[part 8 of 12: packages /Cluster to /E2E]
AUTOSAR XML (schema 4-3-0)
package /Cluster  (continued)
  can cluster BMC_CAN01: baudrate=500000, protocol-name=CAN, protocol-version=2.0, bus-off-recovery={bor-counter-l-1-to-l-2=1, bor-time-l-1=0.05, bor-time-l-2=0.2}  (continued)
    can physical channel CHNL: comm-connectors=CN_BMC_CAN01  (continued)
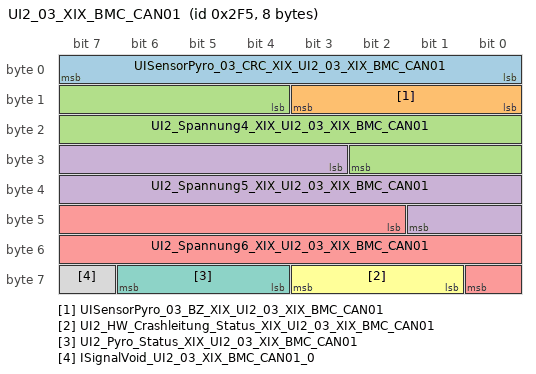
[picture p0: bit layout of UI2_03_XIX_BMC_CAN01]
      frame UI2_03_XIX_BMC_CAN01: id 0x2F5, to BMC_HV, frame-length=8, can-addressing-mode=STANDARD, can-frame-rx-behavior=CAN-20, can-frame-tx-behavior=CAN-20
        pdu UI2_03_XIX_BMC_CAN01_E2E: length=8, transmission-mode-true-timing=event-controlled-timing={number-of-repetitions=0, repetition-period=0}, unused-bit-pattern=0  # Fuer die Botschaft ist das Cyclic-Timing 0.01 zu verwenden.
          signal UISensorPyro_03_CRC_XIX_UI2_03_XIX_BMC_CAN01: start 0, 8 bit, little-endian, data-type-policy=OVERRIDE, i-signal-type=PRIMITIVE, init-value=0, base-type=BT_UISensorPyro_03_CRC, compu {phys=raw for raw 0..255}, range phys 0..255, raw 0..255, to BMC_HV(timeout 0.5 s)
          signal UISensorPyro_03_BZ_XIX_UI2_03_XIX_BMC_CAN01: start 8, 4 bit, little-endian, data-type-policy=OVERRIDE, i-signal-type=PRIMITIVE, init-value=0, base-type=BT_UISensorPyro_03_BZ, compu {phys=raw for raw 0..15}, range phys 0..15, raw 0..15, to BMC_HV(timeout 0.5 s)
          signal UI2_Spannung4_XIX_UI2_03_XIX_BMC_CAN01: start 12, 15 bit, little-endian, data-type-policy=OVERRIDE, i-signal-type=PRIMITIVE, init-value=32766, base-type=BT_UI2_Spannung4, invalid-value=Invalid_UI2_Spannung4_XIX_UI2_03_XIX_BMC_CAN01:32767, compu {phys=raw*0.0625-1023 for raw 0..32763, 32764=Cx7ffc_nicht_messbar (CM_UI2_Spannung4_Cx7ffc_nicht_messbar), 32765=Cx7ffd_nicht_verfuegbar (CM_UI2_Spannung4_Cx7ffd_nicht_verfuegbar), 32766=Cx7ffe_Init (CM_UI2_Spannung4_Cx7ffe_Init), 32767=Cx7fff_Fehler (CM_UI2_Spannung4_Cx7fff_Fehler); unit Unit_Volt}, range phys -1023..1024.6875 Unit_Volt, raw 0..32767, unit=Unit_Volt, to BMC_HV(timeout 0.5 s)  # Spannungsmesskanal 4
          signal UI2_Spannung5_XIX_UI2_03_XIX_BMC_CAN01: start 27, 15 bit, little-endian, data-type-policy=OVERRIDE, i-signal-type=PRIMITIVE, init-value=32766, base-type=BT_UI2_Spannung5, invalid-value=Invalid_UI2_Spannung5_XIX_UI2_03_XIX_BMC_CAN01:32767, compu {phys=raw*0.0625-1023 for raw 0..32763, 32764=Cx7ffc_nicht_messbar (CM_UI2_Spannung5_Cx7ffc_nicht_messbar), 32765=Cx7ffd_nicht_verfuegbar (CM_UI2_Spannung5_Cx7ffd_nicht_verfuegbar), 32766=Cx7ffe_Init (CM_UI2_Spannung5_Cx7ffe_Init), 32767=Cx7fff_Fehler (CM_UI2_Spannung5_Cx7fff_Fehler); unit Unit_Volt}, range phys -1023..1024.6875 Unit_Volt, raw 0..32767, unit=Unit_Volt, to BMC_HV(timeout 0.5 s)  # Spannungsmesskanal 5
          signal UI2_Spannung6_XIX_UI2_03_XIX_BMC_CAN01: start 42, 15 bit, little-endian, data-type-policy=OVERRIDE, i-signal-type=PRIMITIVE, init-value=32766, base-type=BT_UI2_Spannung6, invalid-value=Invalid_UI2_Spannung6_XIX_UI2_03_XIX_BMC_CAN01:32767, compu {phys=raw*0.0625-1023 for raw 0..32763, 32764=Cx7ffc_nicht_messbar (CM_UI2_Spannung6_Cx7ffc_nicht_messbar), 32765=Cx7ffd_nicht_verfuegbar (CM_UI2_Spannung6_Cx7ffd_nicht_verfuegbar), 32766=Cx7ffe_Init (CM_UI2_Spannung6_Cx7ffe_Init), 32767=Cx7fff_Fehler (CM_UI2_Spannung6_Cx7fff_Fehler); unit Unit_Volt}, range phys -1023..1024.6875 Unit_Volt, raw 0..32767, unit=Unit_Volt, to BMC_HV(timeout 0.5 s)  # Spannungsmesskanal 6
          signal UI2_HW_Crashleitung_Status_XIX_UI2_03_XIX_BMC_CAN01: start 57, 3 bit, little-endian, data-type-policy=OVERRIDE, i-signal-type=PRIMITIVE, init-value=0, base-type=BT_UI2_HW_Crashleitung_Status, invalid-value=Invalid_UI2_HW_Crashleitung_Status_XIX_UI2_03_XIX_BMC_CAN01:1, compu {0=Cx0_Init (CM_UI2_HW_Crashleitung_Status_Cx0_Init), 1=Cx1_Fehler (CM_UI2_HW_Crashleitung_Status_Cx1_Fehler), 2=Cx2_iO (CM_UI2_HW_Crashleitung_Status_Cx2_iO), 3=Cx3_Funktion_ausgeloest (CM_UI2_HW_Crashleitung_Status_Cx3_Funktion_ausgeloest)}, range raw 0..3, to BMC_HV(timeout 0.5 s)  # Status der HW-Crashleitung
          signal UI2_Pyro_Status_XIX_UI2_03_XIX_BMC_CAN01: start 60, 3 bit, little-endian, data-type-policy=OVERRIDE, i-signal-type=PRIMITIVE, init-value=0, base-type=BT_UI2_Pyro_Status, invalid-value=Invalid_UI2_Pyro_Status_XIX_UI2_03_XIX_BMC_CAN01:1, compu {0=Cx0_Init (CM_UI2_Pyro_Status_Cx0_Init), 1=Cx1_Fehler (CM_UI2_Pyro_Status_Cx1_Fehler), 2=Cx2_Funktion_verfuegbar (CM_UI2_Pyro_Status_Cx2_Funktion_verfuegbar), 3=Cx3_Funktion_ausgeloest (CM_UI2_Pyro_Status_Cx3_Funktion_ausgeloest), 4=Cx4_Funktion_zuendfaehig (CM_UI2_Pyro_Status_Cx4_Funktion_zuendfaehig)}, range raw 0..4, to BMC_HV(timeout 0.5 s)  # Status für Pyrotrenner
          signal ISignalVoid_UI2_03_XIX_BMC_CAN01_0: start 63, 1 bit, little-endian, system signal SignalVoid_UI2_03_0, data-type-policy=OVERRIDE, i-signal-type=PRIMITIVE, base-type=BT_SignalVoid
          mapping SG_UI2_03_XIX_BMC_CAN01: i-signal-group=SG_UI2_03_XIX_BMC_CAN01, transfer-property=TRIGGERED-WITHOUT-REPETITION
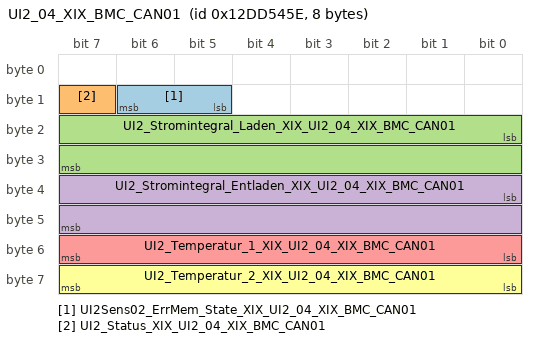
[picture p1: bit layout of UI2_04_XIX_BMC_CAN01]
      frame UI2_04_XIX_BMC_CAN01: id 0x12DD545E, to BMC_HV, frame-length=8, can-addressing-mode=EXTENDED, can-frame-rx-behavior=CAN-20, can-frame-tx-behavior=CAN-20
        pdu UI2_04_XIX_BMC_CAN01: length=8, transmission-mode-true-timing=cyclic-timing={time-offset=0, time-period=0.1}, unused-bit-pattern=0
          signal UI2Sens02_ErrMem_State_XIX_UI2_04_XIX_BMC_CAN01: start 13, 2 bit, little-endian, data-type-policy=OVERRIDE, i-signal-type=PRIMITIVE, init-value=2, base-type=BT_UI2Sens02_ErrMem_State, compu {1=Cx1_ErrMem_Active (CM_UI2Sens02_ErrMem_State_Cx1_ErrMem_Active), 2=Cx2_ErrMem_Init_Progress (CM_UI2Sens02_ErrMem_State_Cx2_ErrMem_Init_Progress), 3=Cx3_ErrMem_Init_Done (CM_UI2Sens02_ErrMem_State_Cx3_ErrMem_Init_Done)}, range raw 1..3, transfer-property=PENDING, to BMC_HV(timeout 1 s)  # Error Memory State
          signal UI2_Status_XIX_UI2_04_XIX_BMC_CAN01: start 15, 1 bit, little-endian, data-type-policy=OVERRIDE, i-signal-type=PRIMITIVE, init-value=0, base-type=BT_UI2_Status, compu {0=Cx0_Init (CM_UI2_Status_Cx0_Init), 1=Cx1_Aktiv (CM_UI2_Status_Cx1_Aktiv)}, range raw 0..1, transfer-property=PENDING, to BMC_HV(timeout 1 s)  # dient zur Signalisierung Neustart oder Reset des UI-Sensors
          signal UI2_Stromintegral_Laden_XIX_UI2_04_XIX_BMC_CAN01: start 16, 16 bit, little-endian, data-type-policy=OVERRIDE, i-signal-type=PRIMITIVE, init-value=65534, base-type=BT_UI2_Stromintegral_Laden, invalid-value=Invalid_UI2_Stromintegral_Laden_XIX_UI2_04_XIX_BMC_CAN01:65535, compu {phys=raw for raw 0..65533, 65534=Cxfffe_Init (CM_UI2_Stromintegral_Laden_Cxfffe_Init), 65535=Cxffff_Fehler (CM_UI2_Stromintegral_Laden_Cxffff_Fehler); unit Unit_AmperSecon}, range phys 0..65533 Unit_AmperSecon, raw 0..65535, unit=Unit_AmperSecon, transfer-property=PENDING, to BMC_HV(timeout 1 s)  # Ladungszaehler des UI-Sensors fuer Laden
          signal UI2_Stromintegral_Entladen_XIX_UI2_04_XIX_BMC_CAN01: start 32, 16 bit, little-endian, data-type-policy=OVERRIDE, i-signal-type=PRIMITIVE, init-value=65534, base-type=BT_UI2_Stromintegral_Entladen, invalid-value=Invalid_UI2_Stromintegral_Entladen_XIX_UI2_04_XIX_BMC_CAN01:65535, compu {phys=raw for raw 0..65533, 65534=Cxfffe_Init (CM_UI2_Stromintegral_Entladen_Cxfffe_Init), 65535=Cxffff_Fehler (CM_UI2_Stromintegral_Entladen_Cxffff_Fehler); unit Unit_AmperSecon}, range phys 0..65533 Unit_AmperSecon, raw 0..65535, unit=Unit_AmperSecon, transfer-property=PENDING, to BMC_HV(timeout 1 s)  # Ladungszaehler des UI-Sensors fuer Entladen
          signal UI2_Temperatur_1_XIX_UI2_04_XIX_BMC_CAN01: start 48, 8 bit, little-endian, data-type-policy=OVERRIDE, i-signal-type=PRIMITIVE, init-value=254, base-type=BT_UI2_Temperatur_1, invalid-value=Invalid_UI2_Temperatur_1_XIX_UI2_04_XIX_BMC_CAN01:255, compu {phys=raw-40 for raw 0..252, 253=Cxfd_nicht_vorhanden (CM_UI2_Temperatur_1_Cxfd_nicht_vorhanden), 254=Cxfe_Init (CM_UI2_Temperatur_1_Cxfe_Init), 255=Cxff_Fehler (CM_UI2_Temperatur_1_Cxff_Fehler); unit Unit_DegreCelsi}, range phys -40..212 Unit_DegreCelsi, raw 0..255, unit=Unit_DegreCelsi, transfer-property=PENDING, to BMC_HV(timeout 1 s)  # Temperatur 1
          signal UI2_Temperatur_2_XIX_UI2_04_XIX_BMC_CAN01: start 56, 8 bit, little-endian, data-type-policy=OVERRIDE, i-signal-type=PRIMITIVE, init-value=254, base-type=BT_UI2_Temperatur_2, invalid-value=Invalid_UI2_Temperatur_2_XIX_UI2_04_XIX_BMC_CAN01:255, compu {phys=raw-40 for raw 0..252, 253=Cxfd_nicht_vorhanden (CM_UI2_Temperatur_2_Cxfd_nicht_vorhanden), 254=Cxfe_Init (CM_UI2_Temperatur_2_Cxfe_Init), 255=Cxff_Fehler (CM_UI2_Temperatur_2_Cxff_Fehler); unit Unit_DegreCelsi}, range phys -40..212 Unit_DegreCelsi, raw 0..255, unit=Unit_DegreCelsi, transfer-property=PENDING, to BMC_HV(timeout 1 s)  # Temperatur 2
      frame UI2_Komponentenfehler_01_XIX_BMC_CAN01: id 0x12DD5520, to BMC_HV, frame-length=8, can-addressing-mode=EXTENDED, can-frame-rx-behavior=CAN-20, can-frame-tx-behavior=CAN-20
        pdu UI2_Komponentenfehler_01_XIX_BMC_CAN01: length=8, transmission-mode-true-timing=cyclic-timing={time-offset=0, time-period=0.1}, unused-bit-pattern=0
          signal UI2_KompFehlerModus2_01_XIX_UI2_Komponentenfehler_01_XIX_BMC_CAN01: start 12, 2 bit, little-endian, data-type-policy=OVERRIDE, i-signal-type=PRIMITIVE, init-value=0, base-type=BT_UI2_KompFehlerModus2_01, compu {0=Cx0_TNCTOC (CM_UI2_KompFehlerModus2_01_Cx0_TNCTOC), 1=Cx1_TP_TC (CM_UI2_KompFehlerModus2_01_Cx1_TP_TC), 2=Cx2_TP_TC_WCMTL (CM_UI2_KompFehlerModus2_01_Cx2_TP_TC_WCMTL), 3=Cx3_TF_TC_Error (CM_UI2_KompFehlerModus2_01_Cx3_TF_TC_Error)}, range raw 0..3, transfer-property=PENDING, to BMC_HV(timeout 1 s)  # Übertragung OBD relevanter Fehlerpfade vom Secondary zum Primary Steuergerät. Zuordnung der generischen Komponentenfehler muss zwischen Sender und Empfänger abgestimmt werden
          signal UI2_KompFehlerModus2_02_XIX_UI2_Komponentenfehler_01_XIX_BMC_CAN01: start 14, 2 bit, little-endian, data-type-policy=OVERRIDE, i-signal-type=PRIMITIVE, init-value=0, base-type=BT_UI2_KompFehlerModus2_02, compu {0=Cx0_TNCTOC (CM_UI2_KompFehlerModus2_02_Cx0_TNCTOC), 1=Cx1_TP_TC (CM_UI2_KompFehlerModus2_02_Cx1_TP_TC), 2=Cx2_TP_TC_WCMTL (CM_UI2_KompFehlerModus2_02_Cx2_TP_TC_WCMTL), 3=Cx3_TF_TC_Error (CM_UI2_KompFehlerModus2_02_Cx3_TF_TC_Error)}, range raw 0..3, transfer-property=PENDING, to BMC_HV(timeout 1 s)  # Übertragung OBD relevanter Fehlerpfade vom Secondary zum Primary Steuergerät. Zuordnung der generischen Komponentenfehler muss zwischen Sender und Empfänger abgestimmt werden
          signal UI2_KompFehlerModus2_03_XIX_UI2_Komponentenfehler_01_XIX_BMC_CAN01: start 16, 2 bit, little-endian, data-type-policy=OVERRIDE, i-signal-type=PRIMITIVE, init-value=0, base-type=BT_UI2_KompFehlerModus2_03, compu {0=Cx0_TNCTOC (CM_UI2_KompFehlerModus2_03_Cx0_TNCTOC), 1=Cx1_TP_TC (CM_UI2_KompFehlerModus2_03_Cx1_TP_TC), 2=Cx2_TP_TC_WCMTL (CM_UI2_KompFehlerModus2_03_Cx2_TP_TC_WCMTL), 3=Cx3_TF_TC_Error (CM_UI2_KompFehlerModus2_03_Cx3_TF_TC_Error)}, range raw 0..3, transfer-property=PENDING, to BMC_HV(timeout 1 s)  # Übertragung OBD relevanter Fehlerpfade vom Secondary zum Primary Steuergerät. Zuordnung der generischen Komponentenfehler muss zwischen Sender und Empfänger abgestimmt werden
          signal UI2_KompFehlerModus2_04_XIX_UI2_Komponentenfehler_01_XIX_BMC_CAN01: start 18, 2 bit, little-endian, data-type-policy=OVERRIDE, i-signal-type=PRIMITIVE, init-value=0, base-type=BT_UI2_KompFehlerModus2_04, compu {0=Cx0_TNCTOC (CM_UI2_KompFehlerModus2_04_Cx0_TNCTOC), 1=Cx1_TP_TC (CM_UI2_KompFehlerModus2_04_Cx1_TP_TC), 2=Cx2_TP_TC_WCMTL (CM_UI2_KompFehlerModus2_04_Cx2_TP_TC_WCMTL), 3=Cx3_TF_TC_Error (CM_UI2_KompFehlerModus2_04_Cx3_TF_TC_Error)}, range raw 0..3, transfer-property=PENDING, to BMC_HV(timeout 1 s)  # Übertragung OBD relevanter Fehlerpfade vom Secondary zum Primary Steuergerät. Zuordnung der generischen Komponentenfehler muss zwischen Sender und Empfänger abgestimmt werden
          signal UI2_KompFehlerModus2_05_XIX_UI2_Komponentenfehler_01_XIX_BMC_CAN01: start 20, 2 bit, little-endian, data-type-policy=OVERRIDE, i-signal-type=PRIMITIVE, init-value=0, base-type=BT_UI2_KompFehlerModus2_05, compu {0=Cx0_TNCTOC (CM_UI2_KompFehlerModus2_05_Cx0_TNCTOC), 1=Cx1_TP_TC (CM_UI2_KompFehlerModus2_05_Cx1_TP_TC), 2=Cx2_TP_TC_WCMTL (CM_UI2_KompFehlerModus2_05_Cx2_TP_TC_WCMTL), 3=Cx3_TF_TC_Error (CM_UI2_KompFehlerModus2_05_Cx3_TF_TC_Error)}, range raw 0..3, transfer-property=PENDING, to BMC_HV(timeout 1 s)  # Übertragung OBD relevanter Fehlerpfade vom Secondary zum Primary Steuergerät. Zuordnung der generischen Komponentenfehler muss zwischen Sender und Empfänger abgestimmt werden
          signal UI2_KompFehlerModus2_06_XIX_UI2_Komponentenfehler_01_XIX_BMC_CAN01: start 22, 2 bit, little-endian, data-type-policy=OVERRIDE, i-signal-type=PRIMITIVE, init-value=0, base-type=BT_UI2_KompFehlerModus2_06, compu {0=Cx0_TNCTOC (CM_UI2_KompFehlerModus2_06_Cx0_TNCTOC), 1=Cx1_TP_TC (CM_UI2_KompFehlerModus2_06_Cx1_TP_TC), 2=Cx2_TP_TC_WCMTL (CM_UI2_KompFehlerModus2_06_Cx2_TP_TC_WCMTL), 3=Cx3_TF_TC_Error (CM_UI2_KompFehlerModus2_06_Cx3_TF_TC_Error)}, range raw 0..3, transfer-property=PENDING, to BMC_HV(timeout 1 s)  # Übertragung OBD relevanter Fehlerpfade vom Secondary zum Primary Steuergerät. Zuordnung der generischen Komponentenfehler muss zwischen Sender und Empfänger abgestimmt werden
          signal UI2_KompFehlerModus2_07_XIX_UI2_Komponentenfehler_01_XIX_BMC_CAN01: start 24, 2 bit, little-endian, data-type-policy=OVERRIDE, i-signal-type=PRIMITIVE, init-value=0, base-type=BT_UI2_KompFehlerModus2_07, compu {0=Cx0_TNCTOC (CM_UI2_KompFehlerModus2_07_Cx0_TNCTOC), 1=Cx1_TP_TC (CM_UI2_KompFehlerModus2_07_Cx1_TP_TC), 2=Cx2_TP_TC_WCMTL (CM_UI2_KompFehlerModus2_07_Cx2_TP_TC_WCMTL), 3=Cx3_TF_TC_Error (CM_UI2_KompFehlerModus2_07_Cx3_TF_TC_Error)}, range raw 0..3, transfer-property=PENDING, to BMC_HV(timeout 1 s)  # Übertragung OBD relevanter Fehlerpfade vom Secondary zum Primary Steuergerät. Zuordnung der generischen Komponentenfehler muss zwischen Sender und Empfänger abgestimmt werden
          signal UI2_KompFehlerModus2_08_XIX_UI2_Komponentenfehler_01_XIX_BMC_CAN01: start 26, 2 bit, little-endian, data-type-policy=OVERRIDE, i-signal-type=PRIMITIVE, init-value=0, base-type=BT_UI2_KompFehlerModus2_08, compu {0=Cx0_TNCTOC (CM_UI2_KompFehlerModus2_08_Cx0_TNCTOC), 1=Cx1_TP_TC (CM_UI2_KompFehlerModus2_08_Cx1_TP_TC), 2=Cx2_TP_TC_WCMTL (CM_UI2_KompFehlerModus2_08_Cx2_TP_TC_WCMTL), 3=Cx3_TF_TC_Error (CM_UI2_KompFehlerModus2_08_Cx3_TF_TC_Error)}, range raw 0..3, transfer-property=PENDING, to BMC_HV(timeout 1 s)  # Übertragung OBD relevanter Fehlerpfade vom Secondary zum Primary Steuergerät. Zuordnung der generischen Komponentenfehler muss zwischen Sender und Empfänger abgestimmt werden
          signal UI2_KompFehlerModus2_09_XIX_UI2_Komponentenfehler_01_XIX_BMC_CAN01: start 28, 2 bit, little-endian, data-type-policy=OVERRIDE, i-signal-type=PRIMITIVE, init-value=0, base-type=BT_UI2_KompFehlerModus2_09, compu {0=Cx0_TNCTOC (CM_UI2_KompFehlerModus2_09_Cx0_TNCTOC), 1=Cx1_TP_TC (CM_UI2_KompFehlerModus2_09_Cx1_TP_TC), 2=Cx2_TP_TC_WCMTL (CM_UI2_KompFehlerModus2_09_Cx2_TP_TC_WCMTL), 3=Cx3_TF_TC_Error (CM_UI2_KompFehlerModus2_09_Cx3_TF_TC_Error)}, range raw 0..3, transfer-property=PENDING, to BMC_HV(timeout 1 s)  # Übertragung OBD relevanter Fehlerpfade vom Secondary zum Primary Steuergerät. Zuordnung der generischen Komponentenfehler muss zwischen Sender und Empfänger abgestimmt werden
          signal UI2_KompFehlerModus2_10_XIX_UI2_Komponentenfehler_01_XIX_BMC_CAN01: start 30, 2 bit, little-endian, data-type-policy=OVERRIDE, i-signal-type=PRIMITIVE, init-value=0, base-type=BT_UI2_KompFehlerModus2_10, compu {0=Cx0_TNCTOC (CM_UI2_KompFehlerModus2_10_Cx0_TNCTOC), 1=Cx1_TP_TC (CM_UI2_KompFehlerModus2_10_Cx1_TP_TC), 2=Cx2_TP_TC_WCMTL (CM_UI2_KompFehlerModus2_10_Cx2_TP_TC_WCMTL), 3=Cx3_TF_TC_Error (CM_UI2_KompFehlerModus2_10_Cx3_TF_TC_Error)}, range raw 0..3, transfer-property=PENDING, to BMC_HV(timeout 1 s)  # Übertragung OBD relevanter Fehlerpfade vom Secondary zum Primary Steuergerät. Zuordnung der generischen Komponentenfehler muss zwischen Sender und Empfänger abgestimmt werden
          signal UI2_KompFehlerModus2_11_XIX_UI2_Komponentenfehler_01_XIX_BMC_CAN01: start 32, 2 bit, little-endian, data-type-policy=OVERRIDE, i-signal-type=PRIMITIVE, init-value=0, base-type=BT_UI2_KompFehlerModus2_11, compu {0=Cx0_TNCTOC (CM_UI2_KompFehlerModus2_11_Cx0_TNCTOC), 1=Cx1_TP_TC (CM_UI2_KompFehlerModus2_11_Cx1_TP_TC), 2=Cx2_TP_TC_WCMTL (CM_UI2_KompFehlerModus2_11_Cx2_TP_TC_WCMTL), 3=Cx3_TF_TC_Error (CM_UI2_KompFehlerModus2_11_Cx3_TF_TC_Error)}, range raw 0..3, transfer-property=PENDING, to BMC_HV(timeout 1 s)  # Übertragung OBD relevanter Fehlerpfade vom Secondary zum Primary Steuergerät. Zuordnung der generischen Komponentenfehler muss zwischen Sender und Empfänger abgestimmt werden
          signal UI2_KompFehlerModus2_12_XIX_UI2_Komponentenfehler_01_XIX_BMC_CAN01: start 34, 2 bit, little-endian, data-type-policy=OVERRIDE, i-signal-type=PRIMITIVE, init-value=0, base-type=BT_UI2_KompFehlerModus2_12, compu {0=Cx0_TNCTOC (CM_UI2_KompFehlerModus2_12_Cx0_TNCTOC), 1=Cx1_TP_TC (CM_UI2_KompFehlerModus2_12_Cx1_TP_TC), 2=Cx2_TP_TC_WCMTL (CM_UI2_KompFehlerModus2_12_Cx2_TP_TC_WCMTL), 3=Cx3_TF_TC_Error (CM_UI2_KompFehlerModus2_12_Cx3_TF_TC_Error)}, range raw 0..3, transfer-property=PENDING, to BMC_HV(timeout 1 s)  # Übertragung OBD relevanter Fehlerpfade vom Secondary zum Primary Steuergerät. Zuordnung der generischen Komponentenfehler muss zwischen Sender und Empfänger abgestimmt werden
          signal UI2_KompFehlerModus2_13_XIX_UI2_Komponentenfehler_01_XIX_BMC_CAN01: start 36, 2 bit, little-endian, data-type-policy=OVERRIDE, i-signal-type=PRIMITIVE, init-value=0, base-type=BT_UI2_KompFehlerModus2_13, compu {0=Cx0_TNCTOC (CM_UI2_KompFehlerModus2_13_Cx0_TNCTOC), 1=Cx1_TP_TC (CM_UI2_KompFehlerModus2_13_Cx1_TP_TC), 2=Cx2_TP_TC_WCMTL (CM_UI2_KompFehlerModus2_13_Cx2_TP_TC_WCMTL), 3=Cx3_TF_TC_Error (CM_UI2_KompFehlerModus2_13_Cx3_TF_TC_Error)}, range raw 0..3, transfer-property=PENDING, to BMC_HV(timeout 1 s)  # Übertragung OBD relevanter Fehlerpfade vom Secondary zum Primary Steuergerät. Zuordnung der generischen Komponentenfehler muss zwischen Sender und Empfänger abgestimmt werden
          signal UI2_KompFehlerModus2_14_XIX_UI2_Komponentenfehler_01_XIX_BMC_CAN01: start 38, 2 bit, little-endian, data-type-policy=OVERRIDE, i-signal-type=PRIMITIVE, init-value=0, base-type=BT_UI2_KompFehlerModus2_14, compu {0=Cx0_TNCTOC (CM_UI2_KompFehlerModus2_14_Cx0_TNCTOC), 1=Cx1_TP_TC (CM_UI2_KompFehlerModus2_14_Cx1_TP_TC), 2=Cx2_TP_TC_WCMTL (CM_UI2_KompFehlerModus2_14_Cx2_TP_TC_WCMTL), 3=Cx3_TF_TC_Error (CM_UI2_KompFehlerModus2_14_Cx3_TF_TC_Error)}, range raw 0..3, transfer-property=PENDING, to BMC_HV(timeout 1 s)  # Übertragung OBD relevanter Fehlerpfade vom Secondary zum Primary Steuergerät. Zuordnung der generischen Komponentenfehler muss zwischen Sender und Empfänger abgestimmt werden
          signal UI2_KompFehlerModus2_15_XIX_UI2_Komponentenfehler_01_XIX_BMC_CAN01: start 40, 2 bit, little-endian, data-type-policy=OVERRIDE, i-signal-type=PRIMITIVE, init-value=0, base-type=BT_UI2_KompFehlerModus2_15, compu {0=Cx0_TNCTOC (CM_UI2_KompFehlerModus2_15_Cx0_TNCTOC), 1=Cx1_TP_TC (CM_UI2_KompFehlerModus2_15_Cx1_TP_TC), 2=Cx2_TP_TC_WCMTL (CM_UI2_KompFehlerModus2_15_Cx2_TP_TC_WCMTL), 3=Cx3_TF_TC_Error (CM_UI2_KompFehlerModus2_15_Cx3_TF_TC_Error)}, range raw 0..3, transfer-property=PENDING, to BMC_HV(timeout 1 s)  # Übertragung OBD relevanter Fehlerpfade vom Secondary zum Primary Steuergerät. Zuordnung der generischen Komponentenfehler muss zwischen Sender und Empfänger abgestimmt werden
          signal UI2_KompFehlerModus2_16_XIX_UI2_Komponentenfehler_01_XIX_BMC_CAN01: start 42, 2 bit, little-endian, data-type-policy=OVERRIDE, i-signal-type=PRIMITIVE, init-value=0, base-type=BT_UI2_KompFehlerModus2_16, compu {0=Cx0_TNCTOC (CM_UI2_KompFehlerModus2_16_Cx0_TNCTOC), 1=Cx1_TP_TC (CM_UI2_KompFehlerModus2_16_Cx1_TP_TC), 2=Cx2_TP_TC_WCMTL (CM_UI2_KompFehlerModus2_16_Cx2_TP_TC_WCMTL), 3=Cx3_TF_TC_Error (CM_UI2_KompFehlerModus2_16_Cx3_TF_TC_Error)}, range raw 0..3, transfer-property=PENDING, to BMC_HV(timeout 1 s)  # Übertragung OBD relevanter Fehlerpfade vom Secondary zum Primary Steuergerät. Zuordnung der generischen Komponentenfehler muss zwischen Sender und Empfänger abgestimmt werden
          signal UI2_KompFehlerModus2_17_XIX_UI2_Komponentenfehler_01_XIX_BMC_CAN01: start 44, 2 bit, little-endian, data-type-policy=OVERRIDE, i-signal-type=PRIMITIVE, init-value=0, base-type=BT_UI2_KompFehlerModus2_17, compu {0=Cx0_TNCTOC (CM_UI2_KompFehlerModus2_17_Cx0_TNCTOC), 1=Cx1_TP_TC (CM_UI2_KompFehlerModus2_17_Cx1_TP_TC), 2=Cx2_TP_TC_WCMTL (CM_UI2_KompFehlerModus2_17_Cx2_TP_TC_WCMTL), 3=Cx3_TF_TC_Error (CM_UI2_KompFehlerModus2_17_Cx3_TF_TC_Error)}, range raw 0..3, transfer-property=PENDING, to BMC_HV(timeout 1 s)  # Übertragung OBD relevanter Fehlerpfade vom Secondary zum Primary Steuergerät. Zuordnung der generischen Komponentenfehler muss zwischen Sender und Empfänger abgestimmt werden
          signal UI2_KompFehlerModus2_18_XIX_UI2_Komponentenfehler_01_XIX_BMC_CAN01: start 46, 2 bit, little-endian, data-type-policy=OVERRIDE, i-signal-type=PRIMITIVE, init-value=0, base-type=BT_UI2_KompFehlerModus2_18, compu {0=Cx0_TNCTOC (CM_UI2_KompFehlerModus2_18_Cx0_TNCTOC), 1=Cx1_TP_TC (CM_UI2_KompFehlerModus2_18_Cx1_TP_TC), 2=Cx2_TP_TC_WCMTL (CM_UI2_KompFehlerModus2_18_Cx2_TP_TC_WCMTL), 3=Cx3_TF_TC_Error (CM_UI2_KompFehlerModus2_18_Cx3_TF_TC_Error)}, range raw 0..3, transfer-property=PENDING, to BMC_HV(timeout 1 s)  # Übertragung OBD relevanter Fehlerpfade vom Secondary zum Primary Steuergerät. Zuordnung der generischen Komponentenfehler muss zwischen Sender und Empfänger abgestimmt werden
          signal UI2_KompFehlerModus2_19_XIX_UI2_Komponentenfehler_01_XIX_BMC_CAN01: start 48, 2 bit, little-endian, data-type-policy=OVERRIDE, i-signal-type=PRIMITIVE, init-value=0, base-type=BT_UI2_KompFehlerModus2_19, compu {0=Cx0_TNCTOC (CM_UI2_KompFehlerModus2_19_Cx0_TNCTOC), 1=Cx1_TP_TC (CM_UI2_KompFehlerModus2_19_Cx1_TP_TC), 2=Cx2_TP_TC_WCMTL (CM_UI2_KompFehlerModus2_19_Cx2_TP_TC_WCMTL), 3=Cx3_TF_TC_Error (CM_UI2_KompFehlerModus2_19_Cx3_TF_TC_Error)}, range raw 0..3, transfer-property=PENDING, to BMC_HV(timeout 1 s)  # Übertragung OBD relevanter Fehlerpfade vom Secondary zum Primary Steuergerät. Zuordnung der generischen Komponentenfehler muss zwischen Sender und Empfänger abgestimmt werden
          signal UI2_KompFehlerModus2_20_XIX_UI2_Komponentenfehler_01_XIX_BMC_CAN01: start 50, 2 bit, little-endian, data-type-policy=OVERRIDE, i-signal-type=PRIMITIVE, init-value=0, base-type=BT_UI2_KompFehlerModus2_20, compu {0=Cx0_TNCTOC (CM_UI2_KompFehlerModus2_20_Cx0_TNCTOC), 1=Cx1_TP_TC (CM_UI2_KompFehlerModus2_20_Cx1_TP_TC), 2=Cx2_TP_TC_WCMTL (CM_UI2_KompFehlerModus2_20_Cx2_TP_TC_WCMTL), 3=Cx3_TF_TC_Error (CM_UI2_KompFehlerModus2_20_Cx3_TF_TC_Error)}, range raw 0..3, transfer-property=PENDING, to BMC_HV(timeout 1 s)  # Übertragung OBD relevanter Fehlerpfade vom Secondary zum Primary Steuergerät. Zuordnung der generischen Komponentenfehler muss zwischen Sender und Empfänger abgestimmt werden
          signal UI2_KompFehlerModus2_21_XIX_UI2_Komponentenfehler_01_XIX_BMC_CAN01: start 52, 2 bit, little-endian, data-type-policy=OVERRIDE, i-signal-type=PRIMITIVE, init-value=0, base-type=BT_UI2_KompFehlerModus2_21, compu {0=Cx0_TNCTOC (CM_UI2_KompFehlerModus2_21_Cx0_TNCTOC), 1=Cx1_TP_TC (CM_UI2_KompFehlerModus2_21_Cx1_TP_TC), 2=Cx2_TP_TC_WCMTL (CM_UI2_KompFehlerModus2_21_Cx2_TP_TC_WCMTL), 3=Cx3_TF_TC_Error (CM_UI2_KompFehlerModus2_21_Cx3_TF_TC_Error)}, range raw 0..3, transfer-property=PENDING, to BMC_HV(timeout 1 s)  # Übertragung OBD relevanter Fehlerpfade vom Secondary zum Primary Steuergerät. Zuordnung der generischen Komponentenfehler muss zwischen Sender und Empfänger abgestimmt werden
          signal UI2_KompFehlerModus2_22_XIX_UI2_Komponentenfehler_01_XIX_BMC_CAN01: start 54, 2 bit, little-endian, data-type-policy=OVERRIDE, i-signal-type=PRIMITIVE, init-value=0, base-type=BT_UI2_KompFehlerModus2_22, compu {0=Cx0_TNCTOC (CM_UI2_KompFehlerModus2_22_Cx0_TNCTOC), 1=Cx1_TP_TC (CM_UI2_KompFehlerModus2_22_Cx1_TP_TC), 2=Cx2_TP_TC_WCMTL (CM_UI2_KompFehlerModus2_22_Cx2_TP_TC_WCMTL), 3=Cx3_TF_TC_Error (CM_UI2_KompFehlerModus2_22_Cx3_TF_TC_Error)}, range raw 0..3, transfer-property=PENDING, to BMC_HV(timeout 1 s)  # Übertragung OBD relevanter Fehlerpfade vom Secondary zum Primary Steuergerät. Zuordnung der generischen Komponentenfehler muss zwischen Sender und Empfänger abgestimmt werden
          signal UI2_KompFehlerModus2_23_XIX_UI2_Komponentenfehler_01_XIX_BMC_CAN01: start 56, 2 bit, little-endian, data-type-policy=OVERRIDE, i-signal-type=PRIMITIVE, init-value=0, base-type=BT_UI2_KompFehlerModus2_23, compu {0=Cx0_TNCTOC (CM_UI2_KompFehlerModus2_23_Cx0_TNCTOC), 1=Cx1_TP_TC (CM_UI2_KompFehlerModus2_23_Cx1_TP_TC), 2=Cx2_TP_TC_WCMTL (CM_UI2_KompFehlerModus2_23_Cx2_TP_TC_WCMTL), 3=Cx3_TF_TC_Error (CM_UI2_KompFehlerModus2_23_Cx3_TF_TC_Error)}, range raw 0..3, transfer-property=PENDING, to BMC_HV(timeout 1 s)  # Übertragung OBD relevanter Fehlerpfade vom Secondary zum Primary Steuergerät. Zuordnung der generischen Komponentenfehler muss zwischen Sender und Empfänger abgestimmt werden
          signal UI2_KompFehlerModus2_24_XIX_UI2_Komponentenfehler_01_XIX_BMC_CAN01: start 58, 2 bit, little-endian, data-type-policy=OVERRIDE, i-signal-type=PRIMITIVE, init-value=0, base-type=BT_UI2_KompFehlerModus2_24, compu {0=Cx0_TNCTOC (CM_UI2_KompFehlerModus2_24_Cx0_TNCTOC), 1=Cx1_TP_TC (CM_UI2_KompFehlerModus2_24_Cx1_TP_TC), 2=Cx2_TP_TC_WCMTL (CM_UI2_KompFehlerModus2_24_Cx2_TP_TC_WCMTL), 3=Cx3_TF_TC_Error (CM_UI2_KompFehlerModus2_24_Cx3_TF_TC_Error)}, range raw 0..3, transfer-property=PENDING, to BMC_HV(timeout 1 s)  # Übertragung OBD relevanter Fehlerpfade vom Secondary zum Primary Steuergerät. Zuordnung der generischen Komponentenfehler muss zwischen Sender und Empfänger abgestimmt werden
          signal UI2_KompFehlerModus2_25_XIX_UI2_Komponentenfehler_01_XIX_BMC_CAN01: start 60, 2 bit, little-endian, data-type-policy=OVERRIDE, i-signal-type=PRIMITIVE, init-value=0, base-type=BT_UI2_KompFehlerModus2_25, compu {0=Cx0_TNCTOC (CM_UI2_KompFehlerModus2_25_Cx0_TNCTOC), 1=Cx1_TP_TC (CM_UI2_KompFehlerModus2_25_Cx1_TP_TC), 2=Cx2_TP_TC_WCMTL (CM_UI2_KompFehlerModus2_25_Cx2_TP_TC_WCMTL), 3=Cx3_TF_TC_Error (CM_UI2_KompFehlerModus2_25_Cx3_TF_TC_Error)}, range raw 0..3, transfer-property=PENDING, to BMC_HV(timeout 1 s)  # Uebertragung OBD relevanter Fehlerpfade vom Secondary zum Primary Steuergeraet. Zuordnung der generischen Komponentenfehler muss zwischen Sender und Empfaenger abgestimmt werden
          signal UI2_KompFehlerModus2_26_XIX_UI2_Komponentenfehler_01_XIX_BMC_CAN01: start 62, 2 bit, little-endian, data-type-policy=OVERRIDE, i-signal-type=PRIMITIVE, init-value=0, base-type=BT_UI2_KompFehlerModus2_26, compu {0=Cx0_TNCTOC (CM_UI2_KompFehlerModus2_26_Cx0_TNCTOC), 1=Cx1_TP_TC (CM_UI2_KompFehlerModus2_26_Cx1_TP_TC), 2=Cx2_TP_TC_WCMTL (CM_UI2_KompFehlerModus2_26_Cx2_TP_TC_WCMTL), 3=Cx3_TF_TC_Error (CM_UI2_KompFehlerModus2_26_Cx3_TF_TC_Error)}, range raw 0..3, transfer-property=PENDING, to BMC_HV(timeout 1 s)  # Uebertragung OBD relevanter Fehlerpfade vom Secondary zum Primary Steuergeraet. Zuordnung der generischen Komponentenfehler muss zwischen Sender und Empfaenger abgestimmt werden
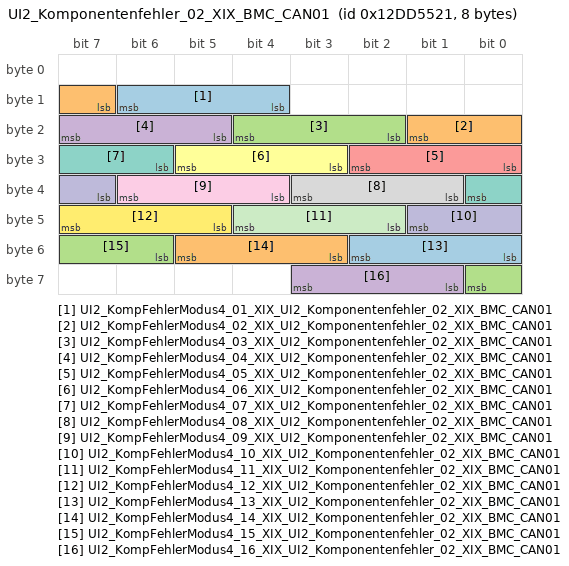
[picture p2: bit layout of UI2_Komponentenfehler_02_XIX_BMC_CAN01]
      frame UI2_Komponentenfehler_02_XIX_BMC_CAN01: id 0x12DD5521, to BMC_HV, frame-length=8, can-addressing-mode=EXTENDED, can-frame-rx-behavior=CAN-20, can-frame-tx-behavior=CAN-20
        pdu UI2_Komponentenfehler_02_XIX_BMC_CAN01: length=8, transmission-mode-true-timing=cyclic-timing={time-offset=0, time-period=0.1}, unused-bit-pattern=0
          signal UI2_KompFehlerModus4_01_XIX_UI2_Komponentenfehler_02_XIX_BMC_CAN01: start 12, 3 bit, little-endian, data-type-policy=OVERRIDE, i-signal-type=PRIMITIVE, init-value=0, base-type=BT_UI2_KompFehlerModus4_01, compu {0=Cx0_TNCTOC (CM_UI2_KompFehlerModus4_01_Cx0_TNCTOC), 1=Cx1_TP_TC (CM_UI2_KompFehlerModus4_01_Cx1_TP_TC), 2=Cx2_TP_TC_WCMTL (CM_UI2_KompFehlerModus4_01_Cx2_TP_TC_WCMTL), 3=Cx3_TF_TC_Error_1 (CM_UI2_KompFehlerModus4_01_Cx3_TF_TC_Error_1), 4=Cx4_TF_TC_Error_2 (CM_UI2_KompFehlerModus4_01_Cx4_TF_TC_Error_2), 5=Cx5_TF_TC_Error_3 (CM_UI2_KompFehlerModus4_01_Cx5_TF_TC_Error_3), 6=Cx6_TF_TC_Error_4 (CM_UI2_KompFehlerModus4_01_Cx6_TF_TC_Error_4), 7=Cx7_TF_TC_Error_5 (CM_UI2_KompFehlerModus4_01_Cx7_TF_TC_Error_5)}, range raw 0..7, transfer-property=PENDING, to BMC_HV(timeout 1 s)  # Übertragung OBD relevanter Fehlerpfade vom Secondary zum Primary Steuergerät. Zuordnung der generischen Komponentenfehler muss zwischen Sender und Empfänger abgestimmt werden (3bit Struktur)
          signal UI2_KompFehlerModus4_02_XIX_UI2_Komponentenfehler_02_XIX_BMC_CAN01: start 15, 3 bit, little-endian, data-type-policy=OVERRIDE, i-signal-type=PRIMITIVE, init-value=0, base-type=BT_UI2_KompFehlerModus4_02, compu {0=Cx0_TNCTOC (CM_UI2_KompFehlerModus4_02_Cx0_TNCTOC), 1=Cx1_TP_TC (CM_UI2_KompFehlerModus4_02_Cx1_TP_TC), 2=Cx2_TP_TC_WCMTL (CM_UI2_KompFehlerModus4_02_Cx2_TP_TC_WCMTL), 3=Cx3_TF_TC_Error_1 (CM_UI2_KompFehlerModus4_02_Cx3_TF_TC_Error_1), 4=Cx4_TF_TC_Error_2 (CM_UI2_KompFehlerModus4_02_Cx4_TF_TC_Error_2), 5=Cx5_TF_TC_Error_3 (CM_UI2_KompFehlerModus4_02_Cx5_TF_TC_Error_3), 6=Cx6_TF_TC_Error_4 (CM_UI2_KompFehlerModus4_02_Cx6_TF_TC_Error_4), 7=Cx7_TF_TC_Error_5 (CM_UI2_KompFehlerModus4_02_Cx7_TF_TC_Error_5)}, range raw 0..7, transfer-property=PENDING, to BMC_HV(timeout 1 s)  # Übertragung OBD relevanter Fehlerpfade vom Secondary zum Primary Steuergerät. Zuordnung der generischen Komponentenfehler muss zwischen Sender und Empfänger abgestimmt werden (3bit Struktur)
          signal UI2_KompFehlerModus4_03_XIX_UI2_Komponentenfehler_02_XIX_BMC_CAN01: start 18, 3 bit, little-endian, data-type-policy=OVERRIDE, i-signal-type=PRIMITIVE, init-value=0, base-type=BT_UI2_KompFehlerModus4_03, compu {0=Cx0_TNCTOC (CM_UI2_KompFehlerModus4_03_Cx0_TNCTOC), 1=Cx1_TP_TC (CM_UI2_KompFehlerModus4_03_Cx1_TP_TC), 2=Cx2_TP_TC_WCMTL (CM_UI2_KompFehlerModus4_03_Cx2_TP_TC_WCMTL), 3=Cx3_TF_TC_Error_1 (CM_UI2_KompFehlerModus4_03_Cx3_TF_TC_Error_1), 4=Cx4_TF_TC_Error_2 (CM_UI2_KompFehlerModus4_03_Cx4_TF_TC_Error_2), 5=Cx5_TF_TC_Error_3 (CM_UI2_KompFehlerModus4_03_Cx5_TF_TC_Error_3), 6=Cx6_TF_TC_Error_4 (CM_UI2_KompFehlerModus4_03_Cx6_TF_TC_Error_4), 7=Cx7_TF_TC_Error_5 (CM_UI2_KompFehlerModus4_03_Cx7_TF_TC_Error_5)}, range raw 0..7, transfer-property=PENDING, to BMC_HV(timeout 1 s)  # Übertragung OBD relevanter Fehlerpfade vom Secondary zum Primary Steuergerät. Zuordnung der generischen Komponentenfehler muss zwischen Sender und Empfänger abgestimmt werden (3bit Struktur)
          signal UI2_KompFehlerModus4_04_XIX_UI2_Komponentenfehler_02_XIX_BMC_CAN01: start 21, 3 bit, little-endian, data-type-policy=OVERRIDE, i-signal-type=PRIMITIVE, init-value=0, base-type=BT_UI2_KompFehlerModus4_04, compu {0=Cx0_TNCTOC (CM_UI2_KompFehlerModus4_04_Cx0_TNCTOC), 1=Cx1_TP_TC (CM_UI2_KompFehlerModus4_04_Cx1_TP_TC), 2=Cx2_TP_TC_WCMTL (CM_UI2_KompFehlerModus4_04_Cx2_TP_TC_WCMTL), 3=Cx3_TF_TC_Error_1 (CM_UI2_KompFehlerModus4_04_Cx3_TF_TC_Error_1), 4=Cx4_TF_TC_Error_2 (CM_UI2_KompFehlerModus4_04_Cx4_TF_TC_Error_2), 5=Cx5_TF_TC_Error_3 (CM_UI2_KompFehlerModus4_04_Cx5_TF_TC_Error_3), 6=Cx6_TF_TC_Error_4 (CM_UI2_KompFehlerModus4_04_Cx6_TF_TC_Error_4), 7=Cx7_TF_TC_Error_5 (CM_UI2_KompFehlerModus4_04_Cx7_TF_TC_Error_5)}, range raw 0..7, transfer-property=PENDING, to BMC_HV(timeout 1 s)  # Übertragung OBD relevanter Fehlerpfade vom Secondary zum Primary Steuergerät. Zuordnung der generischen Komponentenfehler muss zwischen Sender und Empfänger abgestimmt werden (3bit Struktur)
          signal UI2_KompFehlerModus4_05_XIX_UI2_Komponentenfehler_02_XIX_BMC_CAN01: start 24, 3 bit, little-endian, data-type-policy=OVERRIDE, i-signal-type=PRIMITIVE, init-value=0, base-type=BT_UI2_KompFehlerModus4_05, compu {0=Cx0_TNCTOC (CM_UI2_KompFehlerModus4_05_Cx0_TNCTOC), 1=Cx1_TP_TC (CM_UI2_KompFehlerModus4_05_Cx1_TP_TC), 2=Cx2_TP_TC_WCMTL (CM_UI2_KompFehlerModus4_05_Cx2_TP_TC_WCMTL), 3=Cx3_TF_TC_Error_1 (CM_UI2_KompFehlerModus4_05_Cx3_TF_TC_Error_1), 4=Cx4_TF_TC_Error_2 (CM_UI2_KompFehlerModus4_05_Cx4_TF_TC_Error_2), 5=Cx5_TF_TC_Error_3 (CM_UI2_KompFehlerModus4_05_Cx5_TF_TC_Error_3), 6=Cx6_TF_TC_Error_4 (CM_UI2_KompFehlerModus4_05_Cx6_TF_TC_Error_4), 7=Cx7_TF_TC_Error_5 (CM_UI2_KompFehlerModus4_05_Cx7_TF_TC_Error_5)}, range raw 0..7, transfer-property=PENDING, to BMC_HV(timeout 1 s)  # Übertragung OBD relevanter Fehlerpfade vom Secondary zum Primary Steuergerät. Zuordnung der generischen Komponentenfehler muss zwischen Sender und Empfänger abgestimmt werden (3bit Struktur)
          signal UI2_KompFehlerModus4_06_XIX_UI2_Komponentenfehler_02_XIX_BMC_CAN01: start 27, 3 bit, little-endian, data-type-policy=OVERRIDE, i-signal-type=PRIMITIVE, init-value=0, base-type=BT_UI2_KompFehlerModus4_06, compu {0=Cx0_TNCTOC (CM_UI2_KompFehlerModus4_06_Cx0_TNCTOC), 1=Cx1_TP_TC (CM_UI2_KompFehlerModus4_06_Cx1_TP_TC), 2=Cx2_TP_TC_WCMTL (CM_UI2_KompFehlerModus4_06_Cx2_TP_TC_WCMTL), 3=Cx3_TF_TC_Error_1 (CM_UI2_KompFehlerModus4_06_Cx3_TF_TC_Error_1), 4=Cx4_TF_TC_Error_2 (CM_UI2_KompFehlerModus4_06_Cx4_TF_TC_Error_2), 5=Cx5_TF_TC_Error_3 (CM_UI2_KompFehlerModus4_06_Cx5_TF_TC_Error_3), 6=Cx6_TF_TC_Error_4 (CM_UI2_KompFehlerModus4_06_Cx6_TF_TC_Error_4), 7=Cx7_TF_TC_Error_5 (CM_UI2_KompFehlerModus4_06_Cx7_TF_TC_Error_5)}, range raw 0..7, transfer-property=PENDING, to BMC_HV(timeout 1 s)  # Übertragung OBD relevanter Fehlerpfade vom Secondary zum Primary Steuergerät. Zuordnung der generischen Komponentenfehler muss zwischen Sender und Empfänger abgestimmt werden (3bit Struktur)
          signal UI2_KompFehlerModus4_07_XIX_UI2_Komponentenfehler_02_XIX_BMC_CAN01: start 30, 3 bit, little-endian, data-type-policy=OVERRIDE, i-signal-type=PRIMITIVE, init-value=0, base-type=BT_UI2_KompFehlerModus4_07, compu {0=Cx0_TNCTOC (CM_UI2_KompFehlerModus4_07_Cx0_TNCTOC), 1=Cx1_TP_TC (CM_UI2_KompFehlerModus4_07_Cx1_TP_TC), 2=Cx2_TP_TC_WCMTL (CM_UI2_KompFehlerModus4_07_Cx2_TP_TC_WCMTL), 3=Cx3_TF_TC_Error_1 (CM_UI2_KompFehlerModus4_07_Cx3_TF_TC_Error_1), 4=Cx4_TF_TC_Error_2 (CM_UI2_KompFehlerModus4_07_Cx4_TF_TC_Error_2), 5=Cx5_TF_TC_Error_3 (CM_UI2_KompFehlerModus4_07_Cx5_TF_TC_Error_3), 6=Cx6_TF_TC_Error_4 (CM_UI2_KompFehlerModus4_07_Cx6_TF_TC_Error_4), 7=Cx7_TF_TC_Error_5 (CM_UI2_KompFehlerModus4_07_Cx7_TF_TC_Error_5)}, range raw 0..7, transfer-property=PENDING, to BMC_HV(timeout 1 s)  # Übertragung OBD relevanter Fehlerpfade vom Secondary zum Primary Steuergerät. Zuordnung der generischen Komponentenfehler muss zwischen Sender und Empfänger abgestimmt werden (3bit Struktur)
          signal UI2_KompFehlerModus4_08_XIX_UI2_Komponentenfehler_02_XIX_BMC_CAN01: start 33, 3 bit, little-endian, data-type-policy=OVERRIDE, i-signal-type=PRIMITIVE, init-value=0, base-type=BT_UI2_KompFehlerModus4_08, compu {0=Cx0_TNCTOC (CM_UI2_KompFehlerModus4_08_Cx0_TNCTOC), 1=Cx1_TP_TC (CM_UI2_KompFehlerModus4_08_Cx1_TP_TC), 2=Cx2_TP_TC_WCMTL (CM_UI2_KompFehlerModus4_08_Cx2_TP_TC_WCMTL), 3=Cx3_TF_TC_Error_1 (CM_UI2_KompFehlerModus4_08_Cx3_TF_TC_Error_1), 4=Cx4_TF_TC_Error_2 (CM_UI2_KompFehlerModus4_08_Cx4_TF_TC_Error_2), 5=Cx5_TF_TC_Error_3 (CM_UI2_KompFehlerModus4_08_Cx5_TF_TC_Error_3), 6=Cx6_TF_TC_Error_4 (CM_UI2_KompFehlerModus4_08_Cx6_TF_TC_Error_4), 7=Cx7_TF_TC_Error_5 (CM_UI2_KompFehlerModus4_08_Cx7_TF_TC_Error_5)}, range raw 0..7, transfer-property=PENDING, to BMC_HV(timeout 1 s)  # Übertragung OBD relevanter Fehlerpfade vom Secondary zum Primary Steuergerät. Zuordnung der generischen Komponentenfehler muss zwischen Sender und Empfänger abgestimmt werden (3bit Struktur)
          signal UI2_KompFehlerModus4_09_XIX_UI2_Komponentenfehler_02_XIX_BMC_CAN01: start 36, 3 bit, little-endian, data-type-policy=OVERRIDE, i-signal-type=PRIMITIVE, init-value=0, base-type=BT_UI2_KompFehlerModus4_09, compu {0=Cx0_TNCTOC (CM_UI2_KompFehlerModus4_09_Cx0_TNCTOC), 1=Cx1_TP_TC (CM_UI2_KompFehlerModus4_09_Cx1_TP_TC), 2=Cx2_TP_TC_WCMTL (CM_UI2_KompFehlerModus4_09_Cx2_TP_TC_WCMTL), 3=Cx3_TF_TC_Error_1 (CM_UI2_KompFehlerModus4_09_Cx3_TF_TC_Error_1), 4=Cx4_TF_TC_Error_2 (CM_UI2_KompFehlerModus4_09_Cx4_TF_TC_Error_2), 5=Cx5_TF_TC_Error_3 (CM_UI2_KompFehlerModus4_09_Cx5_TF_TC_Error_3), 6=Cx6_TF_TC_Error_4 (CM_UI2_KompFehlerModus4_09_Cx6_TF_TC_Error_4), 7=Cx7_TF_TC_Error_5 (CM_UI2_KompFehlerModus4_09_Cx7_TF_TC_Error_5)}, range raw 0..7, transfer-property=PENDING, to BMC_HV(timeout 1 s)  # Übertragung OBD relevanter Fehlerpfade vom Secondary zum Primary Steuergerät. Zuordnung der generischen Komponentenfehler muss zwischen Sender und Empfänger abgestimmt werden (3bit Struktur)
          signal UI2_KompFehlerModus4_10_XIX_UI2_Komponentenfehler_02_XIX_BMC_CAN01: start 39, 3 bit, little-endian, data-type-policy=OVERRIDE, i-signal-type=PRIMITIVE, init-value=0, base-type=BT_UI2_KompFehlerModus4_10, compu {0=Cx0_TNCTOC (CM_UI2_KompFehlerModus4_10_Cx0_TNCTOC), 1=Cx1_TP_TC (CM_UI2_KompFehlerModus4_10_Cx1_TP_TC), 2=Cx2_TP_TC_WCMTL (CM_UI2_KompFehlerModus4_10_Cx2_TP_TC_WCMTL), 3=Cx3_TF_TC_Error_1 (CM_UI2_KompFehlerModus4_10_Cx3_TF_TC_Error_1), 4=Cx4_TF_TC_Error_2 (CM_UI2_KompFehlerModus4_10_Cx4_TF_TC_Error_2), 5=Cx5_TF_TC_Error_3 (CM_UI2_KompFehlerModus4_10_Cx5_TF_TC_Error_3), 6=Cx6_TF_TC_Error_4 (CM_UI2_KompFehlerModus4_10_Cx6_TF_TC_Error_4), 7=Cx7_TF_TC_Error_5 (CM_UI2_KompFehlerModus4_10_Cx7_TF_TC_Error_5)}, range raw 0..7, transfer-property=PENDING, to BMC_HV(timeout 1 s)  # Übertragung OBD relevanter Fehlerpfade vom Secondary zum Primary Steuergerät. Zuordnung der generischen Komponentenfehler muss zwischen Sender und Empfänger abgestimmt werden (3bit Struktur)
          signal UI2_KompFehlerModus4_11_XIX_UI2_Komponentenfehler_02_XIX_BMC_CAN01: start 42, 3 bit, little-endian, data-type-policy=OVERRIDE, i-signal-type=PRIMITIVE, init-value=0, base-type=BT_UI2_KompFehlerModus4_11, compu {0=Cx0_TNCTOC (CM_UI2_KompFehlerModus4_11_Cx0_TNCTOC), 1=Cx1_TP_TC (CM_UI2_KompFehlerModus4_11_Cx1_TP_TC), 2=Cx2_TP_TC_WCMTL (CM_UI2_KompFehlerModus4_11_Cx2_TP_TC_WCMTL), 3=Cx3_TF_TC_Error_1 (CM_UI2_KompFehlerModus4_11_Cx3_TF_TC_Error_1), 4=Cx4_TF_TC_Error_2 (CM_UI2_KompFehlerModus4_11_Cx4_TF_TC_Error_2), 5=Cx5_TF_TC_Error_3 (CM_UI2_KompFehlerModus4_11_Cx5_TF_TC_Error_3), 6=Cx6_TF_TC_Error_4 (CM_UI2_KompFehlerModus4_11_Cx6_TF_TC_Error_4), 7=Cx7_TF_TC_Error_5 (CM_UI2_KompFehlerModus4_11_Cx7_TF_TC_Error_5)}, range raw 0..7, transfer-property=PENDING, to BMC_HV(timeout 1 s)  # Übertragung OBD relevanter Fehlerpfade vom Secondary zum Primary Steuergerät. Zuordnung der generischen Komponentenfehler muss zwischen Sender und Empfänger abgestimmt werden (3bit Struktur)
          signal UI2_KompFehlerModus4_12_XIX_UI2_Komponentenfehler_02_XIX_BMC_CAN01: start 45, 3 bit, little-endian, data-type-policy=OVERRIDE, i-signal-type=PRIMITIVE, init-value=0, base-type=BT_UI2_KompFehlerModus4_12, compu {0=Cx0_TNCTOC (CM_UI2_KompFehlerModus4_12_Cx0_TNCTOC), 1=Cx1_TP_TC (CM_UI2_KompFehlerModus4_12_Cx1_TP_TC), 2=Cx2_TP_TC_WCMTL (CM_UI2_KompFehlerModus4_12_Cx2_TP_TC_WCMTL), 3=Cx3_TF_TC_Error_1 (CM_UI2_KompFehlerModus4_12_Cx3_TF_TC_Error_1), 4=Cx4_TF_TC_Error_2 (CM_UI2_KompFehlerModus4_12_Cx4_TF_TC_Error_2), 5=Cx5_TF_TC_Error_3 (CM_UI2_KompFehlerModus4_12_Cx5_TF_TC_Error_3), 6=Cx6_TF_TC_Error_4 (CM_UI2_KompFehlerModus4_12_Cx6_TF_TC_Error_4), 7=Cx7_TF_TC_Error_5 (CM_UI2_KompFehlerModus4_12_Cx7_TF_TC_Error_5)}, range raw 0..7, transfer-property=PENDING, to BMC_HV(timeout 1 s)  # Übertragung OBD relevanter Fehlerpfade vom Secondary zum Primary Steuergerät. Zuordnung der generischen Komponentenfehler muss zwischen Sender und Empfänger abgestimmt werden (3bit Struktur)
          signal UI2_KompFehlerModus4_13_XIX_UI2_Komponentenfehler_02_XIX_BMC_CAN01: start 48, 3 bit, little-endian, data-type-policy=OVERRIDE, i-signal-type=PRIMITIVE, init-value=0, base-type=BT_UI2_KompFehlerModus4_13, compu {0=Cx0_TNCTOC (CM_UI2_KompFehlerModus4_13_Cx0_TNCTOC), 1=Cx1_TP_TC (CM_UI2_KompFehlerModus4_13_Cx1_TP_TC), 2=Cx2_TP_TC_WCMTL (CM_UI2_KompFehlerModus4_13_Cx2_TP_TC_WCMTL), 3=Cx3_TF_TC_Error_1 (CM_UI2_KompFehlerModus4_13_Cx3_TF_TC_Error_1), 4=Cx4_TF_TC_Error_2 (CM_UI2_KompFehlerModus4_13_Cx4_TF_TC_Error_2), 5=Cx5_TF_TC_Error_3 (CM_UI2_KompFehlerModus4_13_Cx5_TF_TC_Error_3), 6=Cx6_TF_TC_Error_4 (CM_UI2_KompFehlerModus4_13_Cx6_TF_TC_Error_4), 7=Cx7_TF_TC_Error_5 (CM_UI2_KompFehlerModus4_13_Cx7_TF_TC_Error_5)}, range raw 0..7, transfer-property=PENDING, to BMC_HV(timeout 1 s)  # Übertragung OBD relevanter Fehlerpfade vom Secondary zum Primary Steuergerät. Zuordnung der generischen Komponentenfehler muss zwischen Sender und Empfänger abgestimmt werden (3bit Struktur)
          signal UI2_KompFehlerModus4_14_XIX_UI2_Komponentenfehler_02_XIX_BMC_CAN01: start 51, 3 bit, little-endian, data-type-policy=OVERRIDE, i-signal-type=PRIMITIVE, init-value=0, base-type=BT_UI2_KompFehlerModus4_14, compu {0=Cx0_TNCTOC (CM_UI2_KompFehlerModus4_14_Cx0_TNCTOC), 1=Cx1_TP_TC (CM_UI2_KompFehlerModus4_14_Cx1_TP_TC), 2=Cx2_TP_TC_WCMTL (CM_UI2_KompFehlerModus4_14_Cx2_TP_TC_WCMTL), 3=Cx3_TF_TC_Error_1 (CM_UI2_KompFehlerModus4_14_Cx3_TF_TC_Error_1), 4=Cx4_TF_TC_Error_2 (CM_UI2_KompFehlerModus4_14_Cx4_TF_TC_Error_2), 5=Cx5_TF_TC_Error_3 (CM_UI2_KompFehlerModus4_14_Cx5_TF_TC_Error_3), 6=Cx6_TF_TC_Error_4 (CM_UI2_KompFehlerModus4_14_Cx6_TF_TC_Error_4), 7=Cx7_TF_TC_Error_5 (CM_UI2_KompFehlerModus4_14_Cx7_TF_TC_Error_5)}, range raw 0..7, transfer-property=PENDING, to BMC_HV(timeout 1 s)  # Übertragung OBD relevanter Fehlerpfade vom Secondary zum Primary Steuergerät. Zuordnung der generischen Komponentenfehler muss zwischen Sender und Empfänger abgestimmt werden (3bit Struktur)
          signal UI2_KompFehlerModus4_15_XIX_UI2_Komponentenfehler_02_XIX_BMC_CAN01: start 54, 3 bit, little-endian, data-type-policy=OVERRIDE, i-signal-type=PRIMITIVE, init-value=0, base-type=BT_UI2_KompFehlerModus4_15, compu {0=Cx0_TNCTOC (CM_UI2_KompFehlerModus4_15_Cx0_TNCTOC), 1=Cx1_TP_TC (CM_UI2_KompFehlerModus4_15_Cx1_TP_TC), 2=Cx2_TP_TC_WCMTL (CM_UI2_KompFehlerModus4_15_Cx2_TP_TC_WCMTL), 3=Cx3_TF_TC_Error_1 (CM_UI2_KompFehlerModus4_15_Cx3_TF_TC_Error_1), 4=Cx4_TF_TC_Error_2 (CM_UI2_KompFehlerModus4_15_Cx4_TF_TC_Error_2), 5=Cx5_TF_TC_Error_3 (CM_UI2_KompFehlerModus4_15_Cx5_TF_TC_Error_3), 6=Cx6_TF_TC_Error_4 (CM_UI2_KompFehlerModus4_15_Cx6_TF_TC_Error_4), 7=Cx7_TF_TC_Error_5 (CM_UI2_KompFehlerModus4_15_Cx7_TF_TC_Error_5)}, range raw 0..7, transfer-property=PENDING, to BMC_HV(timeout 1 s)  # Übertragung OBD relevanter Fehlerpfade vom Secondary zum Primary Steuergerät. Zuordnung der generischen Komponentenfehler muss zwischen Sender und Empfänger abgestimmt werden (3bit Struktur)
          signal UI2_KompFehlerModus4_16_XIX_UI2_Komponentenfehler_02_XIX_BMC_CAN01: start 57, 3 bit, little-endian, data-type-policy=OVERRIDE, i-signal-type=PRIMITIVE, init-value=0, base-type=BT_UI2_KompFehlerModus4_16, compu {0=Cx0_TNCTOC (CM_UI2_KompFehlerModus4_16_Cx0_TNCTOC), 1=Cx1_TP_TC (CM_UI2_KompFehlerModus4_16_Cx1_TP_TC), 2=Cx2_TP_TC_WCMTL (CM_UI2_KompFehlerModus4_16_Cx2_TP_TC_WCMTL), 3=Cx3_TF_TC_Error_1 (CM_UI2_KompFehlerModus4_16_Cx3_TF_TC_Error_1), 4=Cx4_TF_TC_Error_2 (CM_UI2_KompFehlerModus4_16_Cx4_TF_TC_Error_2), 5=Cx5_TF_TC_Error_3 (CM_UI2_KompFehlerModus4_16_Cx5_TF_TC_Error_3), 6=Cx6_TF_TC_Error_4 (CM_UI2_KompFehlerModus4_16_Cx6_TF_TC_Error_4), 7=Cx7_TF_TC_Error_5 (CM_UI2_KompFehlerModus4_16_Cx7_TF_TC_Error_5)}, range raw 0..7, transfer-property=PENDING, to BMC_HV(timeout 1 s)  # Übertragung OBD relevanter Fehlerpfade vom Secondary zum Primary Steuergerät. Zuordnung der generischen Komponentenfehler muss zwischen Sender und Empfänger abgestimmt werden (3bit Struktur)
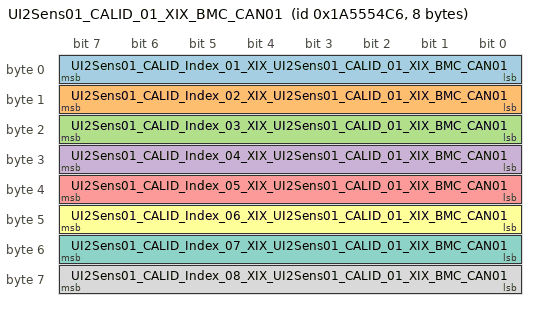
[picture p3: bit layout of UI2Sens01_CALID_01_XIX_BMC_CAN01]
      frame UI2Sens01_CALID_01_XIX_BMC_CAN01: id 0x1A5554C6, to BMC_HV, frame-length=8, can-addressing-mode=EXTENDED, can-frame-rx-behavior=CAN-20, can-frame-tx-behavior=CAN-20
        pdu UI2Sens01_CALID_01_XIX_BMC_CAN01: length=8, transmission-mode-true-timing=cyclic-timing={time-offset=0, time-period=1}, unused-bit-pattern=0
          signal UI2Sens01_CALID_Index_01_XIX_UI2Sens01_CALID_01_XIX_BMC_CAN01: start 0, 8 bit, little-endian, data-type-policy=OVERRIDE, i-signal-type=PRIMITIVE, init-value=63, base-type=BT_UI2Sens01_CALID_Index_01, compu {phys=raw for raw 0..255}, range phys 0..255, raw 0..255, transfer-property=PENDING, to BMC_HV(timeout 5 s)  # Calibration Identification
          signal UI2Sens01_CALID_Index_02_XIX_UI2Sens01_CALID_01_XIX_BMC_CAN01: start 8, 8 bit, little-endian, data-type-policy=OVERRIDE, i-signal-type=PRIMITIVE, init-value=63, base-type=BT_UI2Sens01_CALID_Index_02, compu {phys=raw for raw 0..255}, range phys 0..255, raw 0..255, transfer-property=PENDING, to BMC_HV(timeout 5 s)  # Calibration Identification
          signal UI2Sens01_CALID_Index_03_XIX_UI2Sens01_CALID_01_XIX_BMC_CAN01: start 16, 8 bit, little-endian, data-type-policy=OVERRIDE, i-signal-type=PRIMITIVE, init-value=63, base-type=BT_UI2Sens01_CALID_Index_03, compu {phys=raw for raw 0..255}, range phys 0..255, raw 0..255, transfer-property=PENDING, to BMC_HV(timeout 5 s)  # Calibration Identification
          signal UI2Sens01_CALID_Index_04_XIX_UI2Sens01_CALID_01_XIX_BMC_CAN01: start 24, 8 bit, little-endian, data-type-policy=OVERRIDE, i-signal-type=PRIMITIVE, init-value=63, base-type=BT_UI2Sens01_CALID_Index_04, compu {phys=raw for raw 0..255}, range phys 0..255, raw 0..255, transfer-property=PENDING, to BMC_HV(timeout 5 s)  # Calibration Identification
          signal UI2Sens01_CALID_Index_05_XIX_UI2Sens01_CALID_01_XIX_BMC_CAN01: start 32, 8 bit, little-endian, data-type-policy=OVERRIDE, i-signal-type=PRIMITIVE, init-value=63, base-type=BT_UI2Sens01_CALID_Index_05, compu {phys=raw for raw 0..255}, range phys 0..255, raw 0..255, transfer-property=PENDING, to BMC_HV(timeout 5 s)  # Calibration Identification
          signal UI2Sens01_CALID_Index_06_XIX_UI2Sens01_CALID_01_XIX_BMC_CAN01: start 40, 8 bit, little-endian, data-type-policy=OVERRIDE, i-signal-type=PRIMITIVE, init-value=63, base-type=BT_UI2Sens01_CALID_Index_06, compu {phys=raw for raw 0..255}, range phys 0..255, raw 0..255, transfer-property=PENDING, to BMC_HV(timeout 5 s)  # Calibration Identification
          signal UI2Sens01_CALID_Index_07_XIX_UI2Sens01_CALID_01_XIX_BMC_CAN01: start 48, 8 bit, little-endian, data-type-policy=OVERRIDE, i-signal-type=PRIMITIVE, init-value=63, base-type=BT_UI2Sens01_CALID_Index_07, compu {phys=raw for raw 0..255}, range phys 0..255, raw 0..255, transfer-property=PENDING, to BMC_HV(timeout 5 s)  # Calibration Identification
          signal UI2Sens01_CALID_Index_08_XIX_UI2Sens01_CALID_01_XIX_BMC_CAN01: start 56, 8 bit, little-endian, data-type-policy=OVERRIDE, i-signal-type=PRIMITIVE, init-value=63, base-type=BT_UI2Sens01_CALID_Index_08, compu {phys=raw for raw 0..255}, range phys 0..255, raw 0..255, transfer-property=PENDING, to BMC_HV(timeout 5 s)  # Calibration Identification
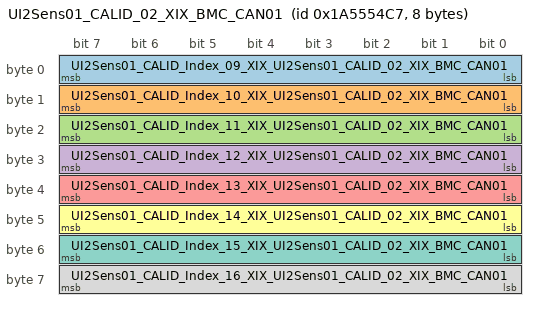
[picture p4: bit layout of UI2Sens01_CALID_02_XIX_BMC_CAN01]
      frame UI2Sens01_CALID_02_XIX_BMC_CAN01: id 0x1A5554C7, to BMC_HV, frame-length=8, can-addressing-mode=EXTENDED, can-frame-rx-behavior=CAN-20, can-frame-tx-behavior=CAN-20
        pdu UI2Sens01_CALID_02_XIX_BMC_CAN01: length=8, transmission-mode-true-timing=cyclic-timing={time-offset=0, time-period=1}, unused-bit-pattern=0
          signal UI2Sens01_CALID_Index_09_XIX_UI2Sens01_CALID_02_XIX_BMC_CAN01: start 0, 8 bit, little-endian, data-type-policy=OVERRIDE, i-signal-type=PRIMITIVE, init-value=63, base-type=BT_UI2Sens01_CALID_Index_09, compu {phys=raw for raw 0..255}, range phys 0..255, raw 0..255, transfer-property=PENDING, to BMC_HV(timeout 5 s)  # Calibration Identification
          signal UI2Sens01_CALID_Index_10_XIX_UI2Sens01_CALID_02_XIX_BMC_CAN01: start 8, 8 bit, little-endian, data-type-policy=OVERRIDE, i-signal-type=PRIMITIVE, init-value=63, base-type=BT_UI2Sens01_CALID_Index_10, compu {phys=raw for raw 0..255}, range phys 0..255, raw 0..255, transfer-property=PENDING, to BMC_HV(timeout 5 s)  # Calibration Identification
          signal UI2Sens01_CALID_Index_11_XIX_UI2Sens01_CALID_02_XIX_BMC_CAN01: start 16, 8 bit, little-endian, data-type-policy=OVERRIDE, i-signal-type=PRIMITIVE, init-value=63, base-type=BT_UI2Sens01_CALID_Index_11, compu {phys=raw for raw 0..255}, range phys 0..255, raw 0..255, transfer-property=PENDING, to BMC_HV(timeout 5 s)  # Calibration Identification
          signal UI2Sens01_CALID_Index_12_XIX_UI2Sens01_CALID_02_XIX_BMC_CAN01: start 24, 8 bit, little-endian, data-type-policy=OVERRIDE, i-signal-type=PRIMITIVE, init-value=63, base-type=BT_UI2Sens01_CALID_Index_12, compu {phys=raw for raw 0..255}, range phys 0..255, raw 0..255, transfer-property=PENDING, to BMC_HV(timeout 5 s)  # Calibration Identification
          signal UI2Sens01_CALID_Index_13_XIX_UI2Sens01_CALID_02_XIX_BMC_CAN01: start 32, 8 bit, little-endian, data-type-policy=OVERRIDE, i-signal-type=PRIMITIVE, init-value=63, base-type=BT_UI2Sens01_CALID_Index_13, compu {phys=raw for raw 0..255}, range phys 0..255, raw 0..255, transfer-property=PENDING, to BMC_HV(timeout 5 s)  # Calibration Identification
          signal UI2Sens01_CALID_Index_14_XIX_UI2Sens01_CALID_02_XIX_BMC_CAN01: start 40, 8 bit, little-endian, data-type-policy=OVERRIDE, i-signal-type=PRIMITIVE, init-value=63, base-type=BT_UI2Sens01_CALID_Index_14, compu {phys=raw for raw 0..255}, range phys 0..255, raw 0..255, transfer-property=PENDING, to BMC_HV(timeout 5 s)  # Calibration Identification
          signal UI2Sens01_CALID_Index_15_XIX_UI2Sens01_CALID_02_XIX_BMC_CAN01: start 48, 8 bit, little-endian, data-type-policy=OVERRIDE, i-signal-type=PRIMITIVE, init-value=63, base-type=BT_UI2Sens01_CALID_Index_15, compu {phys=raw for raw 0..255}, range phys 0..255, raw 0..255, transfer-property=PENDING, to BMC_HV(timeout 5 s)  # Calibration Identification
          signal UI2Sens01_CALID_Index_16_XIX_UI2Sens01_CALID_02_XIX_BMC_CAN01: start 56, 8 bit, little-endian, data-type-policy=OVERRIDE, i-signal-type=PRIMITIVE, init-value=63, base-type=BT_UI2Sens01_CALID_Index_16, compu {phys=raw for raw 0..255}, range phys 0..255, raw 0..255, transfer-property=PENDING, to BMC_HV(timeout 5 s)  # Calibration Identification
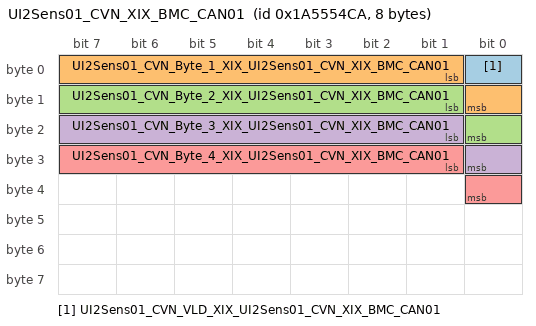
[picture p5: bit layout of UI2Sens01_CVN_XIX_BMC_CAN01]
      frame UI2Sens01_CVN_XIX_BMC_CAN01: id 0x1A5554CA, to BMC_HV, frame-length=8, can-addressing-mode=EXTENDED, can-frame-rx-behavior=CAN-20, can-frame-tx-behavior=CAN-20
        pdu UI2Sens01_CVN_XIX_BMC_CAN01: length=8, transmission-mode-true-timing=cyclic-timing={time-offset=0, time-period=1}, unused-bit-pattern=0
          signal UI2Sens01_CVN_VLD_XIX_UI2Sens01_CVN_XIX_BMC_CAN01: start 0, 1 bit, little-endian, data-type-policy=OVERRIDE, i-signal-type=PRIMITIVE, init-value=0, base-type=BT_UI2Sens01_CVN_VLD, compu {0=Cx0_Ungueltig (CM_UI2Sens01_CVN_VLD_Cx0_Ungueltig), 1=Cx1_Gueltig (CM_UI2Sens01_CVN_VLD_Cx1_Gueltig)}, range raw 0..1, transfer-property=PENDING, to BMC_HV(timeout 5 s)  # Über dieses Signal wird gekennzeichnet, ob die Berechnung der CVN im SecondaryOBDECU abgeschlossen ist.
          signal UI2Sens01_CVN_Byte_1_XIX_UI2Sens01_CVN_XIX_BMC_CAN01: start 1, 8 bit, little-endian, data-type-policy=OVERRIDE, i-signal-type=PRIMITIVE, init-value=0, base-type=BT_UI2Sens01_CVN_Byte_1, compu {phys=raw for raw 0..255}, range phys 0..255, raw 0..255, transfer-property=PENDING, to BMC_HV(timeout 5 s)  # Calibration Verification Number
          signal UI2Sens01_CVN_Byte_2_XIX_UI2Sens01_CVN_XIX_BMC_CAN01: start 9, 8 bit, little-endian, data-type-policy=OVERRIDE, i-signal-type=PRIMITIVE, init-value=0, base-type=BT_UI2Sens01_CVN_Byte_2, compu {phys=raw for raw 0..255}, range phys 0..255, raw 0..255, transfer-property=PENDING, to BMC_HV(timeout 5 s)  # Calibration Verification Number
          signal UI2Sens01_CVN_Byte_3_XIX_UI2Sens01_CVN_XIX_BMC_CAN01: start 17, 8 bit, little-endian, data-type-policy=OVERRIDE, i-signal-type=PRIMITIVE, init-value=0, base-type=BT_UI2Sens01_CVN_Byte_3, compu {phys=raw for raw 0..255}, range phys 0..255, raw 0..255, transfer-property=PENDING, to BMC_HV(timeout 5 s)  # Calibration Verification Number
          signal UI2Sens01_CVN_Byte_4_XIX_UI2Sens01_CVN_XIX_BMC_CAN01: start 25, 8 bit, little-endian, data-type-policy=OVERRIDE, i-signal-type=PRIMITIVE, init-value=0, base-type=BT_UI2Sens01_CVN_Byte_4, compu {phys=raw for raw 0..255}, range phys 0..255, raw 0..255, transfer-property=PENDING, to BMC_HV(timeout 5 s)  # Calibration Verification Number
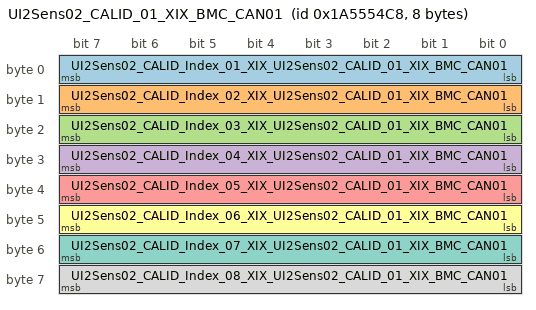
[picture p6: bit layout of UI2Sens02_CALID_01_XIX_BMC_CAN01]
      frame UI2Sens02_CALID_01_XIX_BMC_CAN01: id 0x1A5554C8, to BMC_HV, frame-length=8, can-addressing-mode=EXTENDED, can-frame-rx-behavior=CAN-20, can-frame-tx-behavior=CAN-20
        pdu UI2Sens02_CALID_01_XIX_BMC_CAN01: length=8, transmission-mode-true-timing=cyclic-timing={time-offset=0, time-period=1}, unused-bit-pattern=0
          signal UI2Sens02_CALID_Index_01_XIX_UI2Sens02_CALID_01_XIX_BMC_CAN01: start 0, 8 bit, little-endian, data-type-policy=OVERRIDE, i-signal-type=PRIMITIVE, init-value=63, base-type=BT_UI2Sens02_CALID_Index_01, compu {phys=raw for raw 0..255}, range phys 0..255, raw 0..255, transfer-property=PENDING, to BMC_HV(timeout 5 s)  # Calibration Identification
          signal UI2Sens02_CALID_Index_02_XIX_UI2Sens02_CALID_01_XIX_BMC_CAN01: start 8, 8 bit, little-endian, data-type-policy=OVERRIDE, i-signal-type=PRIMITIVE, init-value=63, base-type=BT_UI2Sens02_CALID_Index_02, compu {phys=raw for raw 0..255}, range phys 0..255, raw 0..255, transfer-property=PENDING, to BMC_HV(timeout 5 s)  # Calibration Identification
          signal UI2Sens02_CALID_Index_03_XIX_UI2Sens02_CALID_01_XIX_BMC_CAN01: start 16, 8 bit, little-endian, data-type-policy=OVERRIDE, i-signal-type=PRIMITIVE, init-value=63, base-type=BT_UI2Sens02_CALID_Index_03, compu {phys=raw for raw 0..255}, range phys 0..255, raw 0..255, transfer-property=PENDING, to BMC_HV(timeout 5 s)  # Calibration Identification
          signal UI2Sens02_CALID_Index_04_XIX_UI2Sens02_CALID_01_XIX_BMC_CAN01: start 24, 8 bit, little-endian, data-type-policy=OVERRIDE, i-signal-type=PRIMITIVE, init-value=63, base-type=BT_UI2Sens02_CALID_Index_04, compu {phys=raw for raw 0..255}, range phys 0..255, raw 0..255, transfer-property=PENDING, to BMC_HV(timeout 5 s)  # Calibration Identification
          signal UI2Sens02_CALID_Index_05_XIX_UI2Sens02_CALID_01_XIX_BMC_CAN01: start 32, 8 bit, little-endian, data-type-policy=OVERRIDE, i-signal-type=PRIMITIVE, init-value=63, base-type=BT_UI2Sens02_CALID_Index_05, compu {phys=raw for raw 0..255}, range phys 0..255, raw 0..255, transfer-property=PENDING, to BMC_HV(timeout 5 s)  # Calibration Identification
          signal UI2Sens02_CALID_Index_06_XIX_UI2Sens02_CALID_01_XIX_BMC_CAN01: start 40, 8 bit, little-endian, data-type-policy=OVERRIDE, i-signal-type=PRIMITIVE, init-value=63, base-type=BT_UI2Sens02_CALID_Index_06, compu {phys=raw for raw 0..255}, range phys 0..255, raw 0..255, transfer-property=PENDING, to BMC_HV(timeout 5 s)  # Calibration Identification
          signal UI2Sens02_CALID_Index_07_XIX_UI2Sens02_CALID_01_XIX_BMC_CAN01: start 48, 8 bit, little-endian, data-type-policy=OVERRIDE, i-signal-type=PRIMITIVE, init-value=63, base-type=BT_UI2Sens02_CALID_Index_07, compu {phys=raw for raw 0..255}, range phys 0..255, raw 0..255, transfer-property=PENDING, to BMC_HV(timeout 5 s)  # Calibration Identification
          signal UI2Sens02_CALID_Index_08_XIX_UI2Sens02_CALID_01_XIX_BMC_CAN01: start 56, 8 bit, little-endian, data-type-policy=OVERRIDE, i-signal-type=PRIMITIVE, init-value=63, base-type=BT_UI2Sens02_CALID_Index_08, compu {phys=raw for raw 0..255}, range phys 0..255, raw 0..255, transfer-property=PENDING, to BMC_HV(timeout 5 s)  # Calibration Identification
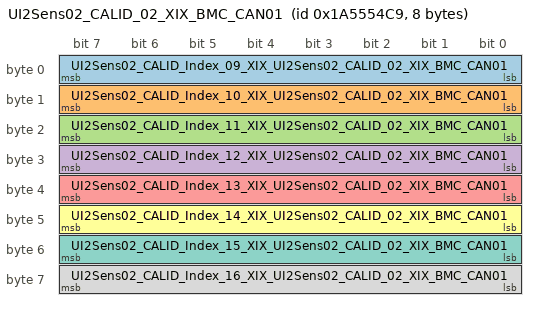
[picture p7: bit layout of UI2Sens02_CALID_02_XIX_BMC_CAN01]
      frame UI2Sens02_CALID_02_XIX_BMC_CAN01: id 0x1A5554C9, to BMC_HV, frame-length=8, can-addressing-mode=EXTENDED, can-frame-rx-behavior=CAN-20, can-frame-tx-behavior=CAN-20
        pdu UI2Sens02_CALID_02_XIX_BMC_CAN01: length=8, transmission-mode-true-timing=cyclic-timing={time-offset=0, time-period=1}, unused-bit-pattern=0
          signal UI2Sens02_CALID_Index_09_XIX_UI2Sens02_CALID_02_XIX_BMC_CAN01: start 0, 8 bit, little-endian, data-type-policy=OVERRIDE, i-signal-type=PRIMITIVE, init-value=63, base-type=BT_UI2Sens02_CALID_Index_09, compu {phys=raw for raw 0..255}, range phys 0..255, raw 0..255, transfer-property=PENDING, to BMC_HV(timeout 5 s)  # Calibration Identification
          signal UI2Sens02_CALID_Index_10_XIX_UI2Sens02_CALID_02_XIX_BMC_CAN01: start 8, 8 bit, little-endian, data-type-policy=OVERRIDE, i-signal-type=PRIMITIVE, init-value=63, base-type=BT_UI2Sens02_CALID_Index_10, compu {phys=raw for raw 0..255}, range phys 0..255, raw 0..255, transfer-property=PENDING, to BMC_HV(timeout 5 s)  # Calibration Identification
          signal UI2Sens02_CALID_Index_11_XIX_UI2Sens02_CALID_02_XIX_BMC_CAN01: start 16, 8 bit, little-endian, data-type-policy=OVERRIDE, i-signal-type=PRIMITIVE, init-value=63, base-type=BT_UI2Sens02_CALID_Index_11, compu {phys=raw for raw 0..255}, range phys 0..255, raw 0..255, transfer-property=PENDING, to BMC_HV(timeout 5 s)  # Calibration Identification
          signal UI2Sens02_CALID_Index_12_XIX_UI2Sens02_CALID_02_XIX_BMC_CAN01: start 24, 8 bit, little-endian, data-type-policy=OVERRIDE, i-signal-type=PRIMITIVE, init-value=63, base-type=BT_UI2Sens02_CALID_Index_12, compu {phys=raw for raw 0..255}, range phys 0..255, raw 0..255, transfer-property=PENDING, to BMC_HV(timeout 5 s)  # Calibration Identification
          signal UI2Sens02_CALID_Index_13_XIX_UI2Sens02_CALID_02_XIX_BMC_CAN01: start 32, 8 bit, little-endian, data-type-policy=OVERRIDE, i-signal-type=PRIMITIVE, init-value=63, base-type=BT_UI2Sens02_CALID_Index_13, compu {phys=raw for raw 0..255}, range phys 0..255, raw 0..255, transfer-property=PENDING, to BMC_HV(timeout 5 s)  # Calibration Identification
          signal UI2Sens02_CALID_Index_14_XIX_UI2Sens02_CALID_02_XIX_BMC_CAN01: start 40, 8 bit, little-endian, data-type-policy=OVERRIDE, i-signal-type=PRIMITIVE, init-value=63, base-type=BT_UI2Sens02_CALID_Index_14, compu {phys=raw for raw 0..255}, range phys 0..255, raw 0..255, transfer-property=PENDING, to BMC_HV(timeout 5 s)  # Calibration Identification
          signal UI2Sens02_CALID_Index_15_XIX_UI2Sens02_CALID_02_XIX_BMC_CAN01: start 48, 8 bit, little-endian, data-type-policy=OVERRIDE, i-signal-type=PRIMITIVE, init-value=63, base-type=BT_UI2Sens02_CALID_Index_15, compu {phys=raw for raw 0..255}, range phys 0..255, raw 0..255, transfer-property=PENDING, to BMC_HV(timeout 5 s)  # Calibration Identification
          signal UI2Sens02_CALID_Index_16_XIX_UI2Sens02_CALID_02_XIX_BMC_CAN01: start 56, 8 bit, little-endian, data-type-policy=OVERRIDE, i-signal-type=PRIMITIVE, init-value=63, base-type=BT_UI2Sens02_CALID_Index_16, compu {phys=raw for raw 0..255}, range phys 0..255, raw 0..255, transfer-property=PENDING, to BMC_HV(timeout 5 s)  # Calibration Identification
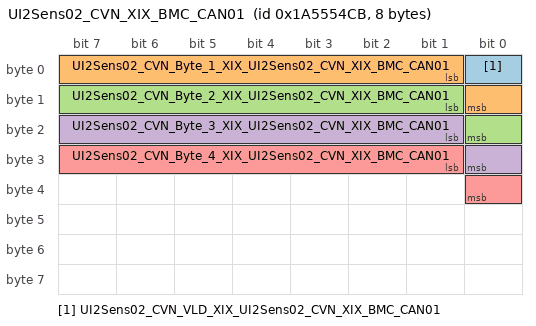
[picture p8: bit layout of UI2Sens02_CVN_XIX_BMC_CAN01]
      frame UI2Sens02_CVN_XIX_BMC_CAN01: id 0x1A5554CB, to BMC_HV, frame-length=8, can-addressing-mode=EXTENDED, can-frame-rx-behavior=CAN-20, can-frame-tx-behavior=CAN-20
        pdu UI2Sens02_CVN_XIX_BMC_CAN01: length=8, transmission-mode-true-timing=cyclic-timing={time-offset=0, time-period=1}, unused-bit-pattern=0
          signal UI2Sens02_CVN_VLD_XIX_UI2Sens02_CVN_XIX_BMC_CAN01: start 0, 1 bit, little-endian, data-type-policy=OVERRIDE, i-signal-type=PRIMITIVE, init-value=0, base-type=BT_UI2Sens02_CVN_VLD, compu {0=Cx0_Ungueltig (CM_UI2Sens02_CVN_VLD_Cx0_Ungueltig), 1=Cx1_Gueltig (CM_UI2Sens02_CVN_VLD_Cx1_Gueltig)}, range raw 0..1, transfer-property=PENDING, to BMC_HV(timeout 5 s)  # Über dieses Signal wird gekennzeichnet, ob die Berechnung der CVN im SecondaryOBDECU abgeschlossen ist.
          signal UI2Sens02_CVN_Byte_1_XIX_UI2Sens02_CVN_XIX_BMC_CAN01: start 1, 8 bit, little-endian, data-type-policy=OVERRIDE, i-signal-type=PRIMITIVE, init-value=0, base-type=BT_UI2Sens02_CVN_Byte_1, compu {phys=raw for raw 0..255}, range phys 0..255, raw 0..255, transfer-property=PENDING, to BMC_HV(timeout 5 s)  # Calibration Verification Number
          signal UI2Sens02_CVN_Byte_2_XIX_UI2Sens02_CVN_XIX_BMC_CAN01: start 9, 8 bit, little-endian, data-type-policy=OVERRIDE, i-signal-type=PRIMITIVE, init-value=0, base-type=BT_UI2Sens02_CVN_Byte_2, compu {phys=raw for raw 0..255}, range phys 0..255, raw 0..255, transfer-property=PENDING, to BMC_HV(timeout 5 s)  # Calibration Verification Number
          signal UI2Sens02_CVN_Byte_3_XIX_UI2Sens02_CVN_XIX_BMC_CAN01: start 17, 8 bit, little-endian, data-type-policy=OVERRIDE, i-signal-type=PRIMITIVE, init-value=0, base-type=BT_UI2Sens02_CVN_Byte_3, compu {phys=raw for raw 0..255}, range phys 0..255, raw 0..255, transfer-property=PENDING, to BMC_HV(timeout 5 s)  # Calibration Verification Number
          signal UI2Sens02_CVN_Byte_4_XIX_UI2Sens02_CVN_XIX_BMC_CAN01: start 25, 8 bit, little-endian, data-type-policy=OVERRIDE, i-signal-type=PRIMITIVE, init-value=0, base-type=BT_UI2Sens02_CVN_Byte_4, compu {phys=raw for raw 0..255}, range phys 0..255, raw 0..255, transfer-property=PENDING, to BMC_HV(timeout 5 s)  # Calibration Verification Number
      frame XCP_BJB_CRO_01_XIX_BMC_CAN01: id 0x18FCD000, from BMC_HV, frame-length=8, can-addressing-mode=EXTENDED, can-frame-rx-behavior=CAN-20, can-frame-tx-behavior=CAN-20
        user defined pdu CDD_XCP_BJB_CRO_01_XIX_BMC_CAN01: length=8, cdd-type=EID
      frame XCP_BJB_DTO_01_XIX_BMC_CAN01: id 0x18FCD001, to BMC_HV, frame-length=8, can-addressing-mode=EXTENDED, can-frame-rx-behavior=CAN-20, can-frame-tx-behavior=CAN-20
        user defined pdu CDD_XCP_BJB_DTO_01_XIX_BMC_CAN01: length=8, cdd-type=EID
      pdu triggering PT_BMC_CAN01_XIX_TPCHType_CANHS_Flash_DIA_XIX_0x17FC16D0_XIX_0x17FE16D0_XIX_Physical: pdu=DCM_BMC_CAN01_XIX_TPCHType_CANHS_Flash_DIA_XIX_0x17FC16D0_XIX_0x17FE16D0_XIX_Physical, from BMC_HV
      pdu triggering PT_BMC_CAN01_XIX_TPCHType_CANHS_Flash_DIA_XIX_0x17FC17B1_XIX_0x17FE17B1_XIX_Physical: pdu=DCM_BMC_CAN01_XIX_TPCHType_CANHS_Flash_DIA_XIX_0x17FC17B1_XIX_0x17FE17B1_XIX_Physical, from BMC_HV
      pdu triggering PT_BMC_CAN01_XIX_TPCHType_CANHS_Flash_DIA_XIX_0x17FC17B2_XIX_0x17FE17B2_XIX_Physical: pdu=DCM_BMC_CAN01_XIX_TPCHType_CANHS_Flash_DIA_XIX_0x17FC17B2_XIX_0x17FE17B2_XIX_Physical, from BMC_HV
      pdu triggering PT_BMC_CAN01_XIX_TPCHType_CANHS_Flash_DIA_XIX_0x17FE16D0_XIX_0x17FC16D0_XIX_Physical: pdu=DCM_BMC_CAN01_XIX_TPCHType_CANHS_Flash_DIA_XIX_0x17FE16D0_XIX_0x17FC16D0_XIX_Physical, to BMC_HV
      pdu triggering PT_BMC_CAN01_XIX_TPCHType_CANHS_Flash_DIA_XIX_0x17FE17B1_XIX_0x17FC17B1_XIX_Physical: pdu=DCM_BMC_CAN01_XIX_TPCHType_CANHS_Flash_DIA_XIX_0x17FE17B1_XIX_0x17FC17B1_XIX_Physical, to BMC_HV
      pdu triggering PT_BMC_CAN01_XIX_TPCHType_CANHS_Flash_DIA_XIX_0x17FE17B2_XIX_0x17FC17B2_XIX_Physical: pdu=DCM_BMC_CAN01_XIX_TPCHType_CANHS_Flash_DIA_XIX_0x17FE17B2_XIX_0x17FC17B2_XIX_Physical, to BMC_HV
      pdu triggering PT_BMC_CAN01_XIX_TPCHType_CANHS_ISO_Diagnose_XIX_0x700_XIX_Functional: pdu=DCM_BMC_CAN01_XIX_TPCHType_CANHS_ISO_Diagnose_XIX_0x700_XIX_Functional, from BMC_HV
      pdu triggering PT_BMC_CAN01_XIX_TPCHType_CANHS_OBDC_Diagnose_XIX_0x17FD0200_XIX_Functional: pdu=DCM_BMC_CAN01_XIX_TPCHType_CANHS_OBDC_Diagnose_XIX_0x17FD0200_XIX_Functional, from BMC_HV
      pdu triggering PT_BMC_CAN01_XIX_TPCHType_CANHS_OBDC_SSN_Diagnose_XIX_0x17FC70D0_XIX_0x17FE70D0_XIX_Physical: pdu=DCM_BMC_CAN01_XIX_TPCHType_CANHS_OBDC_SSN_Diagnose_XIX_0x17FC70D0_XIX_0x17FE70D0_XIX_Physical, from BMC_HV
      pdu triggering PT_BMC_CAN01_XIX_TPCHType_CANHS_OBDC_SSN_Diagnose_XIX_0x17FC71B1_XIX_0x17FE71B1_XIX_Physical: pdu=DCM_BMC_CAN01_XIX_TPCHType_CANHS_OBDC_SSN_Diagnose_XIX_0x17FC71B1_XIX_0x17FE71B1_XIX_Physical, from BMC_HV
      pdu triggering PT_BMC_CAN01_XIX_TPCHType_CANHS_OBDC_SSN_Diagnose_XIX_0x17FC71B2_XIX_0x17FE71B2_XIX_Physical: pdu=DCM_BMC_CAN01_XIX_TPCHType_CANHS_OBDC_SSN_Diagnose_XIX_0x17FC71B2_XIX_0x17FE71B2_XIX_Physical, from BMC_HV
      pdu triggering PT_BMC_CAN01_XIX_TPCHType_CANHS_OBDC_SSN_Diagnose_XIX_0x17FE70D0_XIX_0x17FC70D0_XIX_Physical: pdu=DCM_BMC_CAN01_XIX_TPCHType_CANHS_OBDC_SSN_Diagnose_XIX_0x17FE70D0_XIX_0x17FC70D0_XIX_Physical, to BMC_HV
      pdu triggering PT_BMC_CAN01_XIX_TPCHType_CANHS_OBDC_SSN_Diagnose_XIX_0x17FE71B1_XIX_0x17FC71B1_XIX_Physical: pdu=DCM_BMC_CAN01_XIX_TPCHType_CANHS_OBDC_SSN_Diagnose_XIX_0x17FE71B1_XIX_0x17FC71B1_XIX_Physical, to BMC_HV
      pdu triggering PT_BMC_CAN01_XIX_TPCHType_CANHS_OBDC_SSN_Diagnose_XIX_0x17FE71B2_XIX_0x17FC71B2_XIX_Physical: pdu=DCM_BMC_CAN01_XIX_TPCHType_CANHS_OBDC_SSN_Diagnose_XIX_0x17FE71B2_XIX_0x17FC71B2_XIX_Physical, to BMC_HV
package /NmConfig
  nm config NmConfig: can-nm-cluster-coupling{coupled-cluster=[NmCluster_BMC_CAN01, NmCluster_HCP5_CANFD01], nm-busload-reduction-enabled=false, nm-immediate-restart-enabled=false}
    can nm cluster NmCluster_BMC_CAN01: communication-cluster=BMC_CAN01, nm-channel-sleep-master=false, nm-pnc-participation=true, nm-synchronizing-network=false, nm-busload-reduction-active=false, nm-cbv-position=1, nm-immediate-nm-cycle-time=0.02, nm-immediate-nm-transmissions=10, nm-message-timeout-time=0.1, nm-msg-cycle-time=0.2, nm-network-timeout=1, nm-remote-sleep-indication-time=0.5, nm-repeat-message-time=4, nm-wait-bus-sleep-time=0.75
      can nm node NmNode_BMC_HV_XIX_BMC_CAN01: controller=CT_BMC_CAN01, nm-if-ecu=NmEcu_BMC_HV, nm-passive-mode-enabled=false, rx-nm-pdu=NM_Dummy01_XIX_BMC_CAN01, tx-nm-pdu=NMH_Hybrid_01_XIX_BMC_CAN01, nm-car-wake-up-rx-enabled=false, nm-msg-cycle-offset=0
    can nm cluster NmCluster_HCP5_CANFD01: communication-cluster=HCP5_CANFD01, nm-channel-sleep-master=false, nm-pnc-participation=true, nm-synchronizing-network=false, nm-busload-reduction-active=false, nm-cbv-position=0, nm-immediate-nm-cycle-time=0.02, nm-immediate-nm-transmissions=10, nm-message-timeout-time=0.1, nm-msg-cycle-time=0.2, nm-network-timeout=1, nm-remote-sleep-indication-time=0.5, nm-repeat-message-time=4, nm-wait-bus-sleep-time=0.75
      can nm node NmNode_BMC_HV_XIX_HCP5_CANFD01: controller=CT_HCP5_CANFD01, nm-if-ecu=NmEcu_BMC_HV, nm-passive-mode-enabled=false, rx-nm-pdu=[NM_AWC_XIX_HCP5_CANFD01, NM_Gateway_XIX_HCP5_CANFD01, NM_HVZB_XIX_HCP5_CANFD01, NM_Ladegeraet_XIX_HCP5_CANFD01, NM_SACID_1_XIX_HCP5_CANFD01, NM_SACID_2_XIX_HCP5_CANFD01], tx-nm-pdu=NM_Hybrid_01_XIX_HCP5_CANFD01, nm-car-wake-up-rx-enabled=false, nm-msg-cycle-offset=0
    nm-if-ecus:
      nm ecu NmEcu_BMC_HV: ecu-instance=BMC_HV, nm-bus-synchronization-enabled=false, nm-com-control-enabled=false, nm-node-detection-enabled=false, nm-node-id-enabled=false, nm-pdu-rx-indication-enabled=true, nm-remote-sleep-ind-enabled=false, nm-repeat-msg-ind-enabled=false, nm-state-change-ind-enabled=true, nm-user-data-enabled=true
package /PDU
  dcm i pdu DCM_BMC_CAN01_XIX_TPCHType_CANHS_Flash_DIA_XIX_0x17FC16D0_XIX_0x17FE16D0_XIX_Physical: length=512, diag-pdu-type=DIAG-REQUEST
  dcm i pdu DCM_BMC_CAN01_XIX_TPCHType_CANHS_Flash_DIA_XIX_0x17FC17B1_XIX_0x17FE17B1_XIX_Physical: length=512, diag-pdu-type=DIAG-REQUEST
  dcm i pdu DCM_BMC_CAN01_XIX_TPCHType_CANHS_Flash_DIA_XIX_0x17FC17B2_XIX_0x17FE17B2_XIX_Physical: length=512, diag-pdu-type=DIAG-REQUEST
  dcm i pdu DCM_BMC_CAN01_XIX_TPCHType_CANHS_Flash_DIA_XIX_0x17FE16D0_XIX_0x17FC16D0_XIX_Physical: length=512, diag-pdu-type=DIAG-RESPONSE
  dcm i pdu DCM_BMC_CAN01_XIX_TPCHType_CANHS_Flash_DIA_XIX_0x17FE17B1_XIX_0x17FC17B1_XIX_Physical: length=512, diag-pdu-type=DIAG-RESPONSE
  dcm i pdu DCM_BMC_CAN01_XIX_TPCHType_CANHS_Flash_DIA_XIX_0x17FE17B2_XIX_0x17FC17B2_XIX_Physical: length=512, diag-pdu-type=DIAG-RESPONSE
  dcm i pdu DCM_BMC_CAN01_XIX_TPCHType_CANHS_ISO_Diagnose_XIX_0x700_XIX_Functional: length=6, diag-pdu-type=DIAG-REQUEST
  dcm i pdu DCM_BMC_CAN01_XIX_TPCHType_CANHS_OBDC_Diagnose_XIX_0x17FD0200_XIX_Functional: length=6, diag-pdu-type=DIAG-REQUEST
  dcm i pdu DCM_BMC_CAN01_XIX_TPCHType_CANHS_OBDC_SSN_Diagnose_XIX_0x17FC70D0_XIX_0x17FE70D0_XIX_Physical: length=512, diag-pdu-type=DIAG-REQUEST
  dcm i pdu DCM_BMC_CAN01_XIX_TPCHType_CANHS_OBDC_SSN_Diagnose_XIX_0x17FC71B1_XIX_0x17FE71B1_XIX_Physical: length=512, diag-pdu-type=DIAG-REQUEST
  dcm i pdu DCM_BMC_CAN01_XIX_TPCHType_CANHS_OBDC_SSN_Diagnose_XIX_0x17FC71B2_XIX_0x17FE71B2_XIX_Physical: length=512, diag-pdu-type=DIAG-REQUEST
  dcm i pdu DCM_BMC_CAN01_XIX_TPCHType_CANHS_OBDC_SSN_Diagnose_XIX_0x17FE70D0_XIX_0x17FC70D0_XIX_Physical: length=512, diag-pdu-type=DIAG-RESPONSE
  dcm i pdu DCM_BMC_CAN01_XIX_TPCHType_CANHS_OBDC_SSN_Diagnose_XIX_0x17FE71B1_XIX_0x17FC71B1_XIX_Physical: length=512, diag-pdu-type=DIAG-RESPONSE
  dcm i pdu DCM_BMC_CAN01_XIX_TPCHType_CANHS_OBDC_SSN_Diagnose_XIX_0x17FE71B2_XIX_0x17FC71B2_XIX_Physical: length=512, diag-pdu-type=DIAG-RESPONSE
  dcm i pdu DCM_HCP5_CANFD01_XIX_TPCHType_CANFD_ISO_Diagnose_XIX_0x1C40007B_XIX_0x1C42007B_XIX_Physical: length=512, diag-pdu-type=DIAG-REQUEST
  dcm i pdu DCM_HCP5_CANFD01_XIX_TPCHType_CANFD_ISO_Diagnose_XIX_0x1C410000_XIX_Functional: length=62, diag-pdu-type=DIAG-REQUEST
  dcm i pdu DCM_HCP5_CANFD01_XIX_TPCHType_CANFD_ISO_Diagnose_XIX_0x1C42007B_XIX_0x1C40007B_XIX_Physical: length=512, diag-pdu-type=DIAG-RESPONSE
  dcm i pdu DCM_HCP5_CANFD01_XIX_TPCHType_CANFD_OBDC_Diagnose_XIX_0x1C40027B_XIX_0x1C42027B_XIX_Physical: length=512, diag-pdu-type=DIAG-REQUEST
  dcm i pdu DCM_HCP5_CANFD01_XIX_TPCHType_CANFD_OBDC_Diagnose_XIX_0x1C410200_XIX_Functional: length=62, diag-pdu-type=DIAG-REQUEST
  dcm i pdu DCM_HCP5_CANFD01_XIX_TPCHType_CANFD_OBDC_Diagnose_XIX_0x1C42027B_XIX_0x1C40027B_XIX_Physical: length=512, diag-pdu-type=DIAG-RESPONSE
  dcm i pdu DCM_HCP5_CANFD01_XIX_TPCHType_CANHS_Flash_DIA_XIX_0x17FC16D0_XIX_0x17FE16D0_XIX_Physical: length=512, diag-pdu-type=DIAG-REQUEST
  dcm i pdu DCM_HCP5_CANFD01_XIX_TPCHType_CANHS_Flash_DIA_XIX_0x17FC17B1_XIX_0x17FE17B1_XIX_Physical: length=512, diag-pdu-type=DIAG-REQUEST
  dcm i pdu DCM_HCP5_CANFD01_XIX_TPCHType_CANHS_Flash_DIA_XIX_0x17FC17B2_XIX_0x17FE17B2_XIX_Physical: length=512, diag-pdu-type=DIAG-REQUEST
  dcm i pdu DCM_HCP5_CANFD01_XIX_TPCHType_CANHS_Flash_DIA_XIX_0x17FE16D0_XIX_0x17FC16D0_XIX_Physical: length=512, diag-pdu-type=DIAG-RESPONSE
  dcm i pdu DCM_HCP5_CANFD01_XIX_TPCHType_CANHS_Flash_DIA_XIX_0x17FE17B1_XIX_0x17FC17B1_XIX_Physical: length=512, diag-pdu-type=DIAG-RESPONSE
  dcm i pdu DCM_HCP5_CANFD01_XIX_TPCHType_CANHS_Flash_DIA_XIX_0x17FE17B2_XIX_0x17FC17B2_XIX_Physical: length=512, diag-pdu-type=DIAG-RESPONSE
  dcm i pdu DCM_HCP5_CANFD01_XIX_TPCHType_CANHS_ISO_Diagnose_XIX_0x17FC007B_XIX_0x17FE007B_XIX_Physical: length=512, diag-pdu-type=DIAG-REQUEST
  dcm i pdu DCM_HCP5_CANFD01_XIX_TPCHType_CANHS_ISO_Diagnose_XIX_0x17FE007B_XIX_0x17FC007B_XIX_Physical: length=512, diag-pdu-type=DIAG-RESPONSE
  dcm i pdu DCM_HCP5_CANFD01_XIX_TPCHType_CANHS_ISO_Diagnose_XIX_0x700_XIX_Functional: length=62, diag-pdu-type=DIAG-REQUEST
  dcm i pdu DCM_HCP5_CANFD01_XIX_TPCHType_CANHS_OBDC_SSN_Diagnose_XIX_0x17FC70D0_XIX_0x17FE70D0_XIX_Physical: length=512, diag-pdu-type=DIAG-REQUEST
  dcm i pdu DCM_HCP5_CANFD01_XIX_TPCHType_CANHS_OBDC_SSN_Diagnose_XIX_0x17FC71B1_XIX_0x17FE71B1_XIX_Physical: length=512, diag-pdu-type=DIAG-REQUEST
  dcm i pdu DCM_HCP5_CANFD01_XIX_TPCHType_CANHS_OBDC_SSN_Diagnose_XIX_0x17FC71B2_XIX_0x17FE71B2_XIX_Physical: length=512, diag-pdu-type=DIAG-REQUEST
  dcm i pdu DCM_HCP5_CANFD01_XIX_TPCHType_CANHS_OBDC_SSN_Diagnose_XIX_0x17FE70D0_XIX_0x17FC70D0_XIX_Physical: length=512, diag-pdu-type=DIAG-RESPONSE
  dcm i pdu DCM_HCP5_CANFD01_XIX_TPCHType_CANHS_OBDC_SSN_Diagnose_XIX_0x17FE71B1_XIX_0x17FC71B1_XIX_Physical: length=512, diag-pdu-type=DIAG-RESPONSE
  dcm i pdu DCM_HCP5_CANFD01_XIX_TPCHType_CANHS_OBDC_SSN_Diagnose_XIX_0x17FE71B2_XIX_0x17FC71B2_XIX_Physical: length=512, diag-pdu-type=DIAG-RESPONSE
  dcm i pdu DCM_HCP5_CANFD01_XIX_TPCHType_CANHS_OBDx_XIX_0x18DA05F1_XIX_0x18DAF105_XIX_Physical: length=512, diag-pdu-type=DIAG-REQUEST
  dcm i pdu DCM_HCP5_CANFD01_XIX_TPCHType_CANHS_OBDx_XIX_0x18DAF105_XIX_0x18DA05F1_XIX_Physical: length=512, diag-pdu-type=DIAG-RESPONSE
  dcm i pdu DCM_HCP5_CANFD01_XIX_TPCHType_CANHS_OBDx_XIX_0x18DB33F1_XIX_Functional: length=62, diag-pdu-type=DIAG-REQUEST
  pdu BMC_HV_01_XIX_HCP5_CANFD01_E2E: length=16, transmission-mode-true-timing=event-controlled-timing={number-of-repetitions=0, repetition-period=0}, unused-bit-pattern=0  # Fuer die Botschaft ist das Cyclic-Timing 0.01 zu verwenden.
    signal BMC_HV_01_CRC_XIX_BMC_HV_01_XIX_HCP5_CANFD01: start 0, 8 bit, little-endian, data-type-policy=OVERRIDE, i-signal-type=PRIMITIVE, init-value=0, base-type=BT_BMC_HV_01_CRC, compu {phys=raw for raw 0..255}, range phys 0..255, raw 0..255  # Für MLB: Berechnung siehe Lastenheft "Kommunikationsabsicherung für FlexRay und CAN" Ab MQB und MLBevo: Berechnung siehe Lastenheft "End-to-End Kommunikationsabsicherung" Endwerte siehe Begleitdokument "S-PDU Kennungsfolgen"
    signal BMC_HV_01_BZ_XIX_BMC_HV_01_XIX_HCP5_CANFD01: start 8, 4 bit, little-endian, data-type-policy=OVERRIDE, i-signal-type=PRIMITIVE, init-value=0, base-type=BT_BMC_HV_01_BZ, compu {phys=raw for raw 0..15}, range phys 0..15, raw 0..15  # 4bit Botschaftszähler, wird mit jeder Sendebotschaft inkrementiert
    signal BMC_Bankstatus_XIX_BMC_HV_01_XIX_HCP5_CANFD01: start 12, 4 bit, little-endian, data-type-policy=OVERRIDE, i-signal-type=PRIMITIVE, init-value=14, base-type=BT_BMC_Bankstatus, invalid-value=Invalid_BMC_Bankstatus_XIX_BMC_HV_01_XIX_HCP5_CANFD01:15, compu {0=Cx0_Keine_Bank_aktiv (CM_BMC_Bankstatus_Cx0_Keine_Bank_aktiv), 1=Cx1_800V_Seriellbetrieb (CM_BMC_Bankstatus_Cx1_800V_Seriellbetrieb), 2=Cx2_400V_Parallelbetrieb (CM_BMC_Bankstatus_Cx2_400V_Parallelbetrieb), 3=Cx3_400V_Ausgleichsbetrieb (CM_BMC_Bankstatus_Cx3_400V_Ausgleichsbetrieb), 4=Cx4_400V_Notlaufbetrieb_Bank0 (CM_BMC_Bankstatus_Cx4_400V_Notlaufbetrieb_Bank0), 5=Cx5_400V_Notlaufbetrieb_Bank1 (CM_BMC_Bankstatus_Cx5_400V_Notlaufbetrieb_Bank1), 14=Cxe_Init (CM_BMC_Bankstatus_Cxe_Init), 15=Cxf_Fehler (CM_BMC_Bankstatus_Cxf_Fehler)}, range raw 0..15  # Feedback vom BMS an den HVK welche Bank geschaltet wurde
    signal BMC_Spannung_XIX_BMC_HV_01_XIX_HCP5_CANFD01: start 16, 14 bit, little-endian, data-type-policy=OVERRIDE, i-signal-type=PRIMITIVE, init-value=16382, base-type=BT_BMC_Spannung, invalid-value=Invalid_BMC_Spannung_XIX_BMC_HV_01_XIX_HCP5_CANFD01:16383, compu {phys=raw*0.0625 for raw 0..16380, 16381=Cx3ffd_Null_Bank (CM_BMC_Spannung_Cx3ffd_Null_Bank), 16382=Cx3ffe_Init (CM_BMC_Spannung_Cx3ffe_Init), 16383=Cx3fff_Fehler (CM_BMC_Spannung_Cx3fff_Fehler); unit Unit_Volt}, range phys 0..1023.75 Unit_Volt, raw 0..16383, unit=Unit_Volt  # actual voltage of the battery / Momentanwert: Batteriespannung
    signal BMC_HVK_EoHVL_Status_XIX_BMC_HV_01_XIX_HCP5_CANFD01: start 30, 2 bit, little-endian, data-type-policy=OVERRIDE, i-signal-type=PRIMITIVE, init-value=0, base-type=BT_BMC_HVK_EoHVL_Status, invalid-value=Invalid_BMC_HVK_EoHVL_Status_XIX_BMC_HV_01_XIX_HCP5_CANFD01:3, compu {0=Cx0_Init (CM_BMC_HVK_EoHVL_Status_Cx0_Init), 1=Cx1_Uzwkr_kleiner_UEoHVL_Schwell (CM_BMC_HVK_EoHVL_Status_Cx1_Uzwkr_kleiner_UEoHVL_Schwell), 2=Cx2_Uzwkr_groesgleich_UEoHVL_Schwell (CM_BMC_HVK_EoHVL_Status_Cx2_Uzwkr_groesgleich_UEoHVL_Schwell), 3=Cx3_Fehler (CM_BMC_HVK_EoHVL_Status_Cx3_Fehler)}, range raw 0..3  # Status der Erkennung offener HV-Leitung an der HV-Komponente, durch Messung an den HV-Anschlüssen
    signal BMC_Modus_XIX_BMC_HV_01_XIX_HCP5_CANFD01: start 32, 4 bit, little-endian, data-type-policy=OVERRIDE, i-signal-type=PRIMITIVE, init-value=15, base-type=BT_BMC_Modus, compu {0=Cx0_HV_inaktiv (CM_BMC_Modus_Cx0_HV_inaktiv), 1=Cx1_HV_aktiv (CM_BMC_Modus_Cx1_HV_aktiv), 4=Cx4_AC_Laden (CM_BMC_Modus_Cx4_AC_Laden), 5=Cx5_Error_Batt (CM_BMC_Modus_Cx5_Error_Batt), 6=Cx6_DC_Laden (CM_BMC_Modus_Cx6_DC_Laden), 15=Cxf_Init (CM_BMC_Modus_Cxf_Init)}, range raw 0..15  # Aktueller Betriebsmodus der Batterie 0: Standby; Schuetze geoeffnet; Kommunikation aktiv 1: Hauptschuetze geschlossen / HV-Netz aktiviert / normaler Fahrbetrieb 4: AC-Laden / HV Netz aktiv 5: interner Batteriefehler / angeforderter Modus kann nicht eingestellt werden 6: DC-Laden / HV Netz aktiv 15: Initialisierung
    signal BMC_HVK_Fehler_Intern_XIX_BMC_HV_01_XIX_HCP5_CANFD01: start 36, 2 bit, little-endian, data-type-policy=OVERRIDE, i-signal-type=PRIMITIVE, init-value=3, base-type=BT_BMC_HVK_Fehler_Intern, invalid-value=Invalid_BMC_HVK_Fehler_Intern_XIX_BMC_HV_01_XIX_HCP5_CANFD01:2, compu {0=Cx0_nicht_aktiv (CM_BMC_HVK_Fehler_Intern_Cx0_nicht_aktiv), 1=Cx1_aktiv (CM_BMC_HVK_Fehler_Intern_Cx1_aktiv), 2=Cx2_Fehler (CM_BMC_HVK_Fehler_Intern_Cx2_Fehler), 3=Cx3_Init (CM_BMC_HVK_Fehler_Intern_Cx3_Init)}, range raw 0..3  # HV-Status Keine Komponentenfunktion vom BMS zum HVK
    signal BMC_HVK_Fehler_SD_XIX_BMC_HV_01_XIX_HCP5_CANFD01: start 38, 2 bit, little-endian, data-type-policy=OVERRIDE, i-signal-type=PRIMITIVE, init-value=3, base-type=BT_BMC_HVK_Fehler_SD, invalid-value=Invalid_BMC_HVK_Fehler_SD_XIX_BMC_HV_01_XIX_HCP5_CANFD01:2, compu {0=Cx0_SD_gesteckt (CM_BMC_HVK_Fehler_SD_Cx0_SD_gesteckt), 1=Cx1_SD_gezogen (CM_BMC_HVK_Fehler_SD_Cx1_SD_gezogen), 2=Cx2_Fehler (CM_BMC_HVK_Fehler_SD_Cx2_Fehler), 3=Cx3_Init (CM_BMC_HVK_Fehler_SD_Cx3_Init)}, range raw 0..3  # Status zum ServiceDisconnect vom BMS zum HVK
    signal BMC_Spannung_ZwischenKreis_XIX_BMC_HV_01_XIX_HCP5_CANFD01: start 40, 14 bit, little-endian, data-type-policy=OVERRIDE, i-signal-type=PRIMITIVE, init-value=16382, base-type=BT_BMC_Spannung_ZwischenKreis, invalid-value=Invalid_BMC_Spannung_ZwischenKreis_XIX_BMC_HV_01_XIX_HCP5_CANFD01:16383, compu {phys=raw*0.0625 for raw 0..16380, 16381=Cx3ffd_nicht_messbar (CM_BMC_Spannung_ZwischenKreis_Cx3ffd_nicht_messbar), 16382=Cx3ffe_Init (CM_BMC_Spannung_ZwischenKreis_Cx3ffe_Init), 16383=Cx3fff_Fehler (CM_BMC_Spannung_ZwischenKreis_Cx3fff_Fehler); unit Unit_Volt}, range phys 0..1023.75 Unit_Volt, raw 0..16383, unit=Unit_Volt  # Momentanwert: Zwischenkreisspannung der Batterie.
    signal BMC_HVK_Fehler_HVIL_XIX_BMC_HV_01_XIX_HCP5_CANFD01: start 54, 2 bit, little-endian, data-type-policy=OVERRIDE, i-signal-type=PRIMITIVE, init-value=3, base-type=BT_BMC_HVK_Fehler_HVIL, invalid-value=Invalid_BMC_HVK_Fehler_HVIL_XIX_BMC_HV_01_XIX_HCP5_CANFD01:2, compu {0=Cx0_HVIL_geschlossen (CM_BMC_HVK_Fehler_HVIL_Cx0_HVIL_geschlossen) (HVIL geschlossen), 1=Cx1_HVIL_offen (CM_BMC_HVK_Fehler_HVIL_Cx1_HVIL_offen) (HVIL offen), 2=Cx2_Fehler (CM_BMC_HVK_Fehler_HVIL_Cx2_Fehler), 3=Cx3_Init (CM_BMC_HVK_Fehler_HVIL_Cx3_Init)}, range raw 0..3  # Status zum HV-Interlock vom BMS zum HVK
    signal BMC_Strom_XIX_BMC_HV_01_XIX_HCP5_CANFD01: start 56, 16 bit, little-endian, data-type-policy=OVERRIDE, i-signal-type=PRIMITIVE, init-value=65534, base-type=BT_BMC_Strom, invalid-value=Invalid_BMC_Strom_XIX_BMC_HV_01_XIX_HCP5_CANFD01:65535, compu {phys=raw*0.0625-2047 for raw 0..65533, 65534=Cxfffe_Init (CM_BMC_Strom_Cxfffe_Init), 65535=Cxffff_Fehler (CM_BMC_Strom_Cxffff_Fehler); unit Unit_Amper}, range phys -2047..2048.8125 Unit_Amper, raw 0..65535, unit=Unit_Amper  # Momentanwert: Batteriestrom; Stromrichtung: ein Ladestrom wird mit positiven, ein Entladestrom mit negativen Werten angegeben
    signal BMC_Spannung_ZwischenKreis_2_XIX_BMC_HV_01_XIX_HCP5_CANFD01: start 72, 14 bit, little-endian, data-type-policy=OVERRIDE, i-signal-type=PRIMITIVE, init-value=16382, base-type=BT_BMC_Spannung_ZwischenKreis_2, invalid-value=Invalid_BMC_Spannung_ZwischenKreis_2_XIX_BMC_HV_01_XIX_HCP5_CANFD01:16383, compu {phys=raw*0.0625 for raw 0..16380, 16381=Cx3ffd_nicht_messbar (CM_BMC_Spannung_ZwischenKreis_2_Cx3ffd_nicht_messbar), 16382=Cx3ffe_Init (CM_BMC_Spannung_ZwischenKreis_2_Cx3ffe_Init), 16383=Cx3fff_Fehler (CM_BMC_Spannung_ZwischenKreis_2_Cx3fff_Fehler); unit Unit_Volt}, range phys 0..1023.75 Unit_Volt, raw 0..16383, unit=Unit_Volt  # Momentanwert: Zweite Zwischenkreisspannung für Batterien mit zwei HV Abgaengen (zwei HV Kreise)
    signal BMC_Status_Spgfreiheit_XIX_BMC_HV_01_XIX_HCP5_CANFD01: start 86, 2 bit, little-endian, data-type-policy=OVERRIDE, i-signal-type=PRIMITIVE, init-value=0, base-type=BT_BMC_Status_Spgfreiheit, compu {0=Cx0_Init (CM_BMC_Status_Spgfreiheit_Cx0_Init), 1=Cx1_HV_Komponente_spannungsfrei (CM_BMC_Status_Spgfreiheit_Cx1_HV_Komponente_spannungsfrei), 2=Cx2_HV_Komp_nicht_spannungsfrei (CM_BMC_Status_Spgfreiheit_Cx2_HV_Komp_nicht_spannungsfrei), 3=Cx3_Fehler_nicht_spannungsfrei (CM_BMC_Status_Spgfreiheit_Cx3_Fehler_nicht_spannungsfrei)}, range raw 0..3  # 0=Init (ohne Funktion) 1=BMS Zwischenkreis spannungsfrei (U_Zwkr < 20V) 2=BMS Zwischenkreis nicht spannungsfrei (U_Zwkr >/= 25V, Hysterese) 3=Fehler (z.B. Fehler in der Sensorik)
    signal BMC_Strom_Messzeit_XIX_BMC_HV_01_XIX_HCP5_CANFD01: start 88, 8 bit, little-endian, data-type-policy=OVERRIDE, i-signal-type=PRIMITIVE, init-value=254, base-type=BT_BMC_Strom_Messzeit, invalid-value=Invalid_BMC_Strom_Messzeit_XIX_BMC_HV_01_XIX_HCP5_CANFD01:255, compu {phys=raw for raw 0..253, 254=Cxfe_Init (CM_BMC_Strom_Messzeit_Cxfe_Init), 255=Cxff_Fehler (CM_BMC_Strom_Messzeit_Cxff_Fehler); unit Unit_None}, range phys 0..253 Unit_None, raw 0..255, unit=Unit_None  # Messzeit zu Signal BMC_Strom
    signal BMC_Spannung_Messzeit_XIX_BMC_HV_01_XIX_HCP5_CANFD01: start 96, 8 bit, little-endian, data-type-policy=OVERRIDE, i-signal-type=PRIMITIVE, init-value=254, base-type=BT_BMC_Spannung_Messzeit, invalid-value=Invalid_BMC_Spannung_Messzeit_XIX_BMC_HV_01_XIX_HCP5_CANFD01:255, compu {phys=raw for raw 0..253, 254=Cxfe_Init (CM_BMC_Spannung_Messzeit_Cxfe_Init), 255=Cxff_Fehler (CM_BMC_Spannung_Messzeit_Cxff_Fehler); unit Unit_None}, range phys 0..253 Unit_None, raw 0..255, unit=Unit_None  # Messzeit zu Signal BMC_Spannung
    signal BMC_Strom_02_XIX_BMC_HV_01_XIX_HCP5_CANFD01: start 104, 17 bit, little-endian, data-type-policy=OVERRIDE, i-signal-type=PRIMITIVE, init-value=131070, base-type=BT_BMC_Strom_02, invalid-value=Invalid_BMC_Strom_02_XIX_BMC_HV_01_XIX_HCP5_CANFD01:131071, compu {phys=raw*0.0625-3250 for raw 0..104000, 131070=Cx1fffe_InitWert (CM_BMC_Strom_02_Cx1fffe_InitWert), 131071=Cx1ffff_Fehler (CM_BMC_Strom_02_Cx1ffff_Fehler); unit Unit_Amper}, range phys -3250..3250 Unit_Amper, raw 0..131071, unit=Unit_Amper  # Momentanwert: Batteriestrom; Stromrichtung: ein Ladestrom wird mit positiven, ein Entladestrom mit negativen Werten angegeben
    signal ISignalVoid_BMC_HV_01_XIX_HCP5_CANFD01_0: start 121, 7 bit, little-endian, system signal SignalVoid_BMC_HV_01_0, data-type-policy=OVERRIDE, i-signal-type=PRIMITIVE, base-type=BT_SignalVoid
    mapping SG_BMC_HV_01_XIX_HCP5_CANFD01: i-signal-group=SG_BMC_HV_01_XIX_HCP5_CANFD01, transfer-property=TRIGGERED-WITHOUT-REPETITION
  pdu BMC_HV_02_XIX_HCP5_CANFD01_E2E: length=44, transmission-mode-true-timing=event-controlled-timing={number-of-repetitions=0, repetition-period=0}, unused-bit-pattern=0  # Fuer die Botschaft ist das Cyclic-Timing 0.1 zu verwenden.
    signal BMC_HV_02_CRC_XIX_BMC_HV_02_XIX_HCP5_CANFD01: start 0, 8 bit, little-endian, data-type-policy=OVERRIDE, i-signal-type=PRIMITIVE, init-value=0, base-type=BT_BMC_HV_02_CRC, compu {phys=raw for raw 0..255}, range phys 0..255, raw 0..255  # Für MLB: Berechnung siehe Lastenheft "Kommunikationsabsicherung für FlexRay und CAN" Ab MQB und MLBevo: Berechnung siehe Lastenheft "End-to-End Kommunikationsabsicherung" Endwerte siehe Begleitdokument "S-PDU Kennungsfolgen"
    signal BMC_HV_02_BZ_XIX_BMC_HV_02_XIX_HCP5_CANFD01: start 8, 4 bit, little-endian, data-type-policy=OVERRIDE, i-signal-type=PRIMITIVE, init-value=0, base-type=BT_BMC_HV_02_BZ, compu {phys=raw for raw 0..15}, range phys 0..15, raw 0..15  # 4bit Botschaftszähler, wird mit jeder Sendebotschaft inkrementiert
    signal BMC_Vorlade_Zielspannung_XIX_BMC_HV_02_XIX_HCP5_CANFD01: start 12, 10 bit, little-endian, data-type-policy=OVERRIDE, i-signal-type=PRIMITIVE, init-value=1022, base-type=BT_BMC_Vorlade_Zielspannung, invalid-value=Invalid_BMC_Vorlade_Zielspannung_XIX_BMC_HV_02_XIX_HCP5_CANFD01:1023, compu {phys=raw for raw 0..1021, 1022=Cx3fe_Init (CM_BMC_Vorlade_Zielspannung_Cx3fe_Init), 1023=Cx3ff_Fehler (CM_BMC_Vorlade_Zielspannung_Cx3ff_Fehler); unit Unit_Volt}, range phys 0..1021 Unit_Volt, raw 0..1023, unit=Unit_Volt  # Erwartete Zielspannung der Batterie in Abhängigkeit des angeforderten Bankmodus
    signal BMC_PerfInd_Laden_XIX_BMC_HV_02_XIX_HCP5_CANFD01: start 22, 10 bit, little-endian, data-type-policy=OVERRIDE, i-signal-type=PRIMITIVE, init-value=1022, base-type=BT_BMC_PerfInd_Laden, invalid-value=Invalid_BMC_PerfInd_Laden_XIX_BMC_HV_02_XIX_HCP5_CANFD01:1023, compu {phys=raw*0.2 for raw 0..1021, 1022=Cx3fe_Init (CM_BMC_PerfInd_Laden_Cx3fe_Init), 1023=Cx3ff_Fehler (CM_BMC_PerfInd_Laden_Cx3ff_Fehler); unit Unit_PerCent}, range phys 0..204.2 Unit_PerCent, raw 0..1023, unit=Unit_PerCent  # Der Bereich 100...200% beschreibt die verbleibende Reserve, bis ein Derating der maximalen Ladeleistungsgrenze eintritt. Werte von 0 bis 100% beschreiben, auf welchen Teil der potentiell möglichen maximalen Ladeleistung die Ladeleistungsgrenze zurückgefahren worden ist.
    signal BMC_Max_Entladeleistung_XIX_BMC_HV_02_XIX_HCP5_CANFD01: start 32, 13 bit, little-endian, data-type-policy=OVERRIDE, i-signal-type=PRIMITIVE, init-value=8190, base-type=BT_BMC_Max_Entladeleistung, invalid-value=Invalid_BMC_Max_Entladeleistung_XIX_BMC_HV_02_XIX_HCP5_CANFD01:8191, compu {phys=raw*100 for raw 0..8189, 8190=Cx1ffe_Init (CM_BMC_Max_Entladeleistung_Cx1ffe_Init), 8191=Cx1fff_Fehler (CM_BMC_Max_Entladeleistung_Cx1fff_Fehler); unit Unit_Watt}, range phys 0..818900 Unit_Watt, raw 0..8191, unit=Unit_Watt  # Maximale Leistung, mit der die Batterie momentan belastet werden darf. Kurze Überschwinger aufgrund dynamischen Verhalten des Reglers sind nach Absprache möglich, aber hierbei muss unbedingt auch der maximale Entladestrom berücksichtigt werden.
    signal BMC_Status_DCLS_XIX_BMC_HV_02_XIX_HCP5_CANFD01: start 45, 2 bit, little-endian, data-type-policy=OVERRIDE, i-signal-type=PRIMITIVE, init-value=0, base-type=BT_BMC_Status_DCLS, compu {0=Cx0_inaktiv (CM_BMC_Status_DCLS_Cx0_inaktiv), 1=Cx1_i_O (CM_BMC_Status_DCLS_Cx1_i_O), 2=Cx2_n_i_O (CM_BMC_Status_DCLS_Cx2_n_i_O), 3=Cx3_aktiv (CM_BMC_Status_DCLS_Cx3_aktiv)}, range raw 0..3  # Status der Spannungsüberwachung an der DC-Ladeschnittstelle
    signal BMC_Bank_Notlauf_erlaubt_XIX_BMC_HV_02_XIX_HCP5_CANFD01: start 47, 1 bit, little-endian, data-type-policy=OVERRIDE, i-signal-type=PRIMITIVE, init-value=1, base-type=BT_BMC_Bank_Notlauf_erlaubt, compu {0=Cx0_inaktiv (CM_BMC_Bank_Notlauf_erlaubt_Cx0_inaktiv), 1=Cx1_aktiv (CM_BMC_Bank_Notlauf_erlaubt_Cx1_aktiv)}, range raw 0..1  # Feedback von BMC Notlauf
    signal BMC_Energieinhalt_XIX_BMC_HV_02_XIX_HCP5_CANFD01: start 48, 16 bit, little-endian, data-type-policy=OVERRIDE, i-signal-type=PRIMITIVE, init-value=65534, base-type=BT_BMC_Energieinhalt, invalid-value=Invalid_BMC_Energieinhalt_XIX_BMC_HV_02_XIX_HCP5_CANFD01:65535, compu {phys=raw*4 for raw 0..65533, 65534=Cxfffe_Init (CM_BMC_Energieinhalt_Cxfffe_Init), 65535=Cxffff_Fehler (CM_BMC_Energieinhalt_Cxffff_Fehler); unit Unit_WattHour}, range phys 0..262132 Unit_WattHour, raw 0..65535, unit=Unit_WattHour  # Aktueller Energieinhalt der Batterie unter Beruecksichtigung der Verluste (I_RWDS)
    signal BMC_Max_Ladeleistung_XIX_BMC_HV_02_XIX_HCP5_CANFD01: start 64, 13 bit, little-endian, data-type-policy=OVERRIDE, i-signal-type=PRIMITIVE, init-value=8190, base-type=BT_BMC_Max_Ladeleistung, invalid-value=Invalid_BMC_Max_Ladeleistung_XIX_BMC_HV_02_XIX_HCP5_CANFD01:8191, compu {phys=raw*100 for raw 0..8189, 8190=Cx1ffe_Init (CM_BMC_Max_Ladeleistung_Cx1ffe_Init), 8191=Cx1fff_Fehler (CM_BMC_Max_Ladeleistung_Cx1fff_Fehler); unit Unit_Watt}, range phys 0..818900 Unit_Watt, raw 0..8191, unit=Unit_Watt  # Maximale Leistung, mit der die Batterie aktuell geladen werden darf.Kurze Überschwinger aufgrund dynamischen Verhalten des Reglers sind nach Absprache möglich, aber hierbei muss unbedingt auch der maximale Ladestrom berücksichtigt werden.
    signal BMC_PerfInd_Entladen_XIX_BMC_HV_02_XIX_HCP5_CANFD01: start 77, 10 bit, little-endian, data-type-policy=OVERRIDE, i-signal-type=PRIMITIVE, init-value=1022, base-type=BT_BMC_PerfInd_Entladen, invalid-value=Invalid_BMC_PerfInd_Entladen_XIX_BMC_HV_02_XIX_HCP5_CANFD01:1023, compu {phys=raw*0.2 for raw 0..1021, 1022=Cx3fe_Init (CM_BMC_PerfInd_Entladen_Cx3fe_Init), 1023=Cx3ff_Fehler (CM_BMC_PerfInd_Entladen_Cx3ff_Fehler); unit Unit_PerCent}, range phys 0..204.2 Unit_PerCent, raw 0..1023, unit=Unit_PerCent  # Der Bereich 100...200% beschreibt die verbleibende Reserve, bis ein Derating der maximalen Entladeleistungsgrenze eintritt. Werte von 0 bis 100% beschreiben, auf welchen Teil der potentiell möglichen maximalen Entladeleistung die Entladeleistungsgrenze zurückgefahren worden ist.
    signal BMC_Bank_parallel_erlaubt_XIX_BMC_HV_02_XIX_HCP5_CANFD01: start 87, 1 bit, little-endian, data-type-policy=OVERRIDE, i-signal-type=PRIMITIVE, init-value=1, base-type=BT_BMC_Bank_parallel_erlaubt, compu {0=Cx0_inaktiv (CM_BMC_Bank_parallel_erlaubt_Cx0_inaktiv), 1=Cx1_aktiv (CM_BMC_Bank_parallel_erlaubt_Cx1_aktiv)}, range raw 0..1  # Feedback von BMC ob paralleler Betrieb unterstützt ist
    signal BMC_Bank_seriell_erlaubt_XIX_BMC_HV_02_XIX_HCP5_CANFD01: start 88, 1 bit, little-endian, data-type-policy=OVERRIDE, i-signal-type=PRIMITIVE, init-value=1, base-type=BT_BMC_Bank_seriell_erlaubt, compu {0=Cx0_inaktiv (CM_BMC_Bank_seriell_erlaubt_Cx0_inaktiv), 1=Cx1_aktiv (CM_BMC_Bank_seriell_erlaubt_Cx1_aktiv)}, range raw 0..1  # Feedback von BMC ob serieller Betrieb unterstützt ist
    signal BMC_Spannung_DC_Ladesaeule_XIX_BMC_HV_02_XIX_HCP5_CANFD01: start 89, 15 bit, little-endian, data-type-policy=OVERRIDE, i-signal-type=PRIMITIVE, init-value=32766, base-type=BT_BMC_Spannung_DC_Ladesaeule, invalid-value=Invalid_BMC_Spannung_DC_Ladesaeule_XIX_BMC_HV_02_XIX_HCP5_CANFD01:32767, compu {phys=raw*0.0625-1023 for raw 0..32764, 32765=Cx7ffd_nicht_messbar (CM_BMC_Spannung_DC_Ladesaeule_Cx7ffd_nicht_messbar), 32766=Cx7ffe_Init (CM_BMC_Spannung_DC_Ladesaeule_Cx7ffe_Init), 32767=Cx7fff_Fehler (CM_BMC_Spannung_DC_Ladesaeule_Cx7fff_Fehler); unit Unit_Volt}, range phys -1023..1024.75 Unit_Volt, raw 0..32767, unit=Unit_Volt  # DC-Spannung der Ladesaeule. Messung zwischen den DC HV-Leitungen.
    signal BMC_Max_Ladestrom_XIX_BMC_HV_02_XIX_HCP5_CANFD01: start 104, 13 bit, little-endian, data-type-policy=OVERRIDE, i-signal-type=PRIMITIVE, init-value=8190, base-type=BT_BMC_Max_Ladestrom, invalid-value=Invalid_BMC_Max_Ladestrom_XIX_BMC_HV_02_XIX_HCP5_CANFD01:8191, compu {phys=raw*0.2 for raw 0..8189, 8190=Cx1ffe_Init (CM_BMC_Max_Ladestrom_Cx1ffe_Init), 8191=Cx1fff_Fehler (CM_BMC_Max_Ladestrom_Cx1fff_Fehler); unit Unit_Amper}, range phys 0..1637.8 Unit_Amper, raw 0..8191, unit=Unit_Amper  # Zwingend einzuhaltender Grenzwert für den Ladestrom der Batterie.Verletzungen werden protokolliert.
    signal BMC_Max_Entladestrom_XIX_BMC_HV_02_XIX_HCP5_CANFD01: start 117, 13 bit, little-endian, data-type-policy=OVERRIDE, i-signal-type=PRIMITIVE, init-value=8190, base-type=BT_BMC_Max_Entladestrom, invalid-value=Invalid_BMC_Max_Entladestrom_XIX_BMC_HV_02_XIX_HCP5_CANFD01:8191, compu {phys=raw*0.2 for raw 0..8189, 8190=Cx1ffe_Init (CM_BMC_Max_Entladestrom_Cx1ffe_Init), 8191=Cx1fff_Fehler (CM_BMC_Max_Entladestrom_Cx1fff_Fehler); unit Unit_Amper}, range phys 0..1637.8 Unit_Amper, raw 0..8191, unit=Unit_Amper  # Zwingend einzuhaltender Grenzwert für den Entladestrom der Batterie. Verletzungen werden protokolliert.
    signal BMC_IWU_Status_XIX_BMC_HV_02_XIX_HCP5_CANFD01: start 130, 3 bit, little-endian, data-type-policy=OVERRIDE, i-signal-type=PRIMITIVE, init-value=0, base-type=BT_BMC_IWU_Status, compu {0=Cx0_Init (CM_BMC_IWU_Status_Cx0_Init), 1=Cx1_IWU_defekt (CM_BMC_IWU_Status_Cx1_IWU_defekt), 2=Cx2_kein_Messwert (CM_BMC_IWU_Status_Cx2_kein_Messwert), 3=Cx3_ISO_Messung_aktiv (CM_BMC_IWU_Status_Cx3_ISO_Messung_aktiv), 4=Cx4_Deaktiviert (CM_BMC_IWU_Status_Cx4_Deaktiviert), 5=Cx5_ISO_Messung_abgeschlossen (CM_BMC_IWU_Status_Cx5_ISO_Messung_abgeschlossen), 6=Cx6_ISO_Messung_extern (CM_BMC_IWU_Status_Cx6_ISO_Messung_extern)}, range raw 0..6  # Status der Iso-Messstelle
    signal BMC_Verbauinfo_ACSchuetz_XIX_BMC_HV_02_XIX_HCP5_CANFD01: start 133, 2 bit, little-endian, data-type-policy=OVERRIDE, i-signal-type=PRIMITIVE, init-value=0, base-type=BT_BMC_Verbauinfo_ACSchuetz, compu {0=Cx0_Init (CM_BMC_Verbauinfo_ACSchuetz_Cx0_Init), 1=Cx1_nicht_verbaut (CM_BMC_Verbauinfo_ACSchuetz_Cx1_nicht_verbaut), 2=Cx2_verbaut (CM_BMC_Verbauinfo_ACSchuetz_Cx2_verbaut)}, range raw 0..2  # Verbauzustand des HV-Schützes für den separaten Zwischenkreis des AC-Ladegerätes
    signal Hybrid_01_OBD_Lampe_Anf_XIX_BMC_HV_02_XIX_HCP5_CANFD01: start 135, 1 bit, little-endian, data-type-policy=OVERRIDE, i-signal-type=PRIMITIVE, init-value=0, base-type=BT_Hybrid_01_OBD_Lampe_Anf, compu {0=Cx0_Kein_MIL_Request (CM_Hybrid_01_OBD_Lampe_Anf_Cx0_Kein_MIL_Request) (Kein MIL_Request), 1=Cx1_MIL_Request (CM_Hybrid_01_OBD_Lampe_Anf_Cx1_MIL_Request)}, range raw 0..1  # In allen VW-/Audi-Fahrzeugen ist ein MIL-Master-Konzept umgesetzt. Dazu ermittelt jedes OBD-Steuergerät den eigenen MIL-Status. Eine MIL-Ansteuerung wird vom betroffenen OBD-Steuergerät per MIL-Request an den MIL-Master weitergegeben.
    signal BMC_Fehler_Warnung_XIX_BMC_HV_02_XIX_HCP5_CANFD01: start 136, 2 bit, little-endian, data-type-policy=OVERRIDE, i-signal-type=PRIMITIVE, init-value=0, base-type=BT_BMC_Fehler_Warnung, compu {0=Cx0_Keine_Warnung (CM_BMC_Fehler_Warnung_Cx0_Keine_Warnung), 1=Cx1_Warnung_ohne_Leistungseinschraenkung (CM_BMC_Fehler_Warnung_Cx1_Warnung_ohne_Leistungseinschraenkung) (Warnung_ohne_Leistungseinschränkung), 2=Cx2_Warnung_mit_Leistungseinschraenkung (CM_BMC_Fehler_Warnung_Cx2_Warnung_mit_Leistungseinschraenkung) (Warnung_mit_Leistungseinschränkung)}, range raw 0..2  # Fehlersignalisierung eines Komponentenfehlers ohne HV-Abschaltung jedoch mit potentieller Leistungseinschränkung
    signal BMC_MMTR_Status_XIX_BMC_HV_02_XIX_HCP5_CANFD01: start 138, 4 bit, little-endian, data-type-policy=OVERRIDE, i-signal-type=PRIMITIVE, init-value=14, base-type=BT_BMC_MMTR_Status, invalid-value=Invalid_BMC_MMTR_Status_XIX_BMC_HV_02_XIX_HCP5_CANFD01:15, compu {0=Cx0_Nicht_verfuegbar (CM_BMC_MMTR_Status_Cx0_Nicht_verfuegbar), 1=Cx1_Inaktiv (CM_BMC_MMTR_Status_Cx1_Inaktiv), 2=Cx2_Aktiv_Vorkonditionierung (CM_BMC_MMTR_Status_Cx2_Aktiv_Vorkonditionierung), 3=Cx3_Aktiv_TrackSession (CM_BMC_MMTR_Status_Cx3_Aktiv_TrackSession), 4=Cx4_Nicht_verfuegbar_Lebensdauertimer (CM_BMC_MMTR_Status_Cx4_Nicht_verfuegbar_Lebensdauertimer), 5=Cx5_Abgeschlossen_Vorkonditionierung (CM_BMC_MMTR_Status_Cx5_Abgeschlossen_Vorkonditionierung), 6=Cx6_Aktiv_Rueckkehrstrategie (CM_BMC_MMTR_Status_Cx6_Aktiv_Rueckkehrstrategie), 14=Cxe_Init (CM_BMC_MMTR_Status_Cxe_Init), 15=Cxf_Fehler (CM_BMC_MMTR_Status_Cxf_Fehler)}, range raw 0..15  # Status der Hochvoltbatterie zur Funktion Make me track ready
    signal ISignalVoid_BMC_HV_02_XIX_HCP5_CANFD01_0: start 142, 2 bit, little-endian, system signal SignalVoid_BMC_HV_02_0, data-type-policy=OVERRIDE, i-signal-type=PRIMITIVE, base-type=BT_SignalVoid
    signal BMC_DC_Laden_XIX_BMC_HV_02_XIX_HCP5_CANFD01: start 144, 2 bit, little-endian, data-type-policy=OVERRIDE, i-signal-type=PRIMITIVE, init-value=0, base-type=BT_BMC_DC_Laden, invalid-value=Invalid_BMC_DC_Laden_XIX_BMC_HV_02_XIX_HCP5_CANFD01:3, compu {0=Cx0_Init (CM_BMC_DC_Laden_Cx0_Init), 1=Cx1_nicht_vorhanden (CM_BMC_DC_Laden_Cx1_nicht_vorhanden), 2=Cx2_vorhanden (CM_BMC_DC_Laden_Cx2_vorhanden), 3=Cx3_Fehler (CM_BMC_DC_Laden_Cx3_Fehler)}, range raw 0..3  # Verfügbarkeit der HV-Batterie für einen DC-Ladevorgang
    signal BMC_AC_Laden_XIX_BMC_HV_02_XIX_HCP5_CANFD01: start 146, 2 bit, little-endian, data-type-policy=OVERRIDE, i-signal-type=PRIMITIVE, init-value=0, base-type=BT_BMC_AC_Laden, invalid-value=Invalid_BMC_AC_Laden_XIX_BMC_HV_02_XIX_HCP5_CANFD01:3, compu {0=Cx0_Init (CM_BMC_AC_Laden_Cx0_Init), 1=Cx1_nicht_vorhanden (CM_BMC_AC_Laden_Cx1_nicht_vorhanden), 2=Cx2_vorhanden (CM_BMC_AC_Laden_Cx2_vorhanden), 3=Cx3_Fehler (CM_BMC_AC_Laden_Cx3_Fehler)}, range raw 0..3  # Verfügbarkeit der HV-Batterie für einen AC-Ladevorgang
    signal BMC_NutzbarerSOC_XIX_BMC_HV_02_XIX_HCP5_CANFD01: start 148, 12 bit, little-endian, data-type-policy=OVERRIDE, i-signal-type=PRIMITIVE, init-value=4094, base-type=BT_BMC_NutzbarerSOC, invalid-value=Invalid_BMC_NutzbarerSOC_XIX_BMC_HV_02_XIX_HCP5_CANFD01:4095, compu {phys=raw*0.05-20 for raw 0..4093, 4094=Cxffe_Init (CM_BMC_NutzbarerSOC_Cxffe_Init), 4095=Cxfff_Fehler (CM_BMC_NutzbarerSOC_Cxfff_Fehler); unit Unit_PerCent}, range phys -20..184.65 Unit_PerCent, raw 0..4095, unit=Unit_PerCent  # Aktueller relativer Ladezustand der HV-Batterie/Der angezeigte Bereich für Kunde ist von 0-100%/Reserve wird im negativen Bereich abgebildet/Werte über 100% signalisieren eine unzulässige Überladung. Physikalischer Wertebereich liegt zw. -20% bis 120%.
    signal BMC_IWU_Wert_neg_XIX_BMC_HV_02_XIX_HCP5_CANFD01: start 160, 16 bit, little-endian, data-type-policy=OVERRIDE, i-signal-type=PRIMITIVE, init-value=65534, base-type=BT_BMC_IWU_Wert_neg, invalid-value=Invalid_BMC_IWU_Wert_neg_XIX_BMC_HV_02_XIX_HCP5_CANFD01:65535, compu {phys=raw*100 for raw 0..65532, 65533=Cxfffd_kein_Messwert (CM_BMC_IWU_Wert_neg_Cxfffd_kein_Messwert), 65534=Cxfffe_Init (CM_BMC_IWU_Wert_neg_Cxfffe_Init), 65535=Cxffff_Fehler (CM_BMC_IWU_Wert_neg_Cxffff_Fehler); unit Unit_Ohm}, range phys 0..6553200 Unit_Ohm, raw 0..65535, unit=Unit_Ohm  # Aktueller Isolationswert zwischen HV minus und Fahrzeug
    signal BMC_IWU_Wert_pos_XIX_BMC_HV_02_XIX_HCP5_CANFD01: start 176, 16 bit, little-endian, data-type-policy=OVERRIDE, i-signal-type=PRIMITIVE, init-value=65534, base-type=BT_BMC_IWU_Wert_pos, invalid-value=Invalid_BMC_IWU_Wert_pos_XIX_BMC_HV_02_XIX_HCP5_CANFD01:65535, compu {phys=raw*100 for raw 0..65532, 65533=Cxfffd_kein_Messwert (CM_BMC_IWU_Wert_pos_Cxfffd_kein_Messwert), 65534=Cxfffe_Init (CM_BMC_IWU_Wert_pos_Cxfffe_Init), 65535=Cxffff_Fehler (CM_BMC_IWU_Wert_pos_Cxffff_Fehler); unit Unit_Ohm}, range phys 0..6553200 Unit_Ohm, raw 0..65535, unit=Unit_Ohm  # Aktueller Isolationswert zwischen HV plus und Fahrzeug
    signal Anzeige_SOC_XIX_BMC_HV_02_XIX_HCP5_CANFD01: start 192, 10 bit, little-endian, data-type-policy=OVERRIDE, i-signal-type=PRIMITIVE, init-value=1022, base-type=BT_Anzeige_SOC, invalid-value=Invalid_Anzeige_SOC_XIX_BMC_HV_02_XIX_HCP5_CANFD01:1023, compu {phys=raw*0.1 for raw 0..1000, 1001=Cx3e9_reserviert (CM_Anzeige_SOC_Cx3e9_reserviert), 1002=Cx3ea_reserviert (CM_Anzeige_SOC_Cx3ea_reserviert), 1003=Cx3eb_reserviert (CM_Anzeige_SOC_Cx3eb_reserviert), 1004=Cx3ec_reserviert (CM_Anzeige_SOC_Cx3ec_reserviert), 1005=Cx3ed_reserviert (CM_Anzeige_SOC_Cx3ed_reserviert), 1006=Cx3ee_reserviert (CM_Anzeige_SOC_Cx3ee_reserviert), 1007=Cx3ef_reserviert (CM_Anzeige_SOC_Cx3ef_reserviert), 1008=Cx3f0_reserviert (CM_Anzeige_SOC_Cx3f0_reserviert), 1009=Cx3f1_reserviert (CM_Anzeige_SOC_Cx3f1_reserviert), 1010=Cx3f2_reserviert (CM_Anzeige_SOC_Cx3f2_reserviert), 1011=Cx3f3_reserviert (CM_Anzeige_SOC_Cx3f3_reserviert), 1012=Cx3f4_reserviert (CM_Anzeige_SOC_Cx3f4_reserviert), 1013=Cx3f5_reserviert (CM_Anzeige_SOC_Cx3f5_reserviert), 1014=Cx3f6_reserviert (CM_Anzeige_SOC_Cx3f6_reserviert), 1015=Cx3f7_reserviert (CM_Anzeige_SOC_Cx3f7_reserviert), 1016=Cx3f8_reserviert (CM_Anzeige_SOC_Cx3f8_reserviert), 1017=Cx3f9_reserviert (CM_Anzeige_SOC_Cx3f9_reserviert), 1018=Cx3fa_reserviert (CM_Anzeige_SOC_Cx3fa_reserviert), 1019=Cx3fb_reserviert (CM_Anzeige_SOC_Cx3fb_reserviert), 1020=Cx3fc_reserviert (CM_Anzeige_SOC_Cx3fc_reserviert), 1021=Cx3fd_reserviert (CM_Anzeige_SOC_Cx3fd_reserviert), 1022=Cx3fe_Init (CM_Anzeige_SOC_Cx3fe_Init), 1023=Cx3ff_Fehler (CM_Anzeige_SOC_Cx3ff_Fehler); unit Unit_PerCent}, range phys 0..100 Unit_PerCent, raw 0..1023, unit=Unit_PerCent  # Der Anzeige-SOC soll für alle Energiestandsanzeigen der Batterie vor Kunde verwendet werden.
    signal BMC_Verbauinfo_Bank_XIX_BMC_HV_02_XIX_HCP5_CANFD01: start 202, 2 bit, little-endian, data-type-policy=OVERRIDE, i-signal-type=PRIMITIVE, init-value=0, base-type=BT_BMC_Verbauinfo_Bank, compu {0=Cx0_Init (CM_BMC_Verbauinfo_Bank_Cx0_Init), 1=Cx1_nicht_verbaut (CM_BMC_Verbauinfo_Bank_Cx1_nicht_verbaut), 2=Cx2_verbaut (CM_BMC_Verbauinfo_Bank_Cx2_verbaut)}, range raw 0..2  # Verbauzustand einer Bankverschaltung in der HV-Batterie
    signal BMC_Fehler_Leistungsred_XIX_BMC_HV_02_XIX_HCP5_CANFD01: start 204, 1 bit, little-endian, data-type-policy=OVERRIDE, i-signal-type=PRIMITIVE, init-value=0, base-type=BT_BMC_Fehler_Leistungsred, compu {0=Cx0_kein_Fehler (CM_BMC_Fehler_Leistungsred_Cx0_kein_Fehler), 1=Cx1_Fehler_Leistungsred (CM_BMC_Fehler_Leistungsred_Cx1_Fehler_Leistungsred)}, range raw 0..1  # Statusinformation bei aktiver Leistungsreduktion aufgrund eines Batteriefehlers
    signal BMC_Unterboden_Warnung_XIX_BMC_HV_02_XIX_HCP5_CANFD01: start 205, 3 bit, little-endian, data-type-policy=OVERRIDE, i-signal-type=PRIMITIVE, init-value=0, base-type=BT_BMC_Unterboden_Warnung, invalid-value=Invalid_BMC_Unterboden_Warnung_XIX_BMC_HV_02_XIX_HCP5_CANFD01:7, compu {0=Cx0_BMC_Unterboden_Warnung_keine_Warnung (CM_BMC_Unterboden_Warnung_Cx0_BMC_Unterboden_Warnung_keine_Warnung) (BMC_Unterboden_Warnung=keine_Warnung), 1=Cx1_BMC_Unterboden_Warnung_1 (CM_BMC_Unterboden_Warnung_Cx1_BMC_Unterboden_Warnung_1) (BMC_Unterboden_Warnung=1), 2=Cx2_BMC_Unterboden_Warnung_2 (CM_BMC_Unterboden_Warnung_Cx2_BMC_Unterboden_Warnung_2) (BMC_Unterboden_Warnung=2), 3=Cx3_BMC_Unterboden_Warnung_3 (CM_BMC_Unterboden_Warnung_Cx3_BMC_Unterboden_Warnung_3) (BMC_Unterboden_Warnung=3), 4=Cx4_BMC_Unterboden_Warnung_4 (CM_BMC_Unterboden_Warnung_Cx4_BMC_Unterboden_Warnung_4) (BMC_Unterboden_Warnung=4), 5=Cx5_BMC_Unterboden_Warnung_5 (CM_BMC_Unterboden_Warnung_Cx5_BMC_Unterboden_Warnung_5) (BMC_Unterboden_Warnung=5), 6=Cx6_BMC_Unterboden_Warnung_6 (CM_BMC_Unterboden_Warnung_Cx6_BMC_Unterboden_Warnung_6) (BMC_Unterboden_Warnung=6), 7=Cx7_Fehler (CM_BMC_Unterboden_Warnung_Cx7_Fehler)}, range raw 0..7  # Warnung bei Unterbodenbeschaedigung der HV Batterie
    signal BMC_MinDyn_Entladespannung_XIX_BMC_HV_02_XIX_HCP5_CANFD01: start 208, 10 bit, little-endian, data-type-policy=OVERRIDE, i-signal-type=PRIMITIVE, init-value=1022, base-type=BT_BMC_MinDyn_Entladespannung, invalid-value=Invalid_BMC_MinDyn_Entladespannung_XIX_BMC_HV_02_XIX_HCP5_CANFD01:1023, compu {phys=raw for raw 0..1021, 1022=Cx3fe_Init (CM_BMC_MinDyn_Entladespannung_Cx3fe_Init), 1023=Cx3ff_Fehler (CM_BMC_MinDyn_Entladespannung_Cx3ff_Fehler); unit Unit_None}, range phys 0..1021 Unit_None, raw 0..1023, unit=Unit_None  # rechnerischer Wert: minimales, für eine Dauer von ~1s garantiertes Spannungsniveau, das unter Belastung mit BMC_Max_EntladeLeistung nicht unterschritten wird
    signal BMC_MinDyn_Ladespannung_XIX_BMC_HV_02_XIX_HCP5_CANFD01: start 218, 10 bit, little-endian, data-type-policy=OVERRIDE, i-signal-type=PRIMITIVE, init-value=1022, base-type=BT_BMC_MinDyn_Ladespannung, invalid-value=Invalid_BMC_MinDyn_Ladespannung_XIX_BMC_HV_02_XIX_HCP5_CANFD01:1023, compu {phys=raw for raw 0..1021, 1022=Cx3fe_Init (CM_BMC_MinDyn_Ladespannung_Cx3fe_Init), 1023=Cx3ff_Fehler (CM_BMC_MinDyn_Ladespannung_Cx3ff_Fehler); unit Unit_Volt}, range phys 0..1021 Unit_Volt, raw 0..1023, unit=Unit_Volt  # rechnerischer Wert: minimales, für eine Dauer von ~1s garantiertes Spannungsniveau, das unter Belastung mit BMC_Max_LadeLeistung nicht unterschritten wird
    signal BMC_Leerlaufspannung_XIX_BMC_HV_02_XIX_HCP5_CANFD01: start 228, 10 bit, little-endian, data-type-policy=OVERRIDE, i-signal-type=PRIMITIVE, init-value=1022, base-type=BT_BMC_Leerlaufspannung, invalid-value=Invalid_BMC_Leerlaufspannung_XIX_BMC_HV_02_XIX_HCP5_CANFD01:1023, compu {phys=raw for raw 0..1021, 1022=Cx3fe_Init (CM_BMC_Leerlaufspannung_Cx3fe_Init), 1023=Cx3ff_Fehler (CM_BMC_Leerlaufspannung_Cx3ff_Fehler); unit Unit_Volt}, range phys 0..1021 Unit_Volt, raw 0..1023, unit=Unit_Volt  # Lastfreie Spannung der HV Batterie
    signal BMC_IstZellspannungMax_XIX_BMC_HV_02_XIX_HCP5_CANFD01: start 238, 12 bit, little-endian, data-type-policy=OVERRIDE, i-signal-type=PRIMITIVE, init-value=4094, base-type=BT_BMC_IstZellspannungMax, invalid-value=Invalid_BMC_IstZellspannungMax_XIX_BMC_HV_02_XIX_HCP5_CANFD01:4095, compu {phys=raw+1000 for raw 0..4091, 4092=Cxffc_kleiner_1V (CM_BMC_IstZellspannungMax_Cxffc_kleiner_1V), 4093=Cxffd_reserviert (CM_BMC_IstZellspannungMax_Cxffd_reserviert), 4094=Cxffe_Init (CM_BMC_IstZellspannungMax_Cxffe_Init), 4095=Cxfff_Fehler (CM_BMC_IstZellspannungMax_Cxfff_Fehler); unit Unit_MilliVolt}, range phys 1000..5091 Unit_MilliVolt, raw 0..4095, unit=Unit_MilliVolt  # Aktuell höchste Zellspannung in der Batterie
    signal BMC_IstZellspannungMin_XIX_BMC_HV_02_XIX_HCP5_CANFD01: start 250, 12 bit, little-endian, data-type-policy=OVERRIDE, i-signal-type=PRIMITIVE, init-value=4094, base-type=BT_BMC_IstZellspannungMin, invalid-value=Invalid_BMC_IstZellspannungMin_XIX_BMC_HV_02_XIX_HCP5_CANFD01:4095, compu {phys=raw+1000 for raw 0..4091, 4092=Cxffc_kleiner_1V (CM_BMC_IstZellspannungMin_Cxffc_kleiner_1V), 4093=Cxffd_reserviert (CM_BMC_IstZellspannungMin_Cxffd_reserviert), 4094=Cxffe_Init (CM_BMC_IstZellspannungMin_Cxffe_Init), 4095=Cxfff_Fehler (CM_BMC_IstZellspannungMin_Cxfff_Fehler); unit Unit_MilliVolt}, range phys 1000..5091 Unit_MilliVolt, raw 0..4095, unit=Unit_MilliVolt  # Aktuell niedrigste Zellspannung in der Batterie
    signal BMC_PredLeistung_StuetzungNV_XIX_BMC_HV_02_XIX_HCP5_CANFD01: start 262, 12 bit, little-endian, data-type-policy=OVERRIDE, i-signal-type=PRIMITIVE, init-value=4094, base-type=BT_BMC_PredLeistung_StuetzungNV, invalid-value=Invalid_BMC_PredLeistung_StuetzungNV_XIX_BMC_HV_02_XIX_HCP5_CANFD01:4095, compu {phys=raw*200 for raw 0..4092, 4093=Cxffd_keine_Berechnung (CM_BMC_PredLeistung_StuetzungNV_Cxffd_keine_Berechnung) (keine Berechnung), 4094=Cxffe_Init (CM_BMC_PredLeistung_StuetzungNV_Cxffe_Init), 4095=Cxfff_Fehler (CM_BMC_PredLeistung_StuetzungNV_Cxfff_Fehler); unit Unit_Watt}, range phys 0..818400 Unit_Watt, raw 0..4095, unit=Unit_Watt  # Entladeleistung der HV Batterie, garantiert für eine Periode von 2,5 Minuten unter der Annahme, dass diese nicht überschritten wird.
    signal BMC_TechnischerSOC_XIX_BMC_HV_02_XIX_HCP5_CANFD01: start 274, 11 bit, little-endian, data-type-policy=OVERRIDE, i-signal-type=PRIMITIVE, init-value=2046, base-type=BT_BMC_TechnischerSOC, invalid-value=Invalid_BMC_TechnischerSOC_XIX_BMC_HV_02_XIX_HCP5_CANFD01:2047, compu {phys=raw*0.05 for raw 0..2000, 2046=Cx7fe_Init (CM_BMC_TechnischerSOC_Cx7fe_Init), 2047=Cx7ff_Fehler (CM_BMC_TechnischerSOC_Cx7ff_Fehler); unit Unit_PerCent}, range phys 0..100 Unit_PerCent, raw 0..2047, unit=Unit_PerCent  # State of Charge / aktueller Ladezustand der Batterie (höhere Auflösung)/technischer SOC
    signal BMC_Energie_Sockel_SoC_XIX_BMC_HV_02_XIX_HCP5_CANFD01: start 285, 10 bit, little-endian, data-type-policy=OVERRIDE, i-signal-type=PRIMITIVE, init-value=1022, base-type=BT_BMC_Energie_Sockel_SoC, invalid-value=Invalid_BMC_Energie_Sockel_SoC_XIX_BMC_HV_02_XIX_HCP5_CANFD01:1023, compu {phys=raw*0.1 for raw 0..1000, 1001=Cx3e9_reserviert (CM_BMC_Energie_Sockel_SoC_Cx3e9_reserviert), 1002=Cx3ea_reserviert (CM_BMC_Energie_Sockel_SoC_Cx3ea_reserviert), 1003=Cx3eb_reserviert (CM_BMC_Energie_Sockel_SoC_Cx3eb_reserviert), 1004=Cx3ec_reserviert (CM_BMC_Energie_Sockel_SoC_Cx3ec_reserviert), 1005=Cx3ed_reserviert (CM_BMC_Energie_Sockel_SoC_Cx3ed_reserviert), 1006=Cx3ee_reserviert (CM_BMC_Energie_Sockel_SoC_Cx3ee_reserviert), 1007=Cx3ef_reserviert (CM_BMC_Energie_Sockel_SoC_Cx3ef_reserviert), 1008=Cx3f0_reserviert (CM_BMC_Energie_Sockel_SoC_Cx3f0_reserviert), 1009=Cx3f1_reserviert (CM_BMC_Energie_Sockel_SoC_Cx3f1_reserviert), 1010=Cx3f2_reserviert (CM_BMC_Energie_Sockel_SoC_Cx3f2_reserviert), 1011=Cx3f3_reserviert (CM_BMC_Energie_Sockel_SoC_Cx3f3_reserviert), 1012=Cx3f4_reserviert (CM_BMC_Energie_Sockel_SoC_Cx3f4_reserviert), 1013=Cx3f5_reserviert (CM_BMC_Energie_Sockel_SoC_Cx3f5_reserviert), 1014=Cx3f6_reserviert (CM_BMC_Energie_Sockel_SoC_Cx3f6_reserviert), 1015=Cx3f7_reserviert (CM_BMC_Energie_Sockel_SoC_Cx3f7_reserviert), 1016=Cx3f8_reserviert (CM_BMC_Energie_Sockel_SoC_Cx3f8_reserviert), 1017=Cx3f9_reserviert (CM_BMC_Energie_Sockel_SoC_Cx3f9_reserviert), 1018=Cx3fa_reserviert (CM_BMC_Energie_Sockel_SoC_Cx3fa_reserviert), 1019=Cx3fb_reserviert (CM_BMC_Energie_Sockel_SoC_Cx3fb_reserviert), 1020=Cx3fc_reserviert (CM_BMC_Energie_Sockel_SoC_Cx3fc_reserviert), 1021=Cx3fd_reserviert (CM_BMC_Energie_Sockel_SoC_Cx3fd_reserviert), 1022=Cx3fe_Init (CM_BMC_Energie_Sockel_SoC_Cx3fe_Init), 1023=Cx3ff_Fehler (CM_BMC_Energie_Sockel_SoC_Cx3ff_Fehler); unit Unit_PerCent}, range phys 0..100 Unit_PerCent, raw 0..1023, unit=Unit_PerCent  # (Kunden-) SoC der Batterie für Energieinhalt=0
    signal BMC_ZellTemp_virtuell_min_XIX_BMC_HV_02_XIX_HCP5_CANFD01: start 295, 10 bit, little-endian, data-type-policy=OVERRIDE, i-signal-type=PRIMITIVE, init-value=1022, base-type=BT_BMC_ZellTemp_virtuell_min, invalid-value=Invalid_BMC_ZellTemp_virtuell_min_XIX_BMC_HV_02_XIX_HCP5_CANFD01:1023, compu {phys=raw*0.125-40 for raw 0..1020, 1021=Cx3fd_Nicht_verfuegbar (CM_BMC_ZellTemp_virtuell_min_Cx3fd_Nicht_verfuegbar), 1022=Cx3fe_Init (CM_BMC_ZellTemp_virtuell_min_Cx3fe_Init), 1023=Cx3ff_Fehler (CM_BMC_ZellTemp_virtuell_min_Cx3ff_Fehler); unit Unit_DegreCelsi}, range phys -40..87.5 Unit_DegreCelsi, raw 0..1023, unit=Unit_DegreCelsi  # Minimaler berechneter Wert der Zelltemperatur der HVB
    signal BMC_ZellTemp_virtuell_max_XIX_BMC_HV_02_XIX_HCP5_CANFD01: start 305, 10 bit, little-endian, data-type-policy=OVERRIDE, i-signal-type=PRIMITIVE, init-value=1022, base-type=BT_BMC_ZellTemp_virtuell_max, invalid-value=Invalid_BMC_ZellTemp_virtuell_max_XIX_BMC_HV_02_XIX_HCP5_CANFD01:1023, compu {phys=raw*0.125-40 for raw 0..1020, 1021=Cx3fd_Nicht_verfuegbar (CM_BMC_ZellTemp_virtuell_max_Cx3fd_Nicht_verfuegbar), 1022=Cx3fe_Init (CM_BMC_ZellTemp_virtuell_max_Cx3fe_Init), 1023=Cx3ff_Fehler (CM_BMC_ZellTemp_virtuell_max_Cx3ff_Fehler); unit Unit_DegreCelsi}, range phys -40..87.5 Unit_DegreCelsi, raw 0..1023, unit=Unit_DegreCelsi  # Maximaler berechneter Wert der Zelltemperatur der HVB
    signal ISignalVoid_BMC_HV_02_XIX_HCP5_CANFD01_1: start 315, 5 bit, little-endian, system signal SignalVoid_BMC_HV_02_1, data-type-policy=OVERRIDE, i-signal-type=PRIMITIVE, base-type=BT_SignalVoid
    signal ISignalVoid_BMC_HV_02_XIX_HCP5_CANFD01_2: start 320, 8 bit, little-endian, system signal SignalVoid_BMC_HV_02_2, data-type-policy=OVERRIDE, i-signal-type=PRIMITIVE, base-type=BT_SignalVoid
    signal ISignalVoid_BMC_HV_02_XIX_HCP5_CANFD01_3: start 328, 8 bit, little-endian, system signal SignalVoid_BMC_HV_02_3, data-type-policy=OVERRIDE, i-signal-type=PRIMITIVE, base-type=BT_SignalVoid
    signal ISignalVoid_BMC_HV_02_XIX_HCP5_CANFD01_4: start 336, 8 bit, little-endian, system signal SignalVoid_BMC_HV_02_4, data-type-policy=OVERRIDE, i-signal-type=PRIMITIVE, base-type=BT_SignalVoid
    signal ISignalVoid_BMC_HV_02_XIX_HCP5_CANFD01_5: start 344, 8 bit, little-endian, system signal SignalVoid_BMC_HV_02_5, data-type-policy=OVERRIDE, i-signal-type=PRIMITIVE, base-type=BT_SignalVoid
    mapping SG_BMC_HV_02_XIX_HCP5_CANFD01: i-signal-group=SG_BMC_HV_02_XIX_HCP5_CANFD01, transfer-property=TRIGGERED-WITHOUT-REPETITION
  pdu BMC_HV_06_XIX_HCP5_CANFD01: length=8, minimum-delay=0.05, transmission-mode-true-timing={cyclic-timing={time-offset=0, time-period=0.5}, event-controlled-timing={number-of-repetitions=0, repetition-period=0}}, unused-bit-pattern=0
    signal BMC_Max_Spannung_XIX_BMC_HV_06_XIX_HCP5_CANFD01: start 12, 10 bit, little-endian, data-type-policy=OVERRIDE, i-signal-type=PRIMITIVE, init-value=1022, base-type=BT_BMC_Max_Spannung, invalid-value=Invalid_BMC_Max_Spannung_XIX_BMC_HV_06_XIX_HCP5_CANFD01:1023, compu {phys=raw for raw 0..1021, 1022=Cx3fe_Init (CM_BMC_Max_Spannung_Cx3fe_Init), 1023=Cx3ff_Fehler (CM_BMC_Max_Spannung_Cx3ff_Fehler); unit Unit_Volt}, range phys 0..1021 Unit_Volt, raw 0..1023, unit=Unit_Volt, transfer-property=TRIGGERED-ON-CHANGE-WITHOUT-REPETITION  # max. voltage / maximal erlaubte Batteriespannung (zwingend einzuhaltender Grenzwert). Haengt vom Bank status ab. Bei NoBank wird der serielle Wert gesendet
    signal BMC_Min_Spannung_XIX_BMC_HV_06_XIX_HCP5_CANFD01: start 22, 10 bit, little-endian, data-type-policy=OVERRIDE, i-signal-type=PRIMITIVE, init-value=1022, base-type=BT_BMC_Min_Spannung, invalid-value=Invalid_BMC_Min_Spannung_XIX_BMC_HV_06_XIX_HCP5_CANFD01:1023, compu {phys=raw for raw 0..1021, 1022=Cx3fe_Init (CM_BMC_Min_Spannung_Cx3fe_Init), 1023=Cx3ff_Fehler (CM_BMC_Min_Spannung_Cx3ff_Fehler); unit Unit_Volt}, range phys 0..1021 Unit_Volt, raw 0..1023, unit=Unit_Volt, transfer-property=TRIGGERED-ON-CHANGE-WITHOUT-REPETITION  # min. voltage / minimal erlaubte Batteriespannung (zwingend einzuhaltender Grenzwert); Haengt vom Bank status ab. Bei NoBank wird der serielle Wert gesendet
    signal BMC_KundenWarnung_XIX_BMC_HV_06_XIX_HCP5_CANFD01: start 32, 2 bit, little-endian, data-type-policy=OVERRIDE, i-signal-type=PRIMITIVE, init-value=0, base-type=BT_BMC_KundenWarnung, compu {0=Cx0_keine_Warnung (CM_BMC_KundenWarnung_Cx0_keine_Warnung), 1=Cx1_Warnung_Temperaturlevel_1 (CM_BMC_KundenWarnung_Cx1_Warnung_Temperaturlevel_1), 2=Cx2_Warnung_Temperaturlevel_2 (CM_BMC_KundenWarnung_Cx2_Warnung_Temperaturlevel_2)}, range raw 0..2, transfer-property=TRIGGERED-ON-CHANGE-WITHOUT-REPETITION  # Kundenwarnung aufgrund eines Batteriefehlers
    signal BMC_Bidi_Veto_Energie_XIX_BMC_HV_06_XIX_HCP5_CANFD01: start 34, 1 bit, little-endian, data-type-policy=OVERRIDE, i-signal-type=PRIMITIVE, init-value=0, base-type=BT_BMC_Bidi_Veto_Energie, compu {0=Cx0_kein_Veto (CM_BMC_Bidi_Veto_Energie_Cx0_kein_Veto), 1=Cx1_Veto (CM_BMC_Bidi_Veto_Energie_Cx1_Veto)}, range raw 0..1, transfer-property=PENDING  # Freigabestatus der Funktion Bidi in Abhängigkeit des Energiedurchsatzes
    signal BMC_Bidi_Freigabe_XIX_BMC_HV_06_XIX_HCP5_CANFD01: start 35, 2 bit, little-endian, data-type-policy=OVERRIDE, i-signal-type=PRIMITIVE, init-value=2, base-type=BT_BMC_Bidi_Freigabe, invalid-value=Invalid_BMC_Bidi_Freigabe_XIX_BMC_HV_06_XIX_HCP5_CANFD01:3, compu {0=Cx0_entladen_nicht_erlaubt (CM_BMC_Bidi_Freigabe_Cx0_entladen_nicht_erlaubt), 1=Cx1_entladen_erlaubt (CM_BMC_Bidi_Freigabe_Cx1_entladen_erlaubt), 2=Cx2_Init (CM_BMC_Bidi_Freigabe_Cx2_Init), 3=Cx3_Fehler (CM_BMC_Bidi_Freigabe_Cx3_Fehler)}, range raw 0..3, transfer-property=PENDING  # Freigabestatus der Funktion Bidi in Abhängigkeit der Ist-Temperatur und des Energiedurchsatzes ermitteln. Die Basis SW sendet die Information von "Bidi-Status" auf dem CAN Signal BMC_Bidi_Freigabe an das Steuergerät HCP5.
    signal BMC_Bidi_Energie_Absolut_XIX_BMC_HV_06_XIX_HCP5_CANFD01: start 48, 16 bit, little-endian, data-type-policy=OVERRIDE, i-signal-type=PRIMITIVE, init-value=65534, base-type=BT_BMC_Bidi_Energie_Absolut, invalid-value=Invalid_BMC_Bidi_Energie_Absolut_XIX_BMC_HV_06_XIX_HCP5_CANFD01:65535, compu {phys=raw for raw 0..65533, 65534=Cxfffe_Init (CM_BMC_Bidi_Energie_Absolut_Cxfffe_Init), 65535=Cxffff_Fehler (CM_BMC_Bidi_Energie_Absolut_Cxffff_Fehler); unit Unit_KiloWattHour}, range phys 0..65533 Unit_KiloWattHour, raw 0..65535, unit=Unit_KiloWattHour, transfer-property=PENDING  # Beschreibt den maximal erlaubten Energiedurchsatz (Absolutwert, für Entladen) für die Funktion Bidi. Der Wert dient als zusätzliche Grenze für den Bauteilschutz der Zelle.
  pdu BMC_HV_07_XIX_HCP5_CANFD01: length=8, transmission-mode-true-timing=cyclic-timing={time-offset=0, time-period=0.2}, unused-bit-pattern=0
    signal BMC_Temperatur_hoechste_XIX_BMC_HV_07_XIX_HCP5_CANFD01: start 12, 10 bit, little-endian, data-type-policy=OVERRIDE, i-signal-type=PRIMITIVE, init-value=1022, base-type=BT_BMC_Temperatur_hoechste, invalid-value=Invalid_BMC_Temperatur_hoechste_XIX_BMC_HV_07_XIX_HCP5_CANFD01:1023, compu {phys=raw*0.125-40 for raw 0..1021, 1022=Cx3fe_Init (CM_BMC_Temperatur_hoechste_Cx3fe_Init), 1023=Cx3ff_Fehler (CM_BMC_Temperatur_hoechste_Cx3ff_Fehler); unit Unit_DegreCelsi}, range phys -40..87.625 Unit_DegreCelsi, raw 0..1023, unit=Unit_DegreCelsi, transfer-property=PENDING  # aktuell höchste Temperatur in der Batterie
    signal BMC_Temperatur_niedrigste_XIX_BMC_HV_07_XIX_HCP5_CANFD01: start 22, 10 bit, little-endian, data-type-policy=OVERRIDE, i-signal-type=PRIMITIVE, init-value=1022, base-type=BT_BMC_Temperatur_niedrigste, invalid-value=Invalid_BMC_Temperatur_niedrigste_XIX_BMC_HV_07_XIX_HCP5_CANFD01:1023, compu {phys=raw*0.125-40 for raw 0..1021, 1022=Cx3fe_Init (CM_BMC_Temperatur_niedrigste_Cx3fe_Init), 1023=Cx3ff_Fehler (CM_BMC_Temperatur_niedrigste_Cx3ff_Fehler); unit Unit_DegreCelsi}, range phys -40..87.625 Unit_DegreCelsi, raw 0..1023, unit=Unit_DegreCelsi, transfer-property=PENDING  # aktuell niedrigsteTemperatur in der Batterie
  pdu BMC_HV_08_XIX_HCP5_CANFD01: length=44, transmission-mode-true-timing=cyclic-timing={time-offset=0, time-period=1}, unused-bit-pattern=0
    signal BMC_IstTemperaturMin_Sensor_ID_XIX_BMC_HV_08_XIX_HCP5_CANFD01: start 12, 5 bit, little-endian, data-type-policy=OVERRIDE, i-signal-type=PRIMITIVE, init-value=31, base-type=BT_BMC_IstTemperaturMin_Sensor_ID, compu {phys=raw for raw 1..30, 31=Cx1f_Init (CM_BMC_IstTemperaturMin_Sensor_ID_Cx1f_Init); unit Unit_None}, range phys 1..30 Unit_None, raw 1..31, unit=Unit_None, transfer-property=PENDING  # RTM-Signal: Nummer (ID) des Sensors (innerhalb des Moduls) mit dem aktuell niedrigsten Temperaturmeßwert
    signal BMC_IstTemperaturMax_Sensor_ID_XIX_BMC_HV_08_XIX_HCP5_CANFD01: start 17, 5 bit, little-endian, data-type-policy=OVERRIDE, i-signal-type=PRIMITIVE, init-value=31, base-type=BT_BMC_IstTemperaturMax_Sensor_ID, compu {phys=raw for raw 1..30, 31=Cx1f_Init (CM_BMC_IstTemperaturMax_Sensor_ID_Cx1f_Init); unit Unit_None}, range phys 1..30 Unit_None, raw 1..31, unit=Unit_None, transfer-property=PENDING  # RTM-Signal: Nummer (ID) des Sensors (innerhalb des Moduls) mit dem aktuell höchsten Temperaturmeßwert
    signal BMC_RtmWarnUeberstrom_XIX_BMC_HV_08_XIX_HCP5_CANFD01: start 22, 3 bit, little-endian, data-type-policy=OVERRIDE, i-signal-type=PRIMITIVE, init-value=0, base-type=BT_BMC_RtmWarnUeberstrom, compu {0=Cx0_kein_Fehler (CM_BMC_RtmWarnUeberstrom_Cx0_kein_Fehler), 1=Cx1_Fehler_Stufe_1 (CM_BMC_RtmWarnUeberstrom_Cx1_Fehler_Stufe_1), 2=Cx2_Fehler_Stufe_2 (CM_BMC_RtmWarnUeberstrom_Cx2_Fehler_Stufe_2), 3=Cx3_Fehler_Stufe_3 (CM_BMC_RtmWarnUeberstrom_Cx3_Fehler_Stufe_3), 4=Cx4_reserviert (CM_BMC_RtmWarnUeberstrom_Cx4_reserviert), 5=Cx5_reserviert (CM_BMC_RtmWarnUeberstrom_Cx5_reserviert), 6=Cx6_reserviert (CM_BMC_RtmWarnUeberstrom_Cx6_reserviert), 7=Cx7_reserviert (CM_BMC_RtmWarnUeberstrom_Cx7_reserviert)}, range raw 0..7, transfer-property=PENDING  # Real Time Monitor Over-current of overall current of traction battery
    signal BMC_RtmWarnPackKommunikation_XIX_BMC_HV_08_XIX_HCP5_CANFD01: start 25, 3 bit, little-endian, data-type-policy=OVERRIDE, i-signal-type=PRIMITIVE, init-value=0, base-type=BT_BMC_RtmWarnPackKommunikation, compu {0=Cx0_kein_Fehler (CM_BMC_RtmWarnPackKommunikation_Cx0_kein_Fehler), 1=Cx1_Fehler_Stufe_1 (CM_BMC_RtmWarnPackKommunikation_Cx1_Fehler_Stufe_1), 2=Cx2_Fehler_Stufe_2 (CM_BMC_RtmWarnPackKommunikation_Cx2_Fehler_Stufe_2), 3=Cx3_Fehler_Stufe_3 (CM_BMC_RtmWarnPackKommunikation_Cx3_Fehler_Stufe_3), 4=Cx4_reserviert (CM_BMC_RtmWarnPackKommunikation_Cx4_reserviert), 5=Cx5_reserviert (CM_BMC_RtmWarnPackKommunikation_Cx5_reserviert), 6=Cx6_reserviert (CM_BMC_RtmWarnPackKommunikation_Cx6_reserviert), 7=Cx7_reserviert (CM_BMC_RtmWarnPackKommunikation_Cx7_reserviert)}, range raw 0..7, transfer-property=PENDING  # Real Time Monitor Traction battery CAN communication fault
    signal BMC_RtmWarnPackUeberladen_XIX_BMC_HV_08_XIX_HCP5_CANFD01: start 28, 3 bit, little-endian, data-type-policy=OVERRIDE, i-signal-type=PRIMITIVE, init-value=0, base-type=BT_BMC_RtmWarnPackUeberladen, compu {0=Cx0_kein_Fehler (CM_BMC_RtmWarnPackUeberladen_Cx0_kein_Fehler), 1=Cx1_Fehler_Stufe_1 (CM_BMC_RtmWarnPackUeberladen_Cx1_Fehler_Stufe_1), 2=Cx2_Fehler_Stufe_2 (CM_BMC_RtmWarnPackUeberladen_Cx2_Fehler_Stufe_2), 3=Cx3_Fehler_Stufe_3 (CM_BMC_RtmWarnPackUeberladen_Cx3_Fehler_Stufe_3), 4=Cx4_reserviert (CM_BMC_RtmWarnPackUeberladen_Cx4_reserviert), 5=Cx5_reserviert (CM_BMC_RtmWarnPackUeberladen_Cx5_reserviert), 6=Cx6_reserviert (CM_BMC_RtmWarnPackUeberladen_Cx6_reserviert), 7=Cx7_reserviert (CM_BMC_RtmWarnPackUeberladen_Cx7_reserviert)}, range raw 0..7, transfer-property=PENDING  # RTM Signal Energy-storage over-charging warning
    signal BMC_RtmWarnSocHoch_XIX_BMC_HV_08_XIX_HCP5_CANFD01: start 31, 3 bit, little-endian, data-type-policy=OVERRIDE, i-signal-type=PRIMITIVE, init-value=0, base-type=BT_BMC_RtmWarnSocHoch, compu {0=Cx0_kein_Fehler (CM_BMC_RtmWarnSocHoch_Cx0_kein_Fehler), 1=Cx1_Fehler_Stufe_1 (CM_BMC_RtmWarnSocHoch_Cx1_Fehler_Stufe_1), 2=Cx2_Fehler_Stufe_2 (CM_BMC_RtmWarnSocHoch_Cx2_Fehler_Stufe_2), 3=Cx3_Fehler_Stufe_3 (CM_BMC_RtmWarnSocHoch_Cx3_Fehler_Stufe_3), 4=Cx4_reserviert (CM_BMC_RtmWarnSocHoch_Cx4_reserviert), 5=Cx5_reserviert (CM_BMC_RtmWarnSocHoch_Cx5_reserviert), 6=Cx6_reserviert (CM_BMC_RtmWarnSocHoch_Cx6_reserviert), 7=Cx7_reserviert (CM_BMC_RtmWarnSocHoch_Cx7_reserviert)}, range raw 0..7, transfer-property=PENDING  # RTM Signal Excessively-high SOC warning
    signal BMC_RtmWarnSocNiedrig_XIX_BMC_HV_08_XIX_HCP5_CANFD01: start 34, 3 bit, little-endian, data-type-policy=OVERRIDE, i-signal-type=PRIMITIVE, init-value=0, base-type=BT_BMC_RtmWarnSocNiedrig, compu {0=Cx0_kein_Fehler (CM_BMC_RtmWarnSocNiedrig_Cx0_kein_Fehler), 1=Cx1_Fehler_Stufe_1 (CM_BMC_RtmWarnSocNiedrig_Cx1_Fehler_Stufe_1), 2=Cx2_Fehler_Stufe_2 (CM_BMC_RtmWarnSocNiedrig_Cx2_Fehler_Stufe_2), 3=Cx3_Fehler_Stufe_3 (CM_BMC_RtmWarnSocNiedrig_Cx3_Fehler_Stufe_3), 4=Cx4_reserviert (CM_BMC_RtmWarnSocNiedrig_Cx4_reserviert), 5=Cx5_reserviert (CM_BMC_RtmWarnSocNiedrig_Cx5_reserviert), 6=Cx6_reserviert (CM_BMC_RtmWarnSocNiedrig_Cx6_reserviert), 7=Cx7_reserviert (CM_BMC_RtmWarnSocNiedrig_Cx7_reserviert)}, range raw 0..7, transfer-property=PENDING  # RTM Signal Low SOC warning
    signal BMC_RtmWarnSocSprung_XIX_BMC_HV_08_XIX_HCP5_CANFD01: start 37, 3 bit, little-endian, data-type-policy=OVERRIDE, i-signal-type=PRIMITIVE, init-value=0, base-type=BT_BMC_RtmWarnSocSprung, compu {0=Cx0_kein_Fehler (CM_BMC_RtmWarnSocSprung_Cx0_kein_Fehler), 1=Cx1_Fehler_Stufe_1 (CM_BMC_RtmWarnSocSprung_Cx1_Fehler_Stufe_1), 2=Cx2_Fehler_Stufe_2 (CM_BMC_RtmWarnSocSprung_Cx2_Fehler_Stufe_2), 3=Cx3_Fehler_Stufe_3 (CM_BMC_RtmWarnSocSprung_Cx3_Fehler_Stufe_3), 4=Cx4_reserviert (CM_BMC_RtmWarnSocSprung_Cx4_reserviert), 5=Cx5_reserviert (CM_BMC_RtmWarnSocSprung_Cx5_reserviert), 6=Cx6_reserviert (CM_BMC_RtmWarnSocSprung_Cx6_reserviert), 7=Cx7_reserviert (CM_BMC_RtmWarnSocSprung_Cx7_reserviert)}, range raw 0..7, transfer-property=PENDING  # RTM Signal SOC jump warning
    signal BMC_RtmWarnTZelleDiff_XIX_BMC_HV_08_XIX_HCP5_CANFD01: start 40, 3 bit, little-endian, data-type-policy=OVERRIDE, i-signal-type=PRIMITIVE, init-value=0, base-type=BT_BMC_RtmWarnTZelleDiff, compu {0=Cx0_kein_Fehler (CM_BMC_RtmWarnTZelleDiff_Cx0_kein_Fehler), 1=Cx1_Fehler_Stufe_1 (CM_BMC_RtmWarnTZelleDiff_Cx1_Fehler_Stufe_1), 2=Cx2_Fehler_Stufe_2 (CM_BMC_RtmWarnTZelleDiff_Cx2_Fehler_Stufe_2), 3=Cx3_Fehler_Stufe_3 (CM_BMC_RtmWarnTZelleDiff_Cx3_Fehler_Stufe_3), 4=Cx4_reserviert (CM_BMC_RtmWarnTZelleDiff_Cx4_reserviert), 5=Cx5_reserviert (CM_BMC_RtmWarnTZelleDiff_Cx5_reserviert), 6=Cx6_reserviert (CM_BMC_RtmWarnTZelleDiff_Cx6_reserviert), 7=Cx7_reserviert (CM_BMC_RtmWarnTZelleDiff_Cx7_reserviert)}, range raw 0..7, transfer-property=PENDING  # RTM Signal Temperature difference warning
    signal BMC_RtmWarnTZelleMax_XIX_BMC_HV_08_XIX_HCP5_CANFD01: start 43, 3 bit, little-endian, data-type-policy=OVERRIDE, i-signal-type=PRIMITIVE, init-value=0, base-type=BT_BMC_RtmWarnTZelleMax, compu {0=Cx0_kein_Fehler (CM_BMC_RtmWarnTZelleMax_Cx0_kein_Fehler), 1=Cx1_Fehler_Stufe_1 (CM_BMC_RtmWarnTZelleMax_Cx1_Fehler_Stufe_1), 2=Cx2_Fehler_Stufe_2 (CM_BMC_RtmWarnTZelleMax_Cx2_Fehler_Stufe_2), 3=Cx3_Fehler_Stufe_3 (CM_BMC_RtmWarnTZelleMax_Cx3_Fehler_Stufe_3), 4=Cx4_reserviert (CM_BMC_RtmWarnTZelleMax_Cx4_reserviert), 5=Cx5_reserviert (CM_BMC_RtmWarnTZelleMax_Cx5_reserviert), 6=Cx6_reserviert (CM_BMC_RtmWarnTZelleMax_Cx6_reserviert), 7=Cx7_reserviert (CM_BMC_RtmWarnTZelleMax_Cx7_reserviert)}, range raw 0..7, transfer-property=PENDING  # RTM Signal Max_temperature_cell_Warning
    signal BMC_RtmWarnTZelleMin_XIX_BMC_HV_08_XIX_HCP5_CANFD01: start 46, 3 bit, little-endian, data-type-policy=OVERRIDE, i-signal-type=PRIMITIVE, init-value=0, base-type=BT_BMC_RtmWarnTZelleMin, compu {0=Cx0_kein_Fehler (CM_BMC_RtmWarnTZelleMin_Cx0_kein_Fehler), 1=Cx1_Fehler_Stufe_1 (CM_BMC_RtmWarnTZelleMin_Cx1_Fehler_Stufe_1), 2=Cx2_Fehler_Stufe_2 (CM_BMC_RtmWarnTZelleMin_Cx2_Fehler_Stufe_2), 3=Cx3_Fehler_Stufe_3 (CM_BMC_RtmWarnTZelleMin_Cx3_Fehler_Stufe_3), 4=Cx4_reserviert (CM_BMC_RtmWarnTZelleMin_Cx4_reserviert), 5=Cx5_reserviert (CM_BMC_RtmWarnTZelleMin_Cx5_reserviert), 6=Cx6_reserviert (CM_BMC_RtmWarnTZelleMin_Cx6_reserviert), 7=Cx7_reserviert (CM_BMC_RtmWarnTZelleMin_Cx7_reserviert)}, range raw 0..7, transfer-property=PENDING  # RTM Signal Min_temperature_cell_Warning
    signal BMC_RtmWarnUPackMax_XIX_BMC_HV_08_XIX_HCP5_CANFD01: start 49, 3 bit, little-endian, data-type-policy=OVERRIDE, i-signal-type=PRIMITIVE, init-value=0, base-type=BT_BMC_RtmWarnUPackMax, compu {0=Cx0_kein_Fehler (CM_BMC_RtmWarnUPackMax_Cx0_kein_Fehler), 1=Cx1_Fehler_Stufe_1 (CM_BMC_RtmWarnUPackMax_Cx1_Fehler_Stufe_1), 2=Cx2_Fehler_Stufe_2 (CM_BMC_RtmWarnUPackMax_Cx2_Fehler_Stufe_2), 3=Cx3_Fehler_Stufe_3 (CM_BMC_RtmWarnUPackMax_Cx3_Fehler_Stufe_3), 4=Cx4_reserviert (CM_BMC_RtmWarnUPackMax_Cx4_reserviert), 5=Cx5_reserviert (CM_BMC_RtmWarnUPackMax_Cx5_reserviert), 6=Cx6_reserviert (CM_BMC_RtmWarnUPackMax_Cx6_reserviert), 7=Cx7_reserviert (CM_BMC_RtmWarnUPackMax_Cx7_reserviert)}, range raw 0..7, transfer-property=PENDING  # RTM Signal Max_Voltage_of_battery_Warning
    signal BMC_RtmWarnUPackMin_XIX_BMC_HV_08_XIX_HCP5_CANFD01: start 52, 3 bit, little-endian, data-type-policy=OVERRIDE, i-signal-type=PRIMITIVE, init-value=0, base-type=BT_BMC_RtmWarnUPackMin, compu {0=Cx0_kein_Fehler (CM_BMC_RtmWarnUPackMin_Cx0_kein_Fehler), 1=Cx1_Fehler_Stufe_1 (CM_BMC_RtmWarnUPackMin_Cx1_Fehler_Stufe_1), 2=Cx2_Fehler_Stufe_2 (CM_BMC_RtmWarnUPackMin_Cx2_Fehler_Stufe_2), 3=Cx3_Fehler_Stufe_3 (CM_BMC_RtmWarnUPackMin_Cx3_Fehler_Stufe_3), 4=Cx4_reserviert (CM_BMC_RtmWarnUPackMin_Cx4_reserviert), 5=Cx5_reserviert (CM_BMC_RtmWarnUPackMin_Cx5_reserviert), 6=Cx6_reserviert (CM_BMC_RtmWarnUPackMin_Cx6_reserviert), 7=Cx7_reserviert (CM_BMC_RtmWarnUPackMin_Cx7_reserviert)}, range raw 0..7, transfer-property=PENDING  # RTM Signal Min_Voltage_of_battery_Warning
    signal BMC_RtmWarnUZelleMax_XIX_BMC_HV_08_XIX_HCP5_CANFD01: start 55, 3 bit, little-endian, data-type-policy=OVERRIDE, i-signal-type=PRIMITIVE, init-value=0, base-type=BT_BMC_RtmWarnUZelleMax, compu {0=Cx0_kein_Fehler (CM_BMC_RtmWarnUZelleMax_Cx0_kein_Fehler), 1=Cx1_Fehler_Stufe_1 (CM_BMC_RtmWarnUZelleMax_Cx1_Fehler_Stufe_1), 2=Cx2_Fehler_Stufe_2 (CM_BMC_RtmWarnUZelleMax_Cx2_Fehler_Stufe_2), 3=Cx3_Fehler_Stufe_3 (CM_BMC_RtmWarnUZelleMax_Cx3_Fehler_Stufe_3), 4=Cx4_reserviert (CM_BMC_RtmWarnUZelleMax_Cx4_reserviert), 5=Cx5_reserviert (CM_BMC_RtmWarnUZelleMax_Cx5_reserviert), 6=Cx6_reserviert (CM_BMC_RtmWarnUZelleMax_Cx6_reserviert), 7=Cx7_reserviert (CM_BMC_RtmWarnUZelleMax_Cx7_reserviert)}, range raw 0..7, transfer-property=PENDING  # RTM Signal Max_voltage_cell_Warning
    signal BMC_RtmWarnUZelleMin_XIX_BMC_HV_08_XIX_HCP5_CANFD01: start 58, 3 bit, little-endian, data-type-policy=OVERRIDE, i-signal-type=PRIMITIVE, init-value=0, base-type=BT_BMC_RtmWarnUZelleMin, compu {0=Cx0_kein_Fehler (CM_BMC_RtmWarnUZelleMin_Cx0_kein_Fehler), 1=Cx1_Fehler_Stufe_1 (CM_BMC_RtmWarnUZelleMin_Cx1_Fehler_Stufe_1), 2=Cx2_Fehler_Stufe_2 (CM_BMC_RtmWarnUZelleMin_Cx2_Fehler_Stufe_2), 3=Cx3_Fehler_Stufe_3 (CM_BMC_RtmWarnUZelleMin_Cx3_Fehler_Stufe_3), 4=Cx4_reserviert (CM_BMC_RtmWarnUZelleMin_Cx4_reserviert), 5=Cx5_reserviert (CM_BMC_RtmWarnUZelleMin_Cx5_reserviert), 6=Cx6_reserviert (CM_BMC_RtmWarnUZelleMin_Cx6_reserviert), 7=Cx7_reserviert (CM_BMC_RtmWarnUZelleMin_Cx7_reserviert)}, range raw 0..7, transfer-property=PENDING  # RTM Signal Min_voltage_cell_Warning
    signal BMC_RtmWarnZelleZustand_XIX_BMC_HV_08_XIX_HCP5_CANFD01: start 61, 3 bit, little-endian, data-type-policy=OVERRIDE, i-signal-type=PRIMITIVE, init-value=0, base-type=BT_BMC_RtmWarnZelleZustand, compu {0=Cx0_kein_Fehler (CM_BMC_RtmWarnZelleZustand_Cx0_kein_Fehler), 1=Cx1_Fehler_Stufe_1 (CM_BMC_RtmWarnZelleZustand_Cx1_Fehler_Stufe_1), 2=Cx2_Fehler_Stufe_2 (CM_BMC_RtmWarnZelleZustand_Cx2_Fehler_Stufe_2), 3=Cx3_Fehler_Stufe_3 (CM_BMC_RtmWarnZelleZustand_Cx3_Fehler_Stufe_3), 4=Cx4_reserviert (CM_BMC_RtmWarnZelleZustand_Cx4_reserviert), 5=Cx5_reserviert (CM_BMC_RtmWarnZelleZustand_Cx5_reserviert), 6=Cx6_reserviert (CM_BMC_RtmWarnZelleZustand_Cx6_reserviert), 7=Cx7_reserviert (CM_BMC_RtmWarnZelleZustand_Cx7_reserviert)}, range raw 0..7, transfer-property=PENDING  # RTM Signal Cell poor-consistency warning
    signal BMC_Pack_SN_01_XIX_BMC_HV_08_XIX_HCP5_CANFD01: start 64, 8 bit, little-endian, data-type-policy=OVERRIDE, i-signal-type=PRIMITIVE, init-value=255, base-type=BT_BMC_Pack_SN_01, compu {255=Cxff_Init (CM_BMC_Pack_SN_01_Cxff_Init)}, range raw 255, transfer-property=PENDING  # Seriennummer der HV Batterie, Byte 1, ASCII Codierung
    signal BMC_Pack_SN_02_XIX_BMC_HV_08_XIX_HCP5_CANFD01: start 72, 8 bit, little-endian, data-type-policy=OVERRIDE, i-signal-type=PRIMITIVE, init-value=255, base-type=BT_BMC_Pack_SN_02, compu {255=Cxff_Init (CM_BMC_Pack_SN_02_Cxff_Init)}, range raw 255, transfer-property=PENDING  # Seriennummer der HV Batterie, Byte 2, ASCII Codierung
    signal BMC_Pack_SN_03_XIX_BMC_HV_08_XIX_HCP5_CANFD01: start 80, 8 bit, little-endian, data-type-policy=OVERRIDE, i-signal-type=PRIMITIVE, init-value=255, base-type=BT_BMC_Pack_SN_03, compu {255=Cxff_Init (CM_BMC_Pack_SN_03_Cxff_Init)}, range raw 255, transfer-property=PENDING  # Seriennummer der HV Batterie, Byte 3, ASCII Codierung
    signal BMC_Pack_SN_04_XIX_BMC_HV_08_XIX_HCP5_CANFD01: start 88, 8 bit, little-endian, data-type-policy=OVERRIDE, i-signal-type=PRIMITIVE, init-value=255, base-type=BT_BMC_Pack_SN_04, compu {255=Cxff_Init (CM_BMC_Pack_SN_04_Cxff_Init)}, range raw 255, transfer-property=PENDING  # Seriennummer der HV Batterie, Byte 4, ASCII Codierung
    signal BMC_Pack_SN_05_XIX_BMC_HV_08_XIX_HCP5_CANFD01: start 96, 8 bit, little-endian, data-type-policy=OVERRIDE, i-signal-type=PRIMITIVE, init-value=255, base-type=BT_BMC_Pack_SN_05, compu {255=Cxff_Init (CM_BMC_Pack_SN_05_Cxff_Init)}, range raw 255, transfer-property=PENDING  # Seriennummer der HV Batterie, Byte 5, ASCII Codierung
    signal BMC_Pack_SN_06_XIX_BMC_HV_08_XIX_HCP5_CANFD01: start 104, 8 bit, little-endian, data-type-policy=OVERRIDE, i-signal-type=PRIMITIVE, init-value=255, base-type=BT_BMC_Pack_SN_06, compu {255=Cxff_Init (CM_BMC_Pack_SN_06_Cxff_Init)}, range raw 255, transfer-property=PENDING  # Seriennummer der HV Batterie, Byte 6, ASCII Codierung
    signal BMC_Pack_SN_07_XIX_BMC_HV_08_XIX_HCP5_CANFD01: start 112, 8 bit, little-endian, data-type-policy=OVERRIDE, i-signal-type=PRIMITIVE, init-value=255, base-type=BT_BMC_Pack_SN_07, compu {255=Cxff_Init (CM_BMC_Pack_SN_07_Cxff_Init)}, range raw 255, transfer-property=PENDING  # Seriennummer der HV Batterie, Byte 7, ASCII Codierung
    signal BMC_Pack_SN_08_XIX_BMC_HV_08_XIX_HCP5_CANFD01: start 120, 8 bit, little-endian, data-type-policy=OVERRIDE, i-signal-type=PRIMITIVE, init-value=255, base-type=BT_BMC_Pack_SN_08, compu {255=Cxff_Init (CM_BMC_Pack_SN_08_Cxff_Init)}, range raw 255, transfer-property=PENDING  # Seriennummer der HV Batterie, Byte 8, ASCII Codierung
    signal BMC_Pack_SN_09_XIX_BMC_HV_08_XIX_HCP5_CANFD01: start 128, 8 bit, little-endian, data-type-policy=OVERRIDE, i-signal-type=PRIMITIVE, init-value=255, base-type=BT_BMC_Pack_SN_09, compu {255=Cxff_Init (CM_BMC_Pack_SN_09_Cxff_Init)}, range raw 255, transfer-property=PENDING  # Seriennummer der HV Batterie, Byte 9, ASCII Codierung
    signal BMC_Pack_SN_10_XIX_BMC_HV_08_XIX_HCP5_CANFD01: start 136, 8 bit, little-endian, data-type-policy=OVERRIDE, i-signal-type=PRIMITIVE, init-value=255, base-type=BT_BMC_Pack_SN_10, compu {255=Cxff_Init (CM_BMC_Pack_SN_10_Cxff_Init)}, range raw 255, transfer-property=PENDING  # Seriennummer der HV Batterie, Byte 10, ASCII Codierung
    signal BMC_Pack_SN_11_XIX_BMC_HV_08_XIX_HCP5_CANFD01: start 144, 8 bit, little-endian, data-type-policy=OVERRIDE, i-signal-type=PRIMITIVE, init-value=255, base-type=BT_BMC_Pack_SN_11, compu {255=Cxff_Init (CM_BMC_Pack_SN_11_Cxff_Init)}, range raw 255, transfer-property=PENDING  # Seriennummer der HV Batterie, Byte 11, ASCII Codierung
    signal BMC_Pack_SN_12_XIX_BMC_HV_08_XIX_HCP5_CANFD01: start 152, 8 bit, little-endian, data-type-policy=OVERRIDE, i-signal-type=PRIMITIVE, init-value=255, base-type=BT_BMC_Pack_SN_12, compu {255=Cxff_Init (CM_BMC_Pack_SN_12_Cxff_Init)}, range raw 255, transfer-property=PENDING  # Seriennummer der HV Batterie, Byte 12, ASCII Codierung
    signal BMC_Pack_SN_13_XIX_BMC_HV_08_XIX_HCP5_CANFD01: start 160, 8 bit, little-endian, data-type-policy=OVERRIDE, i-signal-type=PRIMITIVE, init-value=255, base-type=BT_BMC_Pack_SN_13, compu {255=Cxff_Init (CM_BMC_Pack_SN_13_Cxff_Init)}, range raw 255, transfer-property=PENDING  # Seriennummer der HV Batterie, Byte 13, ASCII Codierung
    signal BMC_Pack_SN_14_XIX_BMC_HV_08_XIX_HCP5_CANFD01: start 168, 8 bit, little-endian, data-type-policy=OVERRIDE, i-signal-type=PRIMITIVE, init-value=255, base-type=BT_BMC_Pack_SN_14, compu {255=Cxff_Init (CM_BMC_Pack_SN_14_Cxff_Init)}, range raw 255, transfer-property=PENDING  # Seriennummer der HV Batterie, Byte 14, ASCII Codierung
    signal BMC_Pack_SN_15_XIX_BMC_HV_08_XIX_HCP5_CANFD01: start 176, 8 bit, little-endian, data-type-policy=OVERRIDE, i-signal-type=PRIMITIVE, init-value=255, base-type=BT_BMC_Pack_SN_15, compu {255=Cxff_Init (CM_BMC_Pack_SN_15_Cxff_Init)}, range raw 255, transfer-property=PENDING  # Seriennummer der HV Batterie, Byte 15, ASCII Codierung
    signal BMC_Pack_SN_16_XIX_BMC_HV_08_XIX_HCP5_CANFD01: start 184, 8 bit, little-endian, data-type-policy=OVERRIDE, i-signal-type=PRIMITIVE, init-value=255, base-type=BT_BMC_Pack_SN_16, compu {255=Cxff_Init (CM_BMC_Pack_SN_16_Cxff_Init)}, range raw 255, transfer-property=PENDING  # Seriennummer der HV Batterie, Byte 16, ASCII Codierung
    signal BMC_Pack_SN_17_XIX_BMC_HV_08_XIX_HCP5_CANFD01: start 192, 8 bit, little-endian, data-type-policy=OVERRIDE, i-signal-type=PRIMITIVE, init-value=255, base-type=BT_BMC_Pack_SN_17, compu {255=Cxff_Init (CM_BMC_Pack_SN_17_Cxff_Init)}, range raw 255, transfer-property=PENDING  # Seriennummer der HV Batterie, Byte 17, ASCII Codierung
    signal BMC_Pack_SN_18_XIX_BMC_HV_08_XIX_HCP5_CANFD01: start 200, 8 bit, little-endian, data-type-policy=OVERRIDE, i-signal-type=PRIMITIVE, init-value=255, base-type=BT_BMC_Pack_SN_18, compu {255=Cxff_Init (CM_BMC_Pack_SN_18_Cxff_Init)}, range raw 255, transfer-property=PENDING  # Seriennummer der HV Batterie, Byte 18, ASCII Codierung
    signal BMC_Pack_SN_19_XIX_BMC_HV_08_XIX_HCP5_CANFD01: start 208, 8 bit, little-endian, data-type-policy=OVERRIDE, i-signal-type=PRIMITIVE, init-value=255, base-type=BT_BMC_Pack_SN_19, compu {255=Cxff_Init (CM_BMC_Pack_SN_19_Cxff_Init)}, range raw 255, transfer-property=PENDING  # Seriennummer der HV Batterie, Byte 19, ASCII Codierung
    signal BMC_Pack_SN_20_XIX_BMC_HV_08_XIX_HCP5_CANFD01: start 216, 8 bit, little-endian, data-type-policy=OVERRIDE, i-signal-type=PRIMITIVE, init-value=255, base-type=BT_BMC_Pack_SN_20, compu {255=Cxff_Init (CM_BMC_Pack_SN_20_Cxff_Init)}, range raw 255, transfer-property=PENDING  # Seriennummer der HV Batterie, Byte 20, ASCII Codierung
    signal BMC_Pack_SN_21_XIX_BMC_HV_08_XIX_HCP5_CANFD01: start 224, 8 bit, little-endian, data-type-policy=OVERRIDE, i-signal-type=PRIMITIVE, init-value=255, base-type=BT_BMC_Pack_SN_21, compu {255=Cxff_Init (CM_BMC_Pack_SN_21_Cxff_Init)}, range raw 255, transfer-property=PENDING  # Seriennummer der HV Batterie, Byte 21, ASCII Codierung
    signal BMC_Pack_SN_22_XIX_BMC_HV_08_XIX_HCP5_CANFD01: start 232, 8 bit, little-endian, data-type-policy=OVERRIDE, i-signal-type=PRIMITIVE, init-value=255, base-type=BT_BMC_Pack_SN_22, compu {255=Cxff_Init (CM_BMC_Pack_SN_22_Cxff_Init)}, range raw 255, transfer-property=PENDING  # Seriennummer der HV Batterie, Byte 22, ASCII Codierung
    signal BMC_Pack_SN_23_XIX_BMC_HV_08_XIX_HCP5_CANFD01: start 240, 8 bit, little-endian, data-type-policy=OVERRIDE, i-signal-type=PRIMITIVE, init-value=255, base-type=BT_BMC_Pack_SN_23, compu {255=Cxff_Init (CM_BMC_Pack_SN_23_Cxff_Init)}, range raw 255, transfer-property=PENDING  # Seriennummer der HV Batterie, Byte 23, ASCII Codierung
    signal BMC_Pack_SN_24_XIX_BMC_HV_08_XIX_HCP5_CANFD01: start 248, 8 bit, little-endian, data-type-policy=OVERRIDE, i-signal-type=PRIMITIVE, init-value=255, base-type=BT_BMC_Pack_SN_24, compu {255=Cxff_Init (CM_BMC_Pack_SN_24_Cxff_Init)}, range raw 255, transfer-property=PENDING  # Seriennummer der HV Batterie, Byte 24, ASCII Codierung
    signal BMC_Pack_SN_25_XIX_BMC_HV_08_XIX_HCP5_CANFD01: start 256, 8 bit, little-endian, data-type-policy=OVERRIDE, i-signal-type=PRIMITIVE, init-value=255, base-type=BT_BMC_Pack_SN_25, compu {255=Cxff_Init (CM_BMC_Pack_SN_25_Cxff_Init)}, range raw 255, transfer-property=PENDING  # Seriennummer der HV Batterie, Byte 25, ASCII Codierung
    signal BMC_Pack_SN_26_XIX_BMC_HV_08_XIX_HCP5_CANFD01: start 264, 8 bit, little-endian, data-type-policy=OVERRIDE, i-signal-type=PRIMITIVE, init-value=255, base-type=BT_BMC_Pack_SN_26, compu {255=Cxff_Init (CM_BMC_Pack_SN_26_Cxff_Init)}, range raw 255, transfer-property=PENDING  # Seriennummer der HV Batterie, Byte 26, ASCII Codierung
    signal BMC_IstTemperaturMax_Modul_ID_XIX_BMC_HV_08_XIX_HCP5_CANFD01: start 272, 8 bit, little-endian, data-type-policy=OVERRIDE, i-signal-type=PRIMITIVE, init-value=255, base-type=BT_BMC_IstTemperaturMax_Modul_ID, compu {phys=raw for raw 1..254, 255=Cxff_Init (CM_BMC_IstTemperaturMax_Modul_ID_Cxff_Init); unit Unit_None}, range phys 1..254 Unit_None, raw 1..255, unit=Unit_None, transfer-property=PENDING  # RTM-Signal: Nummer (ID) des Moduls mit dem aktuell höchsten Temperaturmeßwert
    signal BMC_IstTemperaturMin_Modul_ID_XIX_BMC_HV_08_XIX_HCP5_CANFD01: start 280, 8 bit, little-endian, data-type-policy=OVERRIDE, i-signal-type=PRIMITIVE, init-value=255, base-type=BT_BMC_IstTemperaturMin_Modul_ID, compu {phys=raw for raw 1..254, 255=Cxff_Init (CM_BMC_IstTemperaturMin_Modul_ID_Cxff_Init); unit Unit_None}, range phys 1..254 Unit_None, raw 1..255, unit=Unit_None, transfer-property=PENDING  # RTM-Signal: Nummer (ID) des Moduls mit dem aktuell niedrigsten Temperaturmeßwert
    signal BMC_IstZellSpannungMin_Modul_ID_XIX_BMC_HV_08_XIX_HCP5_CANFD01: start 288, 8 bit, little-endian, data-type-policy=OVERRIDE, i-signal-type=PRIMITIVE, init-value=255, base-type=BT_BMC_IstZellSpannungMin_Modul_ID, compu {phys=raw for raw 1..254, 255=Cxff_Init (CM_BMC_IstZellSpannungMin_Modul_ID_Cxff_Init); unit Unit_None}, range phys 1..254 Unit_None, raw 1..255, unit=Unit_None, transfer-property=PENDING  # RTM-Signal: Nummer (ID) des Moduls mit der aktuell niedrigsten Zellspannung
    signal BMC_IstZellSpannungMax_Modul_ID_XIX_BMC_HV_08_XIX_HCP5_CANFD01: start 296, 8 bit, little-endian, data-type-policy=OVERRIDE, i-signal-type=PRIMITIVE, init-value=255, base-type=BT_BMC_IstZellSpannungMax_Modul_ID, compu {phys=raw for raw 1..254, 255=Cxff_Init (CM_BMC_IstZellSpannungMax_Modul_ID_Cxff_Init); unit Unit_None}, range phys 1..254 Unit_None, raw 1..255, unit=Unit_None, transfer-property=PENDING  # RTM-Signal: Nummer (ID) des Moduls mit der aktuell höchsten Zellspannung
    signal BMC_IstZellSpannungMin_Zell_ID_XIX_BMC_HV_08_XIX_HCP5_CANFD01: start 304, 8 bit, little-endian, data-type-policy=OVERRIDE, i-signal-type=PRIMITIVE, init-value=255, base-type=BT_BMC_IstZellSpannungMin_Zell_ID, compu {phys=raw for raw 1..254, 255=Cxff_Init (CM_BMC_IstZellSpannungMin_Zell_ID_Cxff_Init); unit Unit_None}, range phys 1..254 Unit_None, raw 1..255, unit=Unit_None, transfer-property=PENDING  # RTM-Signal: Nummer (ID) der Zelle (innerhalb des Moduls) mit der aktuell niedrigsten Zellspannung
    signal BMC_IstZellSpannungMax_Zell_ID_XIX_BMC_HV_08_XIX_HCP5_CANFD01: start 312, 8 bit, little-endian, data-type-policy=OVERRIDE, i-signal-type=PRIMITIVE, init-value=255, base-type=BT_BMC_IstZellSpannungMax_Zell_ID, compu {phys=raw for raw 1..254, 255=Cxff_Init (CM_BMC_IstZellSpannungMax_Zell_ID_Cxff_Init); unit Unit_None}, range phys 1..254 Unit_None, raw 1..255, unit=Unit_None, transfer-property=PENDING  # RTM-Signal: Nummer (ID) der Zelle (innerhalb des Moduls) mit der aktuell höchsten Zellspannung
    signal BMC_RtmWarnBattUnautorisiert_XIX_BMC_HV_08_XIX_HCP5_CANFD01: start 320, 3 bit, little-endian, data-type-policy=OVERRIDE, i-signal-type=PRIMITIVE, init-value=0, base-type=BT_BMC_RtmWarnBattUnautorisiert, compu {0=Cx0_kein_Fehler (CM_BMC_RtmWarnBattUnautorisiert_Cx0_kein_Fehler), 1=Cx1_Fehler_Stufe_1 (CM_BMC_RtmWarnBattUnautorisiert_Cx1_Fehler_Stufe_1), 2=Cx2_Fehler_Stufe_2 (CM_BMC_RtmWarnBattUnautorisiert_Cx2_Fehler_Stufe_2), 3=Cx3_Fehler_Stufe_3 (CM_BMC_RtmWarnBattUnautorisiert_Cx3_Fehler_Stufe_3), 4=Cx4_reserviert (CM_BMC_RtmWarnBattUnautorisiert_Cx4_reserviert), 5=Cx5_reserviert (CM_BMC_RtmWarnBattUnautorisiert_Cx5_reserviert), 6=Cx6_reserviert (CM_BMC_RtmWarnBattUnautorisiert_Cx6_reserviert), 7=Cx7_reserviert (CM_BMC_RtmWarnBattUnautorisiert_Cx7_reserviert)}, range raw 0..7, transfer-property=PENDING  # RTM Signal battery unmatched warning
    signal BMC_ExtLadeleistung_XIX_BMC_HV_08_XIX_HCP5_CANFD01: start 328, 16 bit, little-endian, data-type-policy=OVERRIDE, i-signal-type=PRIMITIVE, init-value=65534, base-type=BT_BMC_ExtLadeleistung, invalid-value=Invalid_BMC_ExtLadeleistung_XIX_BMC_HV_08_XIX_HCP5_CANFD01:65535, compu {phys=raw*0.05 for raw 0..65533, 65534=Cxfffe_Init (CM_BMC_ExtLadeleistung_Cxfffe_Init), 65535=Cxffff_Fehler (CM_BMC_ExtLadeleistung_Cxffff_Fehler); unit Unit_KiloWatt}, range phys 0..3276.65 Unit_KiloWatt, raw 0..65535, unit=Unit_KiloWatt, transfer-property=PENDING  # Aktuell mögliche DC/AC- Ladeleistung
  pdu BMC_HV_09_XIX_HCP5_CANFD01: length=16, transmission-mode-true-timing=cyclic-timing={time-offset=0, time-period=0.1}, unused-bit-pattern=0
    signal BMC_Max_Entladestrom_02_XIX_BMC_HV_09_XIX_HCP5_CANFD01: start 12, 14 bit, little-endian, data-type-policy=OVERRIDE, i-signal-type=PRIMITIVE, init-value=16382, base-type=BT_BMC_Max_Entladestrom_02, invalid-value=Invalid_BMC_Max_Entladestrom_02_XIX_BMC_HV_09_XIX_HCP5_CANFD01:16383, compu {phys=raw*0.2 for raw 0..16250, 16382=Cx3ffe_Init (CM_BMC_Max_Entladestrom_02_Cx3ffe_Init), 16383=Cx3fff_Fehler (CM_BMC_Max_Entladestrom_02_Cx3fff_Fehler); unit Unit_Amper}, range phys 0..3250 Unit_Amper, raw 0..16383, unit=Unit_Amper, transfer-property=PENDING  # Zwingend einzuhaltender Grenzwert für den Entladestrom der Batterie. Verletzungen werden protokolliert.
    signal BMC_Max_Entladeleistung_02_XIX_BMC_HV_09_XIX_HCP5_CANFD01: start 26, 15 bit, little-endian, data-type-policy=OVERRIDE, i-signal-type=PRIMITIVE, init-value=32766, base-type=BT_BMC_Max_Entladeleistung_02, invalid-value=Invalid_BMC_Max_Entladeleistung_02_XIX_BMC_HV_09_XIX_HCP5_CANFD01:32767, compu {phys=raw*100 for raw 0..32500, 32766=Cx7ffe_Init (CM_BMC_Max_Entladeleistung_02_Cx7ffe_Init), 32767=Cx7fff_Fehler (CM_BMC_Max_Entladeleistung_02_Cx7fff_Fehler); unit Unit_Watt}, range phys 0..3250000 Unit_Watt, raw 0..32767, unit=Unit_Watt, transfer-property=PENDING  # Maximale Leistung, mit der die Batterie momentan belastet werden darf. Kurze Überschwinger aufgrund dynamischen Verhalten des Reglers sind nach Absprache möglich, aber hierbei muss unbedingt auch der maximale Entladestrom berücksichtigt werden.
    signal BMC_Max_Ladeleistung_02_XIX_BMC_HV_09_XIX_HCP5_CANFD01: start 41, 15 bit, little-endian, data-type-policy=OVERRIDE, i-signal-type=PRIMITIVE, init-value=32766, base-type=BT_BMC_Max_Ladeleistung_02, invalid-value=Invalid_BMC_Max_Ladeleistung_02_XIX_BMC_HV_09_XIX_HCP5_CANFD01:32767, compu {phys=raw*100 for raw 0..32500, 32766=Cx7ffe_Init (CM_BMC_Max_Ladeleistung_02_Cx7ffe_Init), 32767=Cx7fff_Fehler (CM_BMC_Max_Ladeleistung_02_Cx7fff_Fehler); unit Unit_Watt}, range phys 0..3250000 Unit_Watt, raw 0..32767, unit=Unit_Watt, transfer-property=PENDING  # Maximale Leistung, mit der die Batterie aktuell geladen werden darf.Kurze Überschwinger aufgrund dynamischen Verhalten des Reglers sind nach Absprache möglich, aber hierbei muss unbedingt auch der maximale Ladestrom berücksichtigt werden.
    signal BMC_Max_Ladestrom_02_XIX_BMC_HV_09_XIX_HCP5_CANFD01: start 56, 14 bit, little-endian, data-type-policy=OVERRIDE, i-signal-type=PRIMITIVE, init-value=16382, base-type=BT_BMC_Max_Ladestrom_02, invalid-value=Invalid_BMC_Max_Ladestrom_02_XIX_BMC_HV_09_XIX_HCP5_CANFD01:16383, compu {phys=raw*0.2 for raw 0..16250, 16382=Cx3ffe_Init (CM_BMC_Max_Ladestrom_02_Cx3ffe_Init), 16383=Cx3fff_Fehler (CM_BMC_Max_Ladestrom_02_Cx3fff_Fehler); unit Unit_Amper}, range phys 0..3250 Unit_Amper, raw 0..16383, unit=Unit_Amper, transfer-property=PENDING  # Zwingend einzuhaltender Grenzwert für den Ladestrom der Batterie.Verletzungen werden protokolliert.
    signal BMC_Dauer_Entladeleistung_02_XIX_BMC_HV_09_XIX_HCP5_CANFD01: start 70, 14 bit, little-endian, data-type-policy=OVERRIDE, i-signal-type=PRIMITIVE, init-value=16382, base-type=BT_BMC_Dauer_Entladeleistung_02, invalid-value=Invalid_BMC_Dauer_Entladeleistung_02_XIX_BMC_HV_09_XIX_HCP5_CANFD01:16383, compu {phys=raw*200 for raw 0..16250, 16382=Cx3ffe_Init (CM_BMC_Dauer_Entladeleistung_02_Cx3ffe_Init), 16383=Cx3fff_Fehler (CM_BMC_Dauer_Entladeleistung_02_Cx3fff_Fehler); unit Unit_Watt}, range phys 0..3250000 Unit_Watt, raw 0..16383, unit=Unit_Watt, transfer-property=PENDING  # ist die aktuelle Dauer-Leistungsfähigkeit der Batterie. Wenn dieser Wert überschritten wird, kann ein zeitliches Derating der maximalen Leistungsgrenzen stattfindet. Die Dauerleistung ändert sich mit Batterietemperatur und Ladezustand.
    signal BMC_Dauer_Ladeleistung_02_XIX_BMC_HV_09_XIX_HCP5_CANFD01: start 84, 14 bit, little-endian, data-type-policy=OVERRIDE, i-signal-type=PRIMITIVE, init-value=16382, base-type=BT_BMC_Dauer_Ladeleistung_02, invalid-value=Invalid_BMC_Dauer_Ladeleistung_02_XIX_BMC_HV_09_XIX_HCP5_CANFD01:16383, compu {phys=raw*200 for raw 0..16250, 16382=Cx3ffe_Init (CM_BMC_Dauer_Ladeleistung_02_Cx3ffe_Init), 16383=Cx3fff_Fehler (CM_BMC_Dauer_Ladeleistung_02_Cx3fff_Fehler); unit Unit_Watt}, range phys 0..3250000 Unit_Watt, raw 0..16383, unit=Unit_Watt, transfer-property=PENDING  # ist die aktuelle Dauer-Leistungsfähigkeit der Batterie. Wenn dieser Wert überschritten wird, kann ein zeitliches Derating der maximalen Leistungsgrenzen stattfindet. Die Dauerleistung ändert sich mit Batterietemperatur und Ladezustand.
  pdu BMC_HV_14_XIX_HCP5_CANFD01: length=12, transmission-mode-true-timing=cyclic-timing={time-offset=0, time-period=0.1}, unused-bit-pattern=0
    signal BMC_UBE_Indikator_XIX_BMC_HV_14_XIX_HCP5_CANFD01: start 12, 11 bit, little-endian, data-type-policy=OVERRIDE, i-signal-type=PRIMITIVE, init-value=2046, base-type=BT_BMC_UBE_Indikator, invalid-value=Invalid_BMC_UBE_Indikator_XIX_BMC_HV_14_XIX_HCP5_CANFD01:2047, compu {phys=raw*0.1 for raw 0..1000, 2043=Cx7fb_kleiner_0 (CM_BMC_UBE_Indikator_Cx7fb_kleiner_0), 2044=Cx7fc_groesser_100 (CM_BMC_UBE_Indikator_Cx7fc_groesser_100), 2045=Cx7fd_nicht_angelernt (CM_BMC_UBE_Indikator_Cx7fd_nicht_angelernt), 2046=Cx7fe_Init (CM_BMC_UBE_Indikator_Cx7fe_Init), 2047=Cx7ff_Fehler (CM_BMC_UBE_Indikator_Cx7ff_Fehler); unit Unit_PerCent}, range phys 0..100 Unit_PerCent, raw 0..2047, unit=Unit_PerCent, transfer-property=PENDING  # Der UBE Indikator gibt das Verhältnis der aktuellen maximalen UBE (BMC_Max_UBE) zur maximalen UBE einer neuen HV Batterie wieder.
    signal BMC_Range_Indikator_XIX_BMC_HV_14_XIX_HCP5_CANFD01: start 23, 11 bit, little-endian, data-type-policy=OVERRIDE, i-signal-type=PRIMITIVE, init-value=2046, base-type=BT_BMC_Range_Indikator, invalid-value=Invalid_BMC_Range_Indikator_XIX_BMC_HV_14_XIX_HCP5_CANFD01:2047, compu {phys=raw*0.05 for raw 0..2000, 2042=Cx7fa_Funktion_nicht_umgesetzt (CM_BMC_Range_Indikator_Cx7fa_Funktion_nicht_umgesetzt), 2043=Cx7fb_kleiner_0 (CM_BMC_Range_Indikator_Cx7fb_kleiner_0), 2044=Cx7fc_groesser_100 (CM_BMC_Range_Indikator_Cx7fc_groesser_100), 2045=Cx7fd_nicht_angelernt (CM_BMC_Range_Indikator_Cx7fd_nicht_angelernt), 2046=Cx7fe_Init (CM_BMC_Range_Indikator_Cx7fe_Init), 2047=Cx7ff_Fehler (CM_BMC_Range_Indikator_Cx7ff_Fehler); unit Unit_PerCent}, range phys 0..100 Unit_PerCent, raw 0..2047, unit=Unit_PerCent, transfer-property=PENDING  # Der Range-Indikator gibt das Verhältnis der aktuellen maximalen Reichweite zur maximalen Reichweite eines Neufahrzeugs wieder. Da die Reichweite primär von der UBE abhängt, wird dieser Wert im BMC berechnet
    signal BMC_UBE_Indik_last_update_km_XIX_BMC_HV_14_XIX_HCP5_CANFD01: start 34, 20 bit, little-endian, data-type-policy=OVERRIDE, i-signal-type=PRIMITIVE, init-value=1048574, base-type=BT_BMC_UBE_Indik_last_update_km, invalid-value=Invalid_BMC_UBE_Indik_last_update_km_XIX_BMC_HV_14_XIX_HCP5_CANFD01:1048575, compu {phys=raw for raw 0..1048573, 1048574=Cxffffe_Init (CM_BMC_UBE_Indik_last_update_km_Cxffffe_Init), 1048575=Cxfffff_Fehler (CM_BMC_UBE_Indik_last_update_km_Cxfffff_Fehler); unit Unit_KiloMeter}, range phys 0..1048573 Unit_KiloMeter, raw 0..1048575, unit=Unit_KiloMeter, transfer-property=PENDING  # Strecke seit letzter Aktualisierung des UBE-Indikators in Kilometern.
    signal BMC_EnergieVorhalt_XIX_BMC_HV_14_XIX_HCP5_CANFD01: start 54, 16 bit, little-endian, data-type-policy=OVERRIDE, i-signal-type=PRIMITIVE, init-value=65534, base-type=BT_BMC_EnergieVorhalt, invalid-value=Invalid_BMC_EnergieVorhalt_XIX_BMC_HV_14_XIX_HCP5_CANFD01:65535, compu {phys=raw*0.1 for raw 0..65532, 65533=Cxfffd_Funktion_nicht_umgesetzt (CM_BMC_EnergieVorhalt_Cxfffd_Funktion_nicht_umgesetzt), 65534=Cxfffe_Init (CM_BMC_EnergieVorhalt_Cxfffe_Init), 65535=Cxffff_Fehler (CM_BMC_EnergieVorhalt_Cxffff_Fehler); unit Unit_KiloWattHour}, range phys 0..6553.2 Unit_KiloWattHour, raw 0..65535, unit=Unit_KiloWattHour, transfer-property=PENDING  # Energievorhalt der Batterie (z.B. als Alterungsreserve), welcher nicht in der aktuellen Betriebsstrategie verwendet werden kann, aber zu Kompensation der Alterung genutzt werden kann.
    signal BMC_PCM_VTD_Freeze_Req_XIX_BMC_HV_14_XIX_HCP5_CANFD01: start 70, 2 bit, little-endian, data-type-policy=OVERRIDE, i-signal-type=PRIMITIVE, init-value=2, base-type=BT_BMC_PCM_VTD_Freeze_Req, invalid-value=Invalid_BMC_PCM_VTD_Freeze_Req_XIX_BMC_HV_14_XIX_HCP5_CANFD01:3, compu {0=Cx0_NoResetResponse (CM_BMC_PCM_VTD_Freeze_Req_Cx0_NoResetResponse), 1=Cx1_ResetResponse (CM_BMC_PCM_VTD_Freeze_Req_Cx1_ResetResponse), 2=Cx2_Init (CM_BMC_PCM_VTD_Freeze_Req_Cx2_Init), 3=Cx3_Fehler (CM_BMC_PCM_VTD_Freeze_Req_Cx3_Fehler)}, range raw 0..3, transfer-property=PENDING  # Synchronisierung der Freeze-Condition für VTD-IT's zwischen BMC und HCP1
    signal BMC_PCM_VTD_LifeTimeReset_Req_XIX_BMC_HV_14_XIX_HCP5_CANFD01: start 72, 2 bit, little-endian, data-type-policy=OVERRIDE, i-signal-type=PRIMITIVE, init-value=2, base-type=BT_BMC_PCM_VTD_LifeTimeReset_Req, invalid-value=Invalid_BMC_PCM_VTD_LifeTimeReset_Req_XIX_BMC_HV_14_XIX_HCP5_CANFD01:3, compu {0=Cx0_NoResetResponse (CM_BMC_PCM_VTD_LifeTimeReset_Req_Cx0_NoResetResponse), 1=Cx1_ResetResponse (CM_BMC_PCM_VTD_LifeTimeReset_Req_Cx1_ResetResponse), 2=Cx2_Init (CM_BMC_PCM_VTD_LifeTimeReset_Req_Cx2_Init), 3=Cx3_Fehler (CM_BMC_PCM_VTD_LifeTimeReset_Req_Cx3_Fehler)}, range raw 0..3, transfer-property=PENDING  # Synchronisierung der Freeze-Condition für VTD-IT's zwischen BMC und HCP1
    signal BMC_PCM_VTD_LifeTimeReset_Resp_XIX_BMC_HV_14_XIX_HCP5_CANFD01: start 74, 2 bit, little-endian, data-type-policy=OVERRIDE, i-signal-type=PRIMITIVE, init-value=2, base-type=BT_BMC_PCM_VTD_LifeTimeReset_Resp, invalid-value=Invalid_BMC_PCM_VTD_LifeTimeReset_Resp_XIX_BMC_HV_14_XIX_HCP5_CANFD01:3, compu {0=Cx0_NoResetResponse (CM_BMC_PCM_VTD_LifeTimeReset_Resp_Cx0_NoResetResponse), 1=Cx1_ResetResponse (CM_BMC_PCM_VTD_LifeTimeReset_Resp_Cx1_ResetResponse), 2=Cx2_Init (CM_BMC_PCM_VTD_LifeTimeReset_Resp_Cx2_Init), 3=Cx3_Fehler (CM_BMC_PCM_VTD_LifeTimeReset_Resp_Cx3_Fehler)}, range raw 0..3, transfer-property=PENDING  # Synchronisierung der Freeze-Condition für VTD-IT's zwischen BMC und HCP1
    signal BMC_PCM_VTD_RecentReset_Req_XIX_BMC_HV_14_XIX_HCP5_CANFD01: start 76, 2 bit, little-endian, data-type-policy=OVERRIDE, i-signal-type=PRIMITIVE, init-value=2, base-type=BT_BMC_PCM_VTD_RecentReset_Req, invalid-value=Invalid_BMC_PCM_VTD_RecentReset_Req_XIX_BMC_HV_14_XIX_HCP5_CANFD01:3, compu {0=Cx0_NoResetResponse (CM_BMC_PCM_VTD_RecentReset_Req_Cx0_NoResetResponse), 1=Cx1_ResetResponse (CM_BMC_PCM_VTD_RecentReset_Req_Cx1_ResetResponse), 2=Cx2_Init (CM_BMC_PCM_VTD_RecentReset_Req_Cx2_Init), 3=Cx3_Fehler (CM_BMC_PCM_VTD_RecentReset_Req_Cx3_Fehler)}, range raw 0..3, transfer-property=PENDING  # Synchronisierung der Freeze-Condition für VTD-IT's zwischen BMC und HCP1
  pdu HVK_03_XIX_HCP5_CANFD01_E2E: length=8, minimum-delay=0.01, transmission-mode-true-timing=event-controlled-timing={number-of-repetitions=0, repetition-period=0}, unused-bit-pattern=0  # Fuer die Botschaft ist das Cyclic-Timing 0.1 zu verwenden.
    signal HVK_03_CRC_XIX_HVK_03_XIX_HCP5_CANFD01: start 0, 8 bit, little-endian, data-type-policy=OVERRIDE, i-signal-type=PRIMITIVE, init-value=0, base-type=BT_HVK_03_CRC, compu {phys=raw for raw 0..255}, range phys 0..255, raw 0..255, to BMC_HV(timeout 1 s)  # Für MLB: "Berechnung siehe Lastenheft "Kommunikationsabsicherung für FlexRay und CAN"" Ab MQB und MLBevo: "Berechnung siehe Lastenheft "End-to-End Kommunikationsabsicherung"" Endwerte siehe Begleitdokument "S-PDU Kennungsfolgen"
    signal HVK_03_BZ_XIX_HVK_03_XIX_HCP5_CANFD01: start 8, 4 bit, little-endian, data-type-policy=OVERRIDE, i-signal-type=PRIMITIVE, init-value=0, base-type=BT_HVK_03_BZ, compu {phys=raw for raw 0..15}, range phys 0..15, raw 0..15, to BMC_HV(timeout 1 s)
    signal HVK_Istmodus_Anf_XIX_HVK_03_XIX_HCP5_CANFD01: start 12, 1 bit, little-endian, data-type-policy=OVERRIDE, i-signal-type=PRIMITIVE, init-value=0, base-type=BT_HVK_Istmodus_Anf, compu {0=Cx0_nicht_angefordert (CM_HVK_Istmodus_Anf_Cx0_nicht_angefordert), 1=Cx1_angefordert (CM_HVK_Istmodus_Anf_Cx1_angefordert)}, range raw 0..1, to BMC_HV(timeout 1 s)  # HVK-Anforderung an alle HV-Komponenten deren Istmodus im schnellen Zyklus (Inhibitzeit) zu senden.
    signal HVK_BMC_Sollmodus_XIX_HVK_03_XIX_HCP5_CANFD01: start 13, 3 bit, little-endian, data-type-policy=OVERRIDE, i-signal-type=PRIMITIVE, init-value=7, base-type=BT_HVK_BMC_Sollmodus, compu {0=Cx0_HV_Off (CM_HVK_BMC_Sollmodus_Cx0_HV_Off), 1=Cx1_HV_On (CM_HVK_BMC_Sollmodus_Cx1_HV_On), 4=Cx4_AC_Laden (CM_HVK_BMC_Sollmodus_Cx4_AC_Laden), 6=Cx6_DC_Laden (CM_HVK_BMC_Sollmodus_Cx6_DC_Laden), 7=Cx7_Init (CM_HVK_BMC_Sollmodus_Cx7_Init)}, range raw 0..7, to BMC_HV(timeout 1 s)  # Anforderung des Schaltzustand der HV-Batterie
    signal HVK_BMC_Spannung_Anf_XIX_HVK_03_XIX_HCP5_CANFD01: start 16, 4 bit, little-endian, data-type-policy=OVERRIDE, i-signal-type=PRIMITIVE, init-value=3, base-type=BT_HVK_BMC_Spannung_Anf, compu {0=Cx0_keine_Spg_Anforderung (CM_HVK_BMC_Spannung_Anf_Cx0_keine_Spg_Anforderung), 1=Cx1_400V_Spg_Anforderung (CM_HVK_BMC_Spannung_Anf_Cx1_400V_Spg_Anforderung), 2=Cx2_800V_Spg_Anforderung (CM_HVK_BMC_Spannung_Anf_Cx2_800V_Spg_Anforderung), 3=Cx3_Init (CM_HVK_BMC_Spannung_Anf_Cx3_Init)}, range raw 0..3, to BMC_HV(timeout 1 s)  # Anforderung der Spannungslage von der HV-Batterie
    signal HVK_HVHL_Sollmodus_XIX_HVK_03_XIX_HCP5_CANFD01: start 20, 2 bit, little-endian, data-type-policy=OVERRIDE, i-signal-type=PRIMITIVE, init-value=3, base-type=BT_HVK_HVHL_Sollmodus, compu {0=Cx0_Keine_Freigabe (CM_HVK_HVHL_Sollmodus_Cx0_Keine_Freigabe), 1=Cx1_Freigabe (CM_HVK_HVHL_Sollmodus_Cx1_Freigabe), 2=Cx2_Freigabe_ausgesetzt (CM_HVK_HVHL_Sollmodus_Cx2_Freigabe_ausgesetzt), 3=Cx3_Init (CM_HVK_HVHL_Sollmodus_Cx3_Init)}, range raw 0..3  # Kommandierung des HV-Heizer- Luft, als Teilnehmer der HV-Netzsteuerung
    signal HVK_HVHW_Sollmodus_XIX_HVK_03_XIX_HCP5_CANFD01: start 22, 2 bit, little-endian, data-type-policy=OVERRIDE, i-signal-type=PRIMITIVE, init-value=3, base-type=BT_HVK_HVHW_Sollmodus, compu {0=Cx0_Keine_Freigabe (CM_HVK_HVHW_Sollmodus_Cx0_Keine_Freigabe), 1=Cx1_Freigabe (CM_HVK_HVHW_Sollmodus_Cx1_Freigabe), 2=Cx2_Freigabe_ausgesetzt (CM_HVK_HVHW_Sollmodus_Cx2_Freigabe_ausgesetzt), 3=Cx3_Init (CM_HVK_HVHW_Sollmodus_Cx3_Init)}, range raw 0..3  # Kommandierung des HV-Heizer- Wasser, als Teilnehmer der HV-Netzsteuerung
    signal HVK_DCDC_Sollmodus_XIX_HVK_03_XIX_HCP5_CANFD01: start 24, 3 bit, little-endian, data-type-policy=OVERRIDE, i-signal-type=PRIMITIVE, init-value=7, base-type=BT_HVK_DCDC_Sollmodus, compu {0=Cx0_Standby (CM_HVK_DCDC_Sollmodus_Cx0_Standby), 1=Cx1_HV_On_Vorladen (CM_HVK_DCDC_Sollmodus_Cx1_HV_On_Vorladen), 2=Cx2_Tiefsetzen (CM_HVK_DCDC_Sollmodus_Cx2_Tiefsetzen), 3=Cx3_Hochsetzen (CM_HVK_DCDC_Sollmodus_Cx3_Hochsetzen), 4=Cx4_Pruefpuls_12V (CM_HVK_DCDC_Sollmodus_Cx4_Pruefpuls_12V), 6=Cx6_Pruefpuls_DC_Laden (CM_HVK_DCDC_Sollmodus_Cx6_Pruefpuls_DC_Laden), 7=Cx7_Initialisierung (CM_HVK_DCDC_Sollmodus_Cx7_Initialisierung)}, range raw 0..7  # angeforderte Soll-Betriebsart des DC/DC-Wandlers: 0: Standby; Kommunikation aktiv 1: Zwischenkreis des HV-Netzes wird vorgeladen; HV-Netz wird aktiviert und darf nicht belastet werden. 2: Tiefsetzen (HV --> BN 14,4V) Sollwertvorgabe projektabhängig vom BSG/BCM über Lin/BSS oder vom MSG über 'MO_DC_SollSpannung_NV' bzw. 'MY2_DC_uSetPLV' (PQ35/PL71: Sollwertvorgabe vom BSG) 3: Hochsetzen; Nachladen des HV-Energiespeichers aus dem NV-Energiespeicher 4: Prüfpuls für die 12V-Bordnetzdiagnose. Stromvorgabe kommt von 12V-Seite 5: nicht verfügbar / Rückmeldesignal für internen Fehler DC/DC-Wandler 6: Pruefpuls auf HV-Spannung von <60V durch den DCDC für die Prüfung der Ladeinfrastruktur vor dem Start des DC-Ladevorgangs 7: MSG befindet sich in der Init-Phase; aktuelle Signalwerte nicht gültig; DC/DC soll aktuellen Modus beibehalten (Beibehalten des aktuellen Modus ohne gültigen Sollmodus nur für eine maximale Dauer erlaubt t.b.d.)
    signal HVK_EKK_Sollmodus_XIX_HVK_03_XIX_HCP5_CANFD01: start 27, 3 bit, little-endian, data-type-policy=OVERRIDE, i-signal-type=PRIMITIVE, init-value=7, base-type=BT_HVK_EKK_Sollmodus, compu {0=Cx0_Keine_Freigabe (CM_HVK_EKK_Sollmodus_Cx0_Keine_Freigabe), 1=Cx1_Freigabe (CM_HVK_EKK_Sollmodus_Cx1_Freigabe), 2=Cx2_Freigabe_ausgesetzt (CM_HVK_EKK_Sollmodus_Cx2_Freigabe_ausgesetzt), 7=Cx7_Init (CM_HVK_EKK_Sollmodus_Cx7_Init)}, range raw 0..7  # Sollmodus elektrischer Klimakompressor
    signal HVK_ETM_Freigabe_XIX_HVK_03_XIX_HCP5_CANFD01: start 30, 2 bit, little-endian, data-type-policy=OVERRIDE, i-signal-type=PRIMITIVE, init-value=3, base-type=BT_HVK_ETM_Freigabe, compu {0=Cx0_keine_Freigabe (CM_HVK_ETM_Freigabe_Cx0_keine_Freigabe), 1=Cx1_Freigabe (CM_HVK_ETM_Freigabe_Cx1_Freigabe), 2=Cx2_Freigabe_Sonderbetrieb (CM_HVK_ETM_Freigabe_Cx2_Freigabe_Sonderbetrieb), 3=Cx3_Init (CM_HVK_ETM_Freigabe_Cx3_Init)}, range raw 0..3  # HV-Freigabe für den Antrieb (ETM - Elektr.TraktionsManager)
    signal HVK_HV_Netz_Zustand_XIX_HVK_03_XIX_HCP5_CANFD01: start 32, 4 bit, little-endian, data-type-policy=OVERRIDE, i-signal-type=PRIMITIVE, init-value=15, base-type=BT_HVK_HV_Netz_Zustand, compu {0=Cx0_Aus (CM_HVK_HV_Netz_Zustand_Cx0_Aus), 1=Cx1_Aktivierung (CM_HVK_HV_Netz_Zustand_Cx1_Aktivierung), 2=Cx2_Diagnose (CM_HVK_HV_Netz_Zustand_Cx2_Diagnose), 3=Cx3_Aktiv (CM_HVK_HV_Netz_Zustand_Cx3_Aktiv), 4=Cx4_Fahrbetrieb (CM_HVK_HV_Netz_Zustand_Cx4_Fahrbetrieb), 5=Cx5_AC_Ladebetrieb (CM_HVK_HV_Netz_Zustand_Cx5_AC_Ladebetrieb), 6=Cx6_DC_Ladebetrieb (CM_HVK_HV_Netz_Zustand_Cx6_DC_Ladebetrieb), 7=Cx7_Aktiv_ohne_HVSpeicher (CM_HVK_HV_Netz_Zustand_Cx7_Aktiv_ohne_HVSpeicher), 11=Cxb_Aus_Fehlerfall (CM_HVK_HV_Netz_Zustand_Cxb_Aus_Fehlerfall), 12=Cxc_lastfreie_Abschaltung (CM_HVK_HV_Netz_Zustand_Cxc_lastfreie_Abschaltung), 13=Cxd_Notabschaltung (CM_HVK_HV_Netz_Zustand_Cxd_Notabschaltung), 14=Cxe_Entladung (CM_HVK_HV_Netz_Zustand_Cxe_Entladung), 15=Cxf_Init (CM_HVK_HV_Netz_Zustand_Cxf_Init)}, range raw 0..15  # Aktueller Zustand des HV-Netzes
    signal HVK_Iso_Messung_Start_XIX_HVK_03_XIX_HCP5_CANFD01: start 36, 3 bit, little-endian, data-type-policy=OVERRIDE, i-signal-type=PRIMITIVE, init-value=0, base-type=BT_HVK_Iso_Messung_Start, compu {0=Cx0_keine_Messung (CM_HVK_Iso_Messung_Start_Cx0_keine_Messung), 1=Cx1_Messung_HV_Netz_1 (CM_HVK_Iso_Messung_Start_Cx1_Messung_HV_Netz_1), 2=Cx2_Messung_HV_Netz_2 (CM_HVK_Iso_Messung_Start_Cx2_Messung_HV_Netz_2), 4=Cx4_deaktiviert (CM_HVK_Iso_Messung_Start_Cx4_deaktiviert)}, range raw 0..4, to BMC_HV(timeout 1 s)  # Anforderung an die isolationswiderstandsüberwachenden HV-Komponenten zur Durchführung der Isolations-Widerstandsmessung.
    signal HVK_Vorladung_aktiv_XIX_HVK_03_XIX_HCP5_CANFD01: start 39, 1 bit, little-endian, data-type-policy=OVERRIDE, i-signal-type=PRIMITIVE, init-value=0, base-type=BT_HVK_Vorladung_aktiv, compu {0=Cx0_Vorladung_nicht_aktiv (CM_HVK_Vorladung_aktiv_Cx0_Vorladung_nicht_aktiv), 1=Cx1_Vorladung_aktiv (CM_HVK_Vorladung_aktiv_Cx1_Vorladung_aktiv)}, range raw 0..1  # Systeminformation, dass aktiv vorgeladen wird
    signal HVK_Gesamtst_Spgfreiheit_XIX_HVK_03_XIX_HCP5_CANFD01: start 40, 2 bit, little-endian, data-type-policy=OVERRIDE, i-signal-type=PRIMITIVE, init-value=0, base-type=BT_HVK_Gesamtst_Spgfreiheit, invalid-value=Invalid_HVK_Gesamtst_Spgfreiheit_XIX_HVK_03_XIX_HCP5_CANFD01:3, compu {0=Cx0_Funktion_Init_ohne_Funktion (CM_HVK_Gesamtst_Spgfreiheit_Cx0_Funktion_Init_ohne_Funktion) (Funktion_Init__ohne_Funktion), 1=Cx1_HV_System_spannungsfrei (CM_HVK_Gesamtst_Spgfreiheit_Cx1_HV_System_spannungsfrei), 2=Cx2_HV_System_nicht_spannungsfrei (CM_HVK_Gesamtst_Spgfreiheit_Cx2_HV_System_nicht_spannungsfrei), 3=Cx3_Fehler (CM_HVK_Gesamtst_Spgfreiheit_Cx3_Fehler)}, range raw 0..3  # Status des HV-Systems
    signal HVK_HV_Netz_Warnungen_XIX_HVK_03_XIX_HCP5_CANFD01: start 42, 2 bit, little-endian, data-type-policy=OVERRIDE, i-signal-type=PRIMITIVE, init-value=0, base-type=BT_HVK_HV_Netz_Warnungen, compu {0=Cx0_Keine_Warnung (CM_HVK_HV_Netz_Warnungen_Cx0_Keine_Warnung), 1=Cx1_Warntext_HV_Netz_Anf (CM_HVK_HV_Netz_Warnungen_Cx1_Warntext_HV_Netz_Anf), 2=Cx2_Fehlertext_HV_Netz_Anf (CM_HVK_HV_Netz_Warnungen_Cx2_Fehlertext_HV_Netz_Anf), 3=Cx3_Warnung_Kein_Wiederstart_moeglich (CM_HVK_HV_Netz_Warnungen_Cx3_Warnung_Kein_Wiederstart_moeglich)}, range raw 0..3  # Anforderung Warnung/Fehler HV-System im Kombi 0: Keine Warnung/Init 1:Anforderung_Anzeige_Warnung_HV-Netz (gelbes Symbol) 2:Anforderung_Anzeige_Fehler_HV-Netz (rotes Symbol) 3:Anforderung_Anzeige_Warnung_Kein_Wiederstart_möglich
    signal HVK_eKAT_Sollmodus_XIX_HVK_03_XIX_HCP5_CANFD01: start 44, 2 bit, little-endian, data-type-policy=OVERRIDE, i-signal-type=PRIMITIVE, init-value=3, base-type=BT_HVK_eKAT_Sollmodus, compu {0=Cx0_Standby (CM_HVK_eKAT_Sollmodus_Cx0_Standby), 1=Cx1_Freigabe (CM_HVK_eKAT_Sollmodus_Cx1_Freigabe), 2=Cx2_Freigabe_ausgesetzt (CM_HVK_eKAT_Sollmodus_Cx2_Freigabe_ausgesetzt), 3=Cx3_Init (CM_HVK_eKAT_Sollmodus_Cx3_Init)}, range raw 0..3  # Angeforderter Sollmodus für den eKAT
    signal HVK_AIAD_Sollmodus_XIX_HVK_03_XIX_HCP5_CANFD01: start 46, 2 bit, little-endian, data-type-policy=OVERRIDE, i-signal-type=PRIMITIVE, init-value=3, base-type=BT_HVK_AIAD_Sollmodus, compu {0=Cx0_Keine_Freigabe (CM_HVK_AIAD_Sollmodus_Cx0_Keine_Freigabe), 1=Cx1_Freigabe (CM_HVK_AIAD_Sollmodus_Cx1_Freigabe), 2=Cx2_Freigabe_ausgesetzt (CM_HVK_AIAD_Sollmodus_Cx2_Freigabe_ausgesetzt), 3=Cx3_Init (CM_HVK_AIAD_Sollmodus_Cx3_Init)}, range raw 0..3  # HV-Netz Sollmodus für das ADC
    signal HVK_HVLM_Sollmodus_XIX_HVK_03_XIX_HCP5_CANFD01: start 48, 3 bit, little-endian, data-type-policy=OVERRIDE, i-signal-type=PRIMITIVE, init-value=7, base-type=BT_HVK_HVLM_Sollmodus, compu {0=Cx0_keine_Freigabe (CM_HVK_HVLM_Sollmodus_Cx0_keine_Freigabe), 1=Cx1_Freigabe_Lademanager (CM_HVK_HVLM_Sollmodus_Cx1_Freigabe_Lademanager), 2=Cx2_Vorladung_AC_Pfad (CM_HVK_HVLM_Sollmodus_Cx2_Vorladung_AC_Pfad), 7=Cx7_Init (CM_HVK_HVLM_Sollmodus_Cx7_Init)}, range raw 0..7  # Angeforderter Sollmodus des Lademanagers.
    signal HV_Bordnetz_aktiv_XIX_HVK_03_XIX_HCP5_CANFD01: start 51, 1 bit, little-endian, data-type-policy=OVERRIDE, i-signal-type=PRIMITIVE, init-value=0, base-type=BT_HV_Bordnetz_aktiv, compu {0=Cx0_inaktiv (CM_HV_Bordnetz_aktiv_Cx0_inaktiv), 1=Cx1_aktiv (CM_HV_Bordnetz_aktiv_Cx1_aktiv)}, range raw 0..1  # Signalisiert ein aktives Hochvoltbordnetz. Für die Belastbarkeit des HV-Netzes müssen Strom- bzw. Leistungsgrenzen eingehalten werden
    signal HVK_AktiveEntladung_Anf_XIX_HVK_03_XIX_HCP5_CANFD01: start 52, 1 bit, little-endian, data-type-policy=OVERRIDE, i-signal-type=PRIMITIVE, init-value=0, base-type=BT_HVK_AktiveEntladung_Anf, compu {0=Cx0_nicht_angefordert (CM_HVK_AktiveEntladung_Anf_Cx0_nicht_angefordert), 1=Cx1_angefordert (CM_HVK_AktiveEntladung_Anf_Cx1_angefordert)}, range raw 0..1  # Anforderung zum aktiven Entladen des HV-Netzes, während der Abschaltung des HV-Netz.
    signal HV_Bordnetz_Fehler_XIX_HVK_03_XIX_HCP5_CANFD01: start 53, 1 bit, little-endian, data-type-policy=OVERRIDE, i-signal-type=PRIMITIVE, init-value=0, base-type=BT_HV_Bordnetz_Fehler, invalid-value=Invalid_HV_Bordnetz_Fehler_XIX_HVK_03_XIX_HCP5_CANFD01:1, compu {0=Cx0_kein_Fehler (CM_HV_Bordnetz_Fehler_Cx0_kein_Fehler), 1=Cx1_Fehler (CM_HV_Bordnetz_Fehler_Cx1_Fehler)}, range raw 0..1  # Status ob im HV-Netz ein Fehler detektiert wurde.
    signal ISignalVoid_HVK_03_XIX_HCP5_CANFD01_0: start 54, 2 bit, little-endian, system signal SignalVoid_HVK_03_0, data-type-policy=OVERRIDE, i-signal-type=PRIMITIVE, base-type=BT_SignalVoid
    signal ISignalVoid_HVK_03_XIX_HCP5_CANFD01_1: start 56, 8 bit, little-endian, system signal SignalVoid_HVK_03_1, data-type-policy=OVERRIDE, i-signal-type=PRIMITIVE, base-type=BT_SignalVoid
    mapping SG_HVK_03_XIX_HCP5_CANFD01: i-signal-group=SG_HVK_03_XIX_HCP5_CANFD01, transfer-property=TRIGGERED-WITHOUT-REPETITION
  pdu OBD_HCP1_XIX_HCP5_CANFD01: length=2, transmission-mode-true-timing=cyclic-timing={time-offset=0, time-period=0.32}, unused-bit-pattern=0
    signal OBDProtocol_req_XIX_OBD_HCP1_XIX_HCP5_CANFD01: start 0, 4 bit, little-endian, data-type-policy=OVERRIDE, i-signal-type=PRIMITIVE, init-value=14, base-type=BT_OBDProtocol_req, invalid-value=Invalid_OBDProtocol_req_XIX_OBD_HCP1_XIX_HCP5_CANFD01:15, compu {0=Cx0_not_available (CM_OBDProtocol_req_Cx0_not_available), 1=Cx1_OBDclassic (CM_OBDProtocol_req_Cx1_OBDclassic), 2=Cx2_OBDonUDS (CM_OBDProtocol_req_Cx2_OBDonUDS), 3=Cx3_ZEVonUDS (CM_OBDProtocol_req_Cx3_ZEVonUDS), 14=Cxe_Init (CM_OBDProtocol_req_Cxe_Init), 15=Cxf_Fehler (CM_OBDProtocol_req_Cxf_Fehler)}, range raw 0..15, transfer-property=PENDING, to BMC_HV(timeout 3.2 s)  # OBD protocol information 'used OBD protocol' from MIL master
    signal HCP1_Indc_StChk_XIX_OBD_HCP1_XIX_HCP5_CANFD01: start 4, 1 bit, little-endian, data-type-policy=OVERRIDE, i-signal-type=PRIMITIVE, init-value=1, base-type=BT_HCP1_Indc_StChk, compu {0=Cx0_Completed (CM_HCP1_Indc_StChk_Cx0_Completed), 1=Cx1_NotCompleted (CM_HCP1_Indc_StChk_Cx1_NotCompleted)}, range raw 0..1, transfer-property=PENDING  # EU7 OBM-Inducement Request TestNotCompletedThisOperationCycle
    signal HCP1_Indc_StFail_XIX_OBD_HCP1_XIX_HCP5_CANFD01: start 5, 1 bit, little-endian, data-type-policy=OVERRIDE, i-signal-type=PRIMITIVE, init-value=0, base-type=BT_HCP1_Indc_StFail, compu {0=Cx0_Passive (CM_HCP1_Indc_StFail_Cx0_Passive), 1=Cx1_Active (CM_HCP1_Indc_StFail_Cx1_Active)}, range raw 0..1, transfer-property=PENDING  # EU7 OBM-Inducement Request TestFailed
  pdu OBD_Hybrid_01_XIX_HCP5_CANFD01: length=2, transmission-mode-true-timing=cyclic-timing={time-offset=0, time-period=0.32}, unused-bit-pattern=0
    signal OBDProtocol_Hybrid_01_XIX_OBD_Hybrid_01_XIX_HCP5_CANFD01: start 0, 4 bit, little-endian, data-type-policy=OVERRIDE, i-signal-type=PRIMITIVE, init-value=14, base-type=BT_OBDProtocol_Hybrid_01, invalid-value=Invalid_OBDProtocol_Hybrid_01_XIX_OBD_Hybrid_01_XIX_HCP5_CANFD01:15, compu {0=Cx0_not_available (CM_OBDProtocol_Hybrid_01_Cx0_not_available), 1=Cx1_OBDclassic (CM_OBDProtocol_Hybrid_01_Cx1_OBDclassic), 2=Cx2_OBDonUDS (CM_OBDProtocol_Hybrid_01_Cx2_OBDonUDS), 3=Cx3_ZEVonUDS (CM_OBDProtocol_Hybrid_01_Cx3_ZEVonUDS), 4=Cx4_NoOBD (CM_OBDProtocol_Hybrid_01_Cx4_NoOBD), 14=Cxe_Init (CM_OBDProtocol_Hybrid_01_Cxe_Init), 15=Cxf_Fehler (CM_OBDProtocol_Hybrid_01_Cxf_Fehler)}, range raw 0..15, transfer-property=PENDING  # OBD protocol response 'used OBD protocol' from PrimaryOBDECUs to MIL_Master
    signal Hybrid_01_Indc_StChk_XIX_OBD_Hybrid_01_XIX_HCP5_CANFD01: start 4, 1 bit, little-endian, data-type-policy=OVERRIDE, i-signal-type=PRIMITIVE, init-value=1, base-type=BT_Hybrid_01_Indc_StChk, compu {0=Cx0_Completed (CM_Hybrid_01_Indc_StChk_Cx0_Completed), 1=Cx1_NotCompleted (CM_Hybrid_01_Indc_StChk_Cx1_NotCompleted)}, range raw 0..1, transfer-property=PENDING  # EU7 OBM-Inducement Request TestNotCompletedThisOperationCycle
    signal Hybrid_01_Indc_StFail_XIX_OBD_Hybrid_01_XIX_HCP5_CANFD01: start 5, 1 bit, little-endian, data-type-policy=OVERRIDE, i-signal-type=PRIMITIVE, init-value=0, base-type=BT_Hybrid_01_Indc_StFail, compu {0=Cx0_Passive (CM_Hybrid_01_Indc_StFail_Cx0_Passive), 1=Cx1_Active (CM_Hybrid_01_Indc_StFail_Cx1_Active)}, range raw 0..1, transfer-property=PENDING  # EU7 OBM-Inducement Request TestFailed
  pdu SOK_Zeit_Hybrid_01_Resp_01_XIX_HCP5_CANFD01: length=8, minimum-delay=0.1, transmission-mode-true-timing=event-controlled-timing={number-of-repetitions=0, repetition-period=0}, unused-bit-pattern=0
    signal SOK_Zeit_Hybrid_01_Zeit_XIX_SOK_Zeit_Hybrid_01_Resp_01_XIX_HCP5_CANFD01: start 0, 56 bit, opaque, data-type-policy=OVERRIDE, i-signal-type=ARRAY, base-type=BT_SOK_Zeit_Hybrid_01_Zeit, compu {phys=raw for raw 0..7.20575940379279e+16; unit Unit_None}, range phys 0..72057594037927935 Unit_None, raw 0..72057594037927935, unit=Unit_None, transfer-property=TRIGGERED-ON-CHANGE-WITHOUT-REPETITION, to BMC_HV  # Response signal of SOK time server to challenge of an SOK participant, containing SOK time
  user defined i pdu CDD_HCP5_CANFD01_XIX_TPCHType_CANFD_DAAP_XIX_0x1C403F7B_XIX_0x1C423F7B_XIX_Physical: length=512, cdd-type=TPCHType_CANFD_DAAP
  user defined i pdu CDD_HCP5_CANFD01_XIX_TPCHType_CANFD_DAAP_XIX_0x1C413FDD_XIX_Functional: length=62, cdd-type=TPCHType_CANFD_DAAP
  user defined i pdu CDD_HCP5_CANFD01_XIX_TPCHType_CANFD_DAAP_XIX_0x1C423F7B_XIX_0x1C403F7B_XIX_Physical: length=512, cdd-type=TPCHType_CANFD_DAAP
package /IPDUGroup
  19 x i signal i pdu group:
    BMC_HV_XIX_BMC_CAN01_Rx: communication-direction=IN, communication-mode=CAN_Receive_All
      i-signal-i-pdus:
        UI1_{03..05}_XIX_BMC_CAN01
        UI2_04_XIX_BMC_CAN01
        UI1_Komponentenfehler_01_XIX_BMC_CAN01
        UI1_Komponentenfehler_02_XIX_BMC_CAN01
        UI2_Komponentenfehler_01_XIX_BMC_CAN01
        UI2_Komponentenfehler_02_XIX_BMC_CAN01
        UI2Sens02_CALID_01_XIX_BMC_CAN01
        UI2Sens02_CALID_02_XIX_BMC_CAN01
        UI2Sens02_CVN_XIX_BMC_CAN01
        UI2Sens01_CVN_XIX_BMC_CAN01
        UI2Sens01_CALID_01_XIX_BMC_CAN01
        UI2Sens01_CALID_02_XIX_BMC_CAN01
        BJB_CVN_01_XIX_BMC_CAN01
        BJB_CALID_01_XIX_BMC_CAN01
        BJB_CALID_02_XIX_BMC_CAN01
        BJB_08_XIX_BMC_CAN01
        UI1_01_XIX_BMC_CAN01_E2E
        UI1_02_XIX_BMC_CAN01_E2E
        UI2_{01..03}_XIX_BMC_CAN01_E2E
        BJB_{10..13}_XIX_BMC_CAN01_E2E
    BMC_HV_XIX_BMC_CAN01_Tx: communication-direction=OUT, communication-mode=CAN_Transmit_All
      i-signal-i-pdus:
        OTAMC_D_01_XIX_BMC_CAN01
        ORU_Control_D_01_XIX_BMC_CAN01
        ORU_Control_A_01_XIX_BMC_CAN01
        Systeminfo_01_XIX_BMC_CAN01
        ORU_01_XIX_BMC_CAN01
        ClampControl_01_XIX_BMC_CAN01
        OBD_03_XIX_BMC_CAN01
        OBD_04_XIX_BMC_CAN01
        BMC_HV_04_XIX_BMC_CAN01_E2E
        BMC_HV_{10..13}_XIX_BMC_CAN01_E2E
    BMC_HV_XIX_HCP5_CANFD01_Rx: communication-direction=IN, communication-mode=CAN_Receive_All
      i-signal-i-pdus:
        NVEM_12_XIX_HCP5_CANFD01
        HVLM_13_XIX_HCP5_CANFD01
        Airbag_10_XIX_HCP5_CANFD01
        Diagnose_01_XIX_HCP5_CANFD01
        Systeminfo_01_XIX_HCP5_CANFD01
        ORU_01_XIX_HCP5_CANFD01
        DCDC_04_XIX_HCP5_CANFD01
        SOK_NoAuthenticTime_01_XIX_HCP5_CANFD01
        ZeitMaster_01_XIX_HCP5_CANFD01
        WFS_02_XIX_HCP5_CANFD01
        ClampControl_01_XIX_HCP5_CANFD01
        Charisma_20_XIX_HCP5_CANFD01
        Thermomanagement_01_XIX_HCP5_CANFD01
        OTP_01_XIX_HCP5_CANFD01
        OBG_01_XIX_HCP5_CANFD01
        KS_Hybrid_01_Challenge_M_XIX_HCP5_CANFD01
        KS_Hybrid_01_Response_M_XIX_HCP5_CANFD01
        DEV_Hybrid_01_Req_00_XIX_HCP5_CANFD01
        OBD_03_XIX_HCP5_CANFD01
        VDSO_05_XIX_HCP5_CANFD01
        OBD_04_XIX_HCP5_CANFD01
        Zeitmaster_05_XIX_HCP5_CANFD01
        SOK_Zeit_Hybrid_01_Resp_01_XIX_HCP5_CANFD01
        HVEM_07_XIX_HCP5_CANFD01
        ELF_06_XIX_HCP5_CANFD01
        HCP1_17_XIX_HCP5_CANFD01
        DCDC_NV_CALID_XIX_HCP5_CANFD01
        DCDC_NV_CVN_XIX_HCP5_CANFD01
        DCDC_NV_Komponentenfehler_01_XIX_HCP5_CANFD01
        DCDC_NV_Komponentenfehler_03_XIX_HCP5_CANFD01
        DCDC_NV_Komponentenfehler_02_XIX_HCP5_CANFD01
        DCDC_NV_Komponentenfehler_04_XIX_HCP5_CANFD01
        OBD_HCP1_XIX_HCP5_CANFD01
        HVLM_14_XIX_HCP5_CANFD01_E2E
        ORU_Control_A_01_XIX_HCP5_CANFD01_E2E
        ORU_Control_D_01_XIX_HCP5_CANFD01_E2E
        OTAMC_D_01_XIX_HCP5_CANFD01_E2E
        HVK_03_XIX_HCP5_CANFD01_E2E
    BMC_HV_XIX_HCP5_CANFD01_Tx: communication-direction=OUT, communication-mode=CAN_Transmit_All
      i-signal-i-pdus:
        KN_Hybrid_01_XIX_HCP5_CANFD01
        BMC_HV_03_XIX_HCP5_CANFD01
        KS_Hybrid_01_Challenge_K_XIX_HCP5_CANFD01
        KS_Hybrid_01_ReqFrame_XIX_HCP5_CANFD01
        KS_Hybrid_01_Response_K_XIX_HCP5_CANFD01
        BMC_HV_05_XIX_HCP5_CANFD01
        BMC_HV_06_XIX_HCP5_CANFD01
        DEV_Hybrid_01_Resp_FF_XIX_HCP5_CANFD01
        DS_Hybrid_01_XIX_HCP5_CANFD01
        BMC_HV_07_XIX_HCP5_CANFD01
        BMC_HV_08_XIX_HCP5_CANFD01
        BMC_CMC_Zellspannung_05_XIX_HCP5_CANFD01
        BMC_CMC_Zellspannung_04_XIX_HCP5_CANFD01
        BMC_CMC_Zellspannung_03_XIX_HCP5_CANFD01
        BMC_CMC_Zellspannung_02_XIX_HCP5_CANFD01
        BMC_CMC_Zellspannung_01_XIX_HCP5_CANFD01
        BMC_CMC_Temperatur_02_XIX_HCP5_CANFD01
        BMC_CMC_Temperatur_01_XIX_HCP5_CANFD01
        SOK_Zeit_Hybrid_01_Chal_01_XIX_HCP5_CANFD01
        BMC_CMC_Temperatur_03_XIX_HCP5_CANFD01
        BMC_HV_09_XIX_HCP5_CANFD01
        BMC_HV_14_XIX_HCP5_CANFD01
        OBD_Hybrid_01_XIX_HCP5_CANFD01
        BMC_HV_01_XIX_HCP5_CANFD01_E2E
        BMC_HV_02_XIX_HCP5_CANFD01_E2E
    BMC_HV_XIX_PNC_01_CarWakeUp_Tx: communication-direction=OUT, communication-mode=Transmit_01_CarWakeUp, i-signal-i-pdus=[DS_Hybrid_01_XIX_HCP5_CANFD01, KN_Hybrid_01_XIX_HCP5_CANFD01]
    BMC_HV_XIX_PNC_02_Basefunction_Powertrain_Rx: communication-direction=IN, communication-mode=Receive_02_Basefunction_Powertrain, i-signal-i-pdus=[ORU_Control_D_01_XIX_HCP5_CANFD01_E2E, OTAMC_D_01_XIX_HCP5_CANFD01_E2E]
    BMC_HV_XIX_PNC_06_Basefunction_ComfortLight_Rx: communication-direction=IN, communication-mode=Receive_06_Basefunction_ComfortLight, i-signal-i-pdus=[ClampControl_01_XIX_HCP5_CANFD01, WFS_02_XIX_HCP5_CANFD01]
    BMC_HV_XIX_PNC_07_Basefunction_CrossSection_Rx: communication-direction=IN, communication-mode=Receive_07_Basefunction_CrossSection
      i-signal-i-pdus:
        Charisma_20_XIX_HCP5_CANFD01
        Diagnose_01_XIX_HCP5_CANFD01
        ORU_Control_A_01_XIX_HCP5_CANFD01_E2E
        Systeminfo_01_XIX_HCP5_CANFD01
    BMC_HV_XIX_PNC_10_Powertrain_Rx: communication-direction=IN, communication-mode=Receive_10_Powertrain, i-signal-i-pdus=[HCP1_17_XIX_HCP5_CANFD01, OBD_03_XIX_HCP5_CANFD01, OBD_04_XIX_HCP5_CANFD01, OBD_HCP1_XIX_HCP5_CANFD01]
    BMC_HV_XIX_PNC_11_Chassis_Rx: communication-direction=IN, communication-mode=Receive_11_Chassis, i-signal-i-pdus=VDSO_05_XIX_HCP5_CANFD01
    BMC_HV_XIX_PNC_13_Airbag_Rx: communication-direction=IN, communication-mode=Receive_13_Airbag, i-signal-i-pdus=Airbag_10_XIX_HCP5_CANFD01
    BMC_HV_XIX_PNC_24_ThermoManagement_Rx: communication-direction=IN, communication-mode=Receive_24_ThermoManagement, i-signal-i-pdus=[OTP_01_XIX_HCP5_CANFD01, Thermomanagement_01_XIX_HCP5_CANFD01]
    BMC_HV_XIX_PNC_26_HighVoltage_Charging_Rx: communication-direction=IN, communication-mode=Receive_26_HighVoltage_Charging
      i-signal-i-pdus:
        DCDC_04_XIX_HCP5_CANFD01
        DCDC_NV_Komponentenfehler_{01..04}_XIX_HCP5_CANFD01
        ELF_06_XIX_HCP5_CANFD01
        HVLM_13_XIX_HCP5_CANFD01
        HVLM_14_XIX_HCP5_CANFD01_E2E
        OBG_01_XIX_HCP5_CANFD01
    BMC_HV_XIX_PNC_26_HighVoltage_Charging_Tx: communication-direction=OUT, communication-mode=Transmit_26_HighVoltage_Charging
      i-signal-i-pdus:
        BMC_CMC_Temperatur_{01..03}_XIX_HCP5_CANFD01
        BMC_CMC_Zellspannung_{01..05}_XIX_HCP5_CANFD01
        BMC_HV_01_XIX_HCP5_CANFD01_E2E
        BMC_HV_02_XIX_HCP5_CANFD01_E2E
        BMC_HV_03_XIX_HCP5_CANFD01
        BMC_HV_{05..09}_XIX_HCP5_CANFD01
        BMC_HV_14_XIX_HCP5_CANFD01
    BMC_HV_XIX_PNC_27_Timemaster_Timer_Rx: communication-direction=IN, communication-mode=Receive_27_Timemaster_Timer, i-signal-i-pdus=[Diagnose_01_XIX_HCP5_CANFD01, ZeitMaster_01_XIX_HCP5_CANFD01, Zeitmaster_05_XIX_HCP5_CANFD01]
    BMC_HV_XIX_PNC_30_EnergyManagement_Rx: communication-direction=IN, communication-mode=Receive_30_EnergyManagement, i-signal-i-pdus=[HVEM_07_XIX_HCP5_CANFD01, HVK_03_XIX_HCP5_CANFD01_E2E, NVEM_12_XIX_HCP5_CANFD01]
    BMC_HV_XIX_PNC_30_EnergyManagement_Tx: communication-direction=OUT, communication-mode=Transmit_30_EnergyManagement, i-signal-i-pdus=[BMC_HV_01_XIX_HCP5_CANFD01_E2E, BMC_HV_02_XIX_HCP5_CANFD01_E2E]
    BMC_HV_XIX_PNC_40_Diagnosis_Energy_Rx: communication-direction=IN, communication-mode=Receive_40_Diagnosis_Energy, i-signal-i-pdus=[DCDC_NV_CALID_XIX_HCP5_CANFD01, DCDC_NV_CVN_XIX_HCP5_CANFD01]
    BMC_HV_XIX_PNC_40_Diagnosis_Energy_Tx: communication-direction=OUT, communication-mode=Transmit_40_Diagnosis_Energy
      i-signal-i-pdus:
        BMC_HV_02_XIX_HCP5_CANFD01_E2E
        DS_Hybrid_01_XIX_HCP5_CANFD01
        KN_Hybrid_01_XIX_HCP5_CANFD01
        OBD_Hybrid_01_XIX_HCP5_CANFD01
package /Gateway
  gateway BMC_HV: ecu=BMC_HV
    i-pdu-mappings:
      source-i-pdu=CHNL/PT_DEV_BJB_Resp_FF, target-i-pdu=CHNL/PT_DEV_BJB_Resp_FF
      source-i-pdu=CHNL/PT_DIA_BJB_Resp, target-i-pdu=CHNL/PT_DIA_BJB_Resp
      source-i-pdu=CHNL/PT_DIA_UI2Sens01_Resp, target-i-pdu=CHNL/PT_DIA_UI2Sens01_Resp
      source-i-pdu=CHNL/PT_DIA_UI2Sens02_Resp, target-i-pdu=CHNL/PT_DIA_UI2Sens02_Resp
      source-i-pdu=CHNL/PT_OBDC_SSN_BJB_Resp, target-i-pdu=CHNL/PT_OBDC_SSN_BJB_Resp
      source-i-pdu=CHNL/PT_OBDC_SSN_UI2Sens01_Resp, target-i-pdu=CHNL/PT_OBDC_SSN_UI2Sens01_Resp
      source-i-pdu=CHNL/PT_OBDC_SSN_UI2Sens02_Resp, target-i-pdu=CHNL/PT_OBDC_SSN_UI2Sens02_Resp
      source-i-pdu=CHNL/PT_XCP_BJB_DTO_01, target-i-pdu=CHNL/PT_XCP_BJB_DTO_01
      source-i-pdu=CHNL/PT_ClampControl_01, target-i-pdu=CHNL/PT_ClampControl_01
      source-i-pdu=CHNL/PT_DEV_BJB_Req_01, target-i-pdu=CHNL/PT_DEV_BJB_Req_01
      source-i-pdu=CHNL/PT_DIA_BJB_Req, target-i-pdu=CHNL/PT_DIA_BJB_Req
      source-i-pdu=CHNL/PT_DIA_UI2Sens01_Req, target-i-pdu=CHNL/PT_DIA_UI2Sens01_Req
      source-i-pdu=CHNL/PT_DIA_UI2Sens02_Req, target-i-pdu=CHNL/PT_DIA_UI2Sens02_Req
      source-i-pdu=PT_HCP5_CANFD01_XIX_TPCHType_CANFD_ISO_Diagnose_XIX_0x1C410000_XIX_Functional, target-i-pdu=PT_BMC_CAN01_XIX_TPCHType_CANHS_ISO_Diagnose_XIX_0x700_XIX_Functional
      source-i-pdu=PT_HCP5_CANFD01_XIX_TPCHType_CANFD_OBDC_Diagnose_XIX_0x1C410200_XIX_Functional, target-i-pdu=PT_BMC_CAN01_XIX_TPCHType_CANHS_OBDC_Diagnose_XIX_0x17FD0200_XIX_Functional
      source-i-pdu=CHNL/PT_ISO_Funktionaler_Req_All, target-i-pdu=CHNL/PT_ISO_Funktionaler_Req_All
      source-i-pdu=CHNL/PT_OBD_03, target-i-pdu=CHNL/PT_OBD_03
      source-i-pdu=CHNL/PT_OBD_04, target-i-pdu=CHNL/PT_OBD_04
      source-i-pdu=CHNL/PT_OBDC_SSN_BJB_Req, target-i-pdu=CHNL/PT_OBDC_SSN_BJB_Req
      source-i-pdu=CHNL/PT_OBDC_SSN_UI2Sens01_Req, target-i-pdu=CHNL/PT_OBDC_SSN_UI2Sens01_Req
      source-i-pdu=CHNL/PT_OBDC_SSN_UI2Sens02_Req, target-i-pdu=CHNL/PT_OBDC_SSN_UI2Sens02_Req
      source-i-pdu=CHNL/PT_OBDx_allOBD_Req, target-i-pdu=CHNL/PT_OBDx_allOBD_Req
      source-i-pdu=CHNL/PT_ORU_01, target-i-pdu=CHNL/PT_ORU_01
      source-i-pdu=PT_ORU_Control_A_01_E2E, target-i-pdu=PT_ORU_Control_A_01
      source-i-pdu=PT_ORU_Control_D_01_E2E, target-i-pdu=PT_ORU_Control_D_01
      source-i-pdu=PT_OTAMC_D_01_E2E, target-i-pdu=PT_OTAMC_D_01
      source-i-pdu=CHNL/PT_Systeminfo_01, target-i-pdu=CHNL/PT_Systeminfo_01
      source-i-pdu=CHNL/PT_XCP_BJB_CRO_01, target-i-pdu=CHNL/PT_XCP_BJB_CRO_01
package /E2E
  end to end protection set E2E_ProtectionSet
    21 x end to end protection:
      E2E_Protection_BJB_10_XIX_BMC_CAN01: end-to-end-profile={category=PROFILE_02, data-ids=[0x91, 0xf6, 0xe0, 0xe4, 0xdd, 0xfa, 0x7b, 0xe7, 0xf3, 0x38, 0x74, 0x29, 0x30, 0xf, 0x81, 0x8d], data-length=64, crc-offset=0, counter-offset=8}, end-to-end-protection-i-signal-i-pdu{data-offset=0, i-signal-group=SG_BJB_10_XIX_BMC_CAN01, i-signal-i-pdu=BJB_10_XIX_BMC_CAN01_E2E}
      E2E_Protection_BJB_11_XIX_BMC_CAN01: end-to-end-profile={category=PROFILE_02, data-ids=[0xf6, 0xe4, 0xfa, 0xe7, 0x38, 0x29, 0xf, 0x8d, 0x8, 0x26, 0x9d, 0xec, 0x44, 0xa6, 0x55, 0xd5], data-length=64, crc-offset=0, counter-offset=8}, end-to-end-protection-i-signal-i-pdu{data-offset=0, i-signal-group=SG_BJB_11_XIX_BMC_CAN01, i-signal-i-pdu=BJB_11_XIX_BMC_CAN01_E2E}
      E2E_Protection_BJB_12_XIX_BMC_CAN01: end-to-end-profile={category=PROFILE_02, data-ids=[0x7, 0x62, 0x6, 0xe8, 0x91, 0x35, 0x47, 0xd, 0x54, 0xf6, 0x4d, 0xaa, 0x21, 0x4, 0xe0, 0xce], data-length=64, crc-offset=0, counter-offset=8}, end-to-end-protection-i-signal-i-pdu{data-offset=0, i-signal-group=SG_BJB_12_XIX_BMC_CAN01, i-signal-i-pdu=BJB_12_XIX_BMC_CAN01_E2E}
      E2E_Protection_BJB_13_XIX_BMC_CAN01: end-to-end-profile={category=PROFILE_02, data-ids=[0x6b, 0x6c, 0x7a, 0x91, 0x4f, 0x6a, 0xaf, 0xf6, 0xcd, 0x11, 0x20, 0xe0, 0x7f, 0x2b, 0x1c, 0xe4], data-length=64, crc-offset=0, counter-offset=8}, end-to-end-protection-i-signal-i-pdu{data-offset=0, i-signal-group=SG_BJB_13_XIX_BMC_CAN01, i-signal-i-pdu=BJB_13_XIX_BMC_CAN01_E2E}
      E2E_Protection_BMC_HV_01_XIX_HCP5_CANFD01: end-to-end-profile={category=PROFILE_02, data-ids=[0x18, 0x71, 0x10, 0x8d, 0xd7, 0xaa, 0xb0, 0x78, 0xac, 0x12, 0xae, 0xc, 0xdd, 0xf1, 0x85, 0x68], data-length=128, crc-offset=0, counter-offset=8}, end-to-end-protection-i-signal-i-pdu{data-offset=0, i-signal-group=SG_BMC_HV_01_XIX_HCP5_CANFD01, i-signal-i-pdu=BMC_HV_01_XIX_HCP5_CANFD01_E2E}
      E2E_Protection_BMC_HV_02_XIX_HCP5_CANFD01: end-to-end-profile={category=PROFILE_02, data-ids=[0x50, 0xa6, 0x7d, 0x6b, 0x9f, 0xa9, 0xc6, 0x3e, 0x46, 0x72, 0x94, 0x4d, 0x49, 0x40, 0x71, 0x9d], data-length=352, crc-offset=0, counter-offset=8}, end-to-end-protection-i-signal-i-pdu{data-offset=0, i-signal-group=SG_BMC_HV_02_XIX_HCP5_CANFD01, i-signal-i-pdu=BMC_HV_02_XIX_HCP5_CANFD01_E2E}
      E2E_Protection_BMC_HV_04_XIX_BMC_CAN01: end-to-end-profile={category=PROFILE_02, data-ids=[0x20, 0x5, 0xcc, 0x8, 0xef, 0x69, 0xb0, 0xc8, 0x3c, 0x60, 0xeb, 0x76, 0x91, 0x27, 0x4, 0x2], data-length=64, crc-offset=0, counter-offset=8}, end-to-end-protection-i-signal-i-pdu{data-offset=0, i-signal-group=SG_BMC_HV_04_XIX_BMC_CAN01, i-signal-i-pdu=BMC_HV_04_XIX_BMC_CAN01_E2E}
      E2E_Protection_BMC_HV_10_XIX_BMC_CAN01: end-to-end-profile={category=PROFILE_02, data-ids=[0x9c, 0x6d, 0x7d, 0x88, 0x4e, 0x13, 0x3c, 0x45, 0x74, 0xd9, 0x9, 0x77, 0xc5, 0xf0, 0xd, 0xad], data-length=64, crc-offset=0, counter-offset=8}, end-to-end-protection-i-signal-i-pdu{data-offset=0, i-signal-group=SG_BMC_HV_10_XIX_BMC_CAN01, i-signal-i-pdu=BMC_HV_10_XIX_BMC_CAN01_E2E}
      E2E_Protection_BMC_HV_11_XIX_BMC_CAN01: end-to-end-profile={category=PROFILE_02, data-ids=[0xb8, 0x47, 0x88, 0x4, 0x2b, 0x45, 0x55, 0x96, 0x77, 0x7b, 0xdb, 0xad, 0x32, 0x94, 0x50, 0x84], data-length=64, crc-offset=0, counter-offset=8}, end-to-end-protection-i-signal-i-pdu{data-offset=0, i-signal-group=SG_BMC_HV_11_XIX_BMC_CAN01, i-signal-i-pdu=BMC_HV_11_XIX_BMC_CAN01_E2E}
      E2E_Protection_BMC_HV_12_XIX_BMC_CAN01: end-to-end-profile={category=PROFILE_02, data-ids=[0xde, 0x17, 0x2, 0x7a, 0xc9, 0x6f, 0xd2, 0x6a, 0x4a, 0xb0, 0x9f, 0xcd, 0x65, 0x4e, 0xb4, 0xe0], data-length=64, crc-offset=0, counter-offset=8}, end-to-end-protection-i-signal-i-pdu{data-offset=0, i-signal-group=SG_BMC_HV_12_XIX_BMC_CAN01, i-signal-i-pdu=BMC_HV_12_XIX_BMC_CAN01_E2E}
      E2E_Protection_BMC_HV_13_XIX_BMC_CAN01: end-to-end-profile={category=PROFILE_02, data-ids=[0x86, 0x49, 0xd2, 0xaf, 0x9e, 0x4e, 0xcf, 0x2b, 0xe8, 0xf9, 0xe5, 0xd9, 0xc6, 0xd4, 0x68, 0x7b], data-length=64, crc-offset=0, counter-offset=8}, end-to-end-protection-i-signal-i-pdu{data-offset=0, i-signal-group=SG_BMC_HV_13_XIX_BMC_CAN01, i-signal-i-pdu=BMC_HV_13_XIX_BMC_CAN01_E2E}
      E2E_Protection_HVK_03_XIX_HCP5_CANFD01: end-to-end-profile={category=PROFILE_02, data-ids=[0xe4, 0xcb, 0xc4, 0x5a, 0x4c, 0x4d, 0x3, 0x2e, 0xb3, 0xbb, 0x62, 0xc6, 0x36, 0x93, 0xf3, 0x98], data-length=64, crc-offset=0, counter-offset=8}, end-to-end-protection-i-signal-i-pdu{data-offset=0, i-signal-group=SG_HVK_03_XIX_HCP5_CANFD01, i-signal-i-pdu=HVK_03_XIX_HCP5_CANFD01_E2E}
      E2E_Protection_HVLM_14_XIX_HCP5_CANFD01: end-to-end-profile={category=PROFILE_02, data-ids=[0xc1, 0x3b, 0x72, 0xe3, 0x93, 0x7d, 0x8c, 0x86, 0x60, 0x65, 0x12, 0x31, 0xe1, 0xbc, 0x1, 0x59], data-length=64, crc-offset=0, counter-offset=8}, end-to-end-protection-i-signal-i-pdu{data-offset=0, i-signal-group=SG_HVLM_14_XIX_HCP5_CANFD01, i-signal-i-pdu=HVLM_14_XIX_HCP5_CANFD01_E2E}
      E2E_Protection_ORU_Control_A_01_XIX_HCP5_CANFD01: end-to-end-profile={category=PROFILE_02, data-ids=[0x97, 0x70, 0x84, 0xb4, 0xb8, 0xe7, 0x20, 0x7c, 0xe, 0x40, 0x93, 0xd, 0x4e, 0x5, 0x5b, 0x95], data-length=64, crc-offset=0, counter-offset=8}, end-to-end-protection-i-signal-i-pdu{data-offset=0, i-signal-group=SG_ORU_Control_A_01_XIX_HCP5_CANFD01, i-signal-i-pdu=ORU_Control_A_01_XIX_HCP5_CANFD01_E2E}
      E2E_Protection_ORU_Control_D_01_XIX_HCP5_CANFD01: end-to-end-profile={category=PROFILE_02, data-ids=[0x92, 0x1b, 0xc6, 0x91, 0x29, 0x5a, 0x4e, 0xf0, 0x6e, 0x43, 0x80, 0x28, 0xee, 0xa3, 0xc8, 0x3e], data-length=64, crc-offset=0, counter-offset=8}, end-to-end-protection-i-signal-i-pdu{data-offset=0, i-signal-group=SG_ORU_Control_D_01_XIX_HCP5_CANFD01, i-signal-i-pdu=ORU_Control_D_01_XIX_HCP5_CANFD01_E2E}
      E2E_Protection_OTAMC_D_01_XIX_HCP5_CANFD01: end-to-end-profile={category=PROFILE_02, data-ids=[0x5f, 0x18, 0xf5, 0x71, 0x82, 0x10, 0x93, 0x8d, 0x4c, 0xd7, 0x6e, 0xaa, 0xd6, 0xb0, 0xb7, 0x78], data-length=32, crc-offset=0, counter-offset=8}, end-to-end-protection-i-signal-i-pdu{data-offset=0, i-signal-group=SG_OTAMC_D_01_XIX_HCP5_CANFD01, i-signal-i-pdu=OTAMC_D_01_XIX_HCP5_CANFD01_E2E}
      E2E_Protection_UI1_01_XIX_BMC_CAN01: end-to-end-profile={category=PROFILE_02, data-ids=[0xc0, 0xc7, 0x38, 0x3, 0xb, 0x96, 0xca, 0x93, 0x35, 0x39, 0x81, 0xb2, 0x2, 0xa3, 0xed, 0x65], data-length=64, crc-offset=0, counter-offset=8}, end-to-end-protection-i-signal-i-pdu{data-offset=0, i-signal-group=SG_UI1_01_XIX_BMC_CAN01, i-signal-i-pdu=UI1_01_XIX_BMC_CAN01_E2E}
      E2E_Protection_UI1_02_XIX_BMC_CAN01: end-to-end-profile={category=PROFILE_02, data-ids=[0x13, 0xd2, 0xb5, 0x5c, 0xc2, 0x16, 0x5b, 0x56, 0x91, 0xe1, 0x53, 0x55, 0xcf, 0x3e, 0xd3, 0x5d], data-length=64, crc-offset=0, counter-offset=8}, end-to-end-protection-i-signal-i-pdu{data-offset=0, i-signal-group=SG_UI1_02_XIX_BMC_CAN01, i-signal-i-pdu=UI1_02_XIX_BMC_CAN01_E2E}
      E2E_Protection_UI2_01_XIX_BMC_CAN01: end-to-end-profile={category=PROFILE_02, data-ids=[0x25, 0xd, 0x57, 0x89, 0xb5, 0xc3, 0x8b, 0x67, 0xac, 0x1, 0x6a, 0xb, 0x90, 0x92, 0xc1, 0x4c], data-length=64, crc-offset=0, counter-offset=8}, end-to-end-protection-i-signal-i-pdu{data-offset=0, i-signal-group=SG_UI2_01_XIX_BMC_CAN01, i-signal-i-pdu=UI2_01_XIX_BMC_CAN01_E2E}
      E2E_Protection_UI2_02_XIX_BMC_CAN01: end-to-end-profile={category=PROFILE_02, data-ids=[0x4e, 0xa3, 0x1f, 0xf, 0x13, 0x72, 0xd0, 0xda, 0x3c, 0x33, 0xe8, 0x11, 0x45, 0xbd, 0x7e, 0x4b], data-length=64, crc-offset=0, counter-offset=8}, end-to-end-protection-i-signal-i-pdu{data-offset=0, i-signal-group=SG_UI2_02_XIX_BMC_CAN01, i-signal-i-pdu=UI2_02_XIX_BMC_CAN01_E2E}
      E2E_Protection_UI2_03_XIX_BMC_CAN01: end-to-end-profile={category=PROFILE_02, data-ids=[0x5e, 0xed, 0x2e, 0x2d, 0xde, 0x98, 0x8b, 0x8a, 0x7f, 0xe, 0xef, 0xf5, 0x9d, 0x74, 0xa7, 0x87], data-length=64, crc-offset=0, counter-offset=8}, end-to-end-protection-i-signal-i-pdu{data-offset=0, i-signal-group=SG_UI2_03_XIX_BMC_CAN01, i-signal-i-pdu=UI2_03_XIX_BMC_CAN01_E2E}
